VERSION "HNNBNNNYNNNNNNNNNNNNNNNNNNNNNNNNNNNNNNNNNN/4/%%%/4/'%**4NNN///"

NS_ :

BS_:

BU_: BAP_Tester BMS_NV_12V Gateway_Max Klima

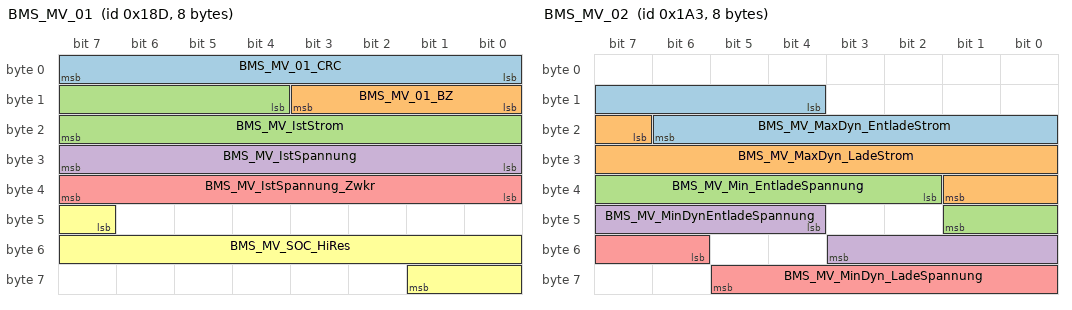
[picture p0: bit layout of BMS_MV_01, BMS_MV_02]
BO_ 397 BMS_MV_01: 8 Vector__XXX
 SG_ BMS_MV_01_CRC : 0|8@1+ (1,0) [0|255] ""  Gateway_Max
 SG_ BMS_MV_01_BZ : 8|4@1+ (1,0) [0|15] ""  Gateway_Max
 SG_ BMS_MV_IstStrom : 12|12@1+ (1,-2047) [-2047|2046] "Unit_Amper"  Gateway_Max
 SG_ BMS_MV_IstSpannung : 24|8@1+ (0.25,0) [0.00|63.25] "Unit_Volt"  Gateway_Max
 SG_ BMS_MV_IstSpannung_Zwkr : 32|8@1+ (0.25,0) [0.00|63.25] "Unit_Volt"  Gateway_Max
 SG_ BMS_MV_SOC_HiRes : 47|11@1+ (0.05,0) [0.00|100.00] "Unit_PerCent"  Gateway_Max

BO_ 419 BMS_MV_02: 8 Vector__XXX
 SG_ BMS_MV_MaxDyn_EntladeStrom : 12|11@1+ (1,0) [0|2045] "Unit_Amper"  Gateway_Max
 SG_ BMS_MV_MaxDyn_LadeStrom : 23|11@1+ (1,0) [0|2045] "Unit_Amper"  Gateway_Max
 SG_ BMS_MV_Min_EntladeSpannung : 34|8@1+ (0.25,0) [0.00|63.25] "Unit_Volt"  Gateway_Max
 SG_ BMS_MV_MinDynEntladeSpannung : 44|8@1+ (0.25,0) [0.00|63.25] "Unit_Volt"  Gateway_Max
 SG_ BMS_MV_MinDyn_LadeSpannung : 54|8@1+ (0.25,0) [0.00|63.25] "Unit_Volt"  Gateway_Max

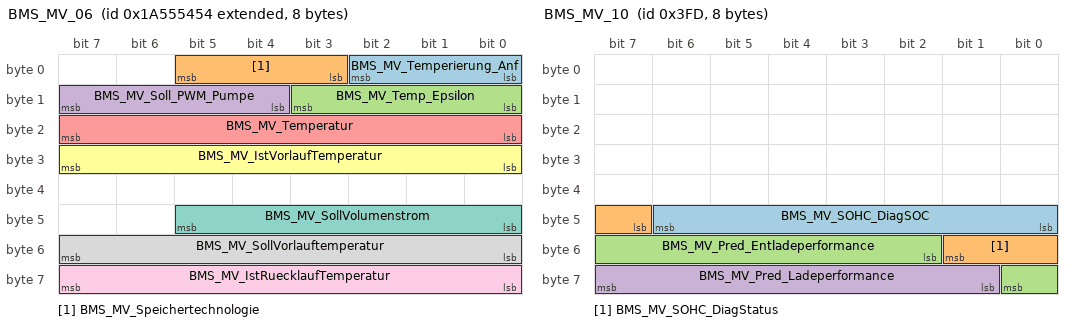
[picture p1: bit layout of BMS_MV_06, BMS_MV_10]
BO_ 2589283412 BMS_MV_06: 8 Vector__XXX
 SG_ BMS_MV_Temperierung_Anf : 0|3@1+ (1.0,0.0) [0.0|7] ""  Gateway_Max
 SG_ BMS_MV_Speichertechnologie : 3|3@1+ (1.0,0.0) [0.0|7] ""  Gateway_Max
 SG_ BMS_MV_Temp_Epsilon : 8|4@1+ (1,-15) [-15|0] "Unit_DegreCelsi"  Gateway_Max
 SG_ BMS_MV_Soll_PWM_Pumpe : 12|4@1+ (10,0) [0|100] "Unit_PerCent"  Gateway_Max
 SG_ BMS_MV_Temperatur : 16|8@1+ (0.5,-40) [-40.0|86.5] "Unit_DegreCelsi"  Gateway_Max
 SG_ BMS_MV_IstVorlaufTemperatur : 24|8@1+ (0.5,-40) [-40.0|86.5] "Unit_DegreCelsi"  Gateway_Max
 SG_ BMS_MV_SollVolumenstrom : 40|6@1+ (1,0) [0|61] ""  Gateway_Max
 SG_ BMS_MV_SollVorlauftemperatur : 48|8@1+ (0.5,-40) [-40.0|86.5] "Unit_DegreCelsi"  Gateway_Max
 SG_ BMS_MV_IstRuecklaufTemperatur : 56|8@1+ (0.5,-40) [-40.0|86.5] "Unit_DegreCelsi"  Gateway_Max

BO_ 2589283608 BMS_MV_07: 8 Vector__XXX
 SG_ BMS_MV_Energieinhalt : 12|11@1+ (1,0) [0|2045] "Unit_WattHour"  Gateway_Max
 SG_ BMS_MV_MaxEnergieinhalt : 32|11@1+ (1,0) [0|2045] "Unit_WattHour"  Gateway_Max

BO_ 2589283606 BMS_MV_09: 8 Vector__XXX
 SG_ BMS_MV_SOC_Kaltstart : 43|11@1+ (0.05,0) [0.00|100.00] "Unit_PerCent"  Gateway_Max
 SG_ BMS_MV_max_Grenz_SOC : 54|5@1+ (1,70) [70|100] "Unit_PerCent"  Gateway_Max

BO_ 1021 BMS_MV_10: 8 Vector__XXX
 SG_ BMS_MV_SOHC_DiagSOC : 40|7@1+ (1,0) [0|100] "Unit_PerCent"  Gateway_Max
 SG_ BMS_MV_SOHC_DiagStatus : 47|3@1+ (1.0,0.0) [0.0|7] ""  Gateway_Max
 SG_ BMS_MV_Pred_Entladeperformance : 50|7@1+ (1,0) [0|100] "Unit_PerCent"  Gateway_Max
 SG_ BMS_MV_Pred_Ladeperformance : 57|7@1+ (1,0) [0|100] "Unit_PerCent"  Gateway_Max

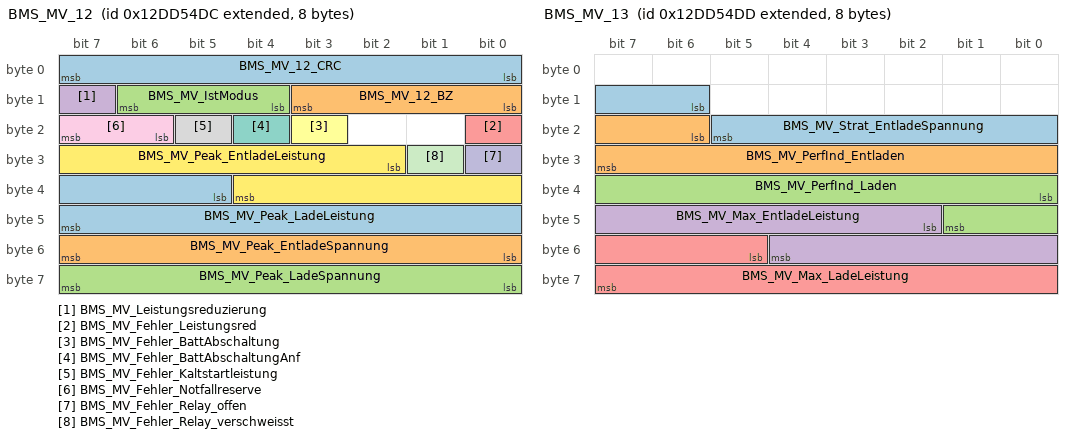
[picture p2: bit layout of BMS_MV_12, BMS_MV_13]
BO_ 2463978716 BMS_MV_12: 8 Vector__XXX
 SG_ BMS_MV_12_CRC : 0|8@1+ (1,0) [0|255] ""  Gateway_Max
 SG_ BMS_MV_12_BZ : 8|4@1+ (1,0) [0|15] ""  Gateway_Max
 SG_ BMS_MV_IstModus : 12|3@1+ (1.0,0.0) [0.0|7] ""  Gateway_Max
 SG_ BMS_MV_Leistungsreduzierung : 15|1@1+ (1.0,0.0) [0.0|1] ""  Gateway_Max
 SG_ BMS_MV_Fehler_Leistungsred : 16|1@1+ (1.0,0.0) [0.0|1] ""  Gateway_Max
 SG_ BMS_MV_Fehler_BattAbschaltung : 19|1@1+ (1.0,0.0) [0.0|1] ""  Gateway_Max
 SG_ BMS_MV_Fehler_BattAbschaltungAnf : 20|1@1+ (1.0,0.0) [0.0|1] ""  Gateway_Max
 SG_ BMS_MV_Fehler_Kaltstartleistung : 21|1@1+ (1.0,0.0) [0.0|1] ""  Gateway_Max
 SG_ BMS_MV_Fehler_Notfallreserve : 22|2@1+ (1.0,0.0) [0.0|3] ""  Gateway_Max
 SG_ BMS_MV_Fehler_Relay_offen : 24|1@1+ (1.0,0.0) [0.0|1] ""  Gateway_Max
 SG_ BMS_MV_Fehler_Relay_verschweisst : 25|1@1+ (1.0,0.0) [0.0|1] ""  Gateway_Max
 SG_ BMS_MV_Peak_EntladeLeistung : 26|11@1+ (50,0) [0|102250] "Unit_Watt"  Gateway_Max
 SG_ BMS_MV_Peak_LadeLeistung : 37|11@1+ (50,0) [0|102250] "Unit_Watt"  Gateway_Max
 SG_ BMS_MV_Peak_EntladeSpannung : 48|8@1+ (0.25,0) [0.00|63.25] "Unit_Volt"  Gateway_Max
 SG_ BMS_MV_Peak_LadeSpannung : 56|8@1+ (0.25,0) [0.00|63.25] "Unit_Volt"  Gateway_Max

BO_ 2463978717 BMS_MV_13: 8 Vector__XXX
 SG_ BMS_MV_Strat_EntladeSpannung : 14|8@1+ (0.25,0) [0.00|63.25] "Unit_Volt"  Gateway_Max
 SG_ BMS_MV_PerfInd_Entladen : 22|10@1+ (0.2,0) [0.0|200.0] "Unit_PerCent"  Gateway_Max
 SG_ BMS_MV_PerfInd_Laden : 32|10@1+ (0.2,0) [0.0|200.0] "Unit_PerCent"  Gateway_Max
 SG_ BMS_MV_Max_EntladeLeistung : 42|11@1+ (50,0) [0|102250] "Unit_Watt"  Gateway_Max
 SG_ BMS_MV_Max_LadeLeistung : 53|11@1+ (50,0) [0|102250] "Unit_Watt"  Gateway_Max

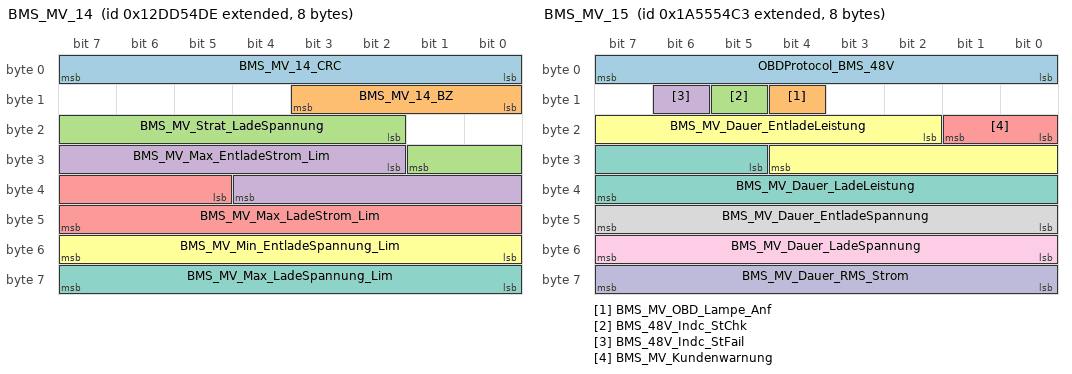
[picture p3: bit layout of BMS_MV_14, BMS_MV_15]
BO_ 2463978718 BMS_MV_14: 8 Vector__XXX
 SG_ BMS_MV_14_CRC : 0|8@1+ (1,0) [0|255] ""  Gateway_Max
 SG_ BMS_MV_14_BZ : 8|4@1+ (1,0) [0|15] ""  Gateway_Max
 SG_ BMS_MV_Strat_LadeSpannung : 18|8@1+ (0.25,0) [0.00|63.25] "Unit_Volt"  Gateway_Max
 SG_ BMS_MV_Max_EntladeStrom_Lim : 26|11@1+ (1,0) [0|2045] "Unit_Amper"  Gateway_Max
 SG_ BMS_MV_Max_LadeStrom_Lim : 37|11@1+ (1,0) [0|2045] "Unit_Amper"  Gateway_Max
 SG_ BMS_MV_Min_EntladeSpannung_Lim : 48|8@1+ (0.25,0) [0.00|63.25] "Unit_Volt"  Gateway_Max
 SG_ BMS_MV_Max_LadeSpannung_Lim : 56|8@1+ (0.25,0) [0.00|63.25] "Unit_Volt"  Gateway_Max

BO_ 2589283523 BMS_MV_15: 8 Vector__XXX
 SG_ OBDProtocol_BMS_48V : 0|8@1+ (1.0,0.0) [0.0|255] ""  Gateway_Max
 SG_ BMS_MV_OBD_Lampe_Anf : 12|1@1+ (1.0,0.0) [0.0|1] ""  Gateway_Max
 SG_ BMS_48V_Indc_StChk : 13|1@1+ (1.0,0.0) [0.0|1] ""  Gateway_Max
 SG_ BMS_48V_Indc_StFail : 14|1@1+ (1.0,0.0) [0.0|1] ""  Gateway_Max
 SG_ BMS_MV_Kundenwarnung : 16|2@1+ (1.0,0.0) [0.0|3] ""  Gateway_Max
 SG_ BMS_MV_Dauer_EntladeLeistung : 18|11@1+ (50,0) [0|102250] "Unit_Watt"  Gateway_Max
 SG_ BMS_MV_Dauer_LadeLeistung : 29|11@1+ (50,0) [0|102250] "Unit_Watt"  Gateway_Max
 SG_ BMS_MV_Dauer_EntladeSpannung : 40|8@1+ (0.25,0) [0.00|63.25] "Unit_Volt"  Gateway_Max
 SG_ BMS_MV_Dauer_LadeSpannung : 48|8@1+ (0.25,0) [0.00|63.25] "Unit_Volt"  Gateway_Max
 SG_ BMS_MV_Dauer_RMS_Strom : 56|8@1+ (1,0) [0|253] "Unit_Amper"  Gateway_Max

BO_ 2589283543 BMS_MV_15_SOK_Signatur: 8 Vector__XXX
 SG_ SOK_BMS_MV_15_Signatur : 0|64@1+ (1,0) [1|18446744073709551615] "Unit_None"  Gateway_Max

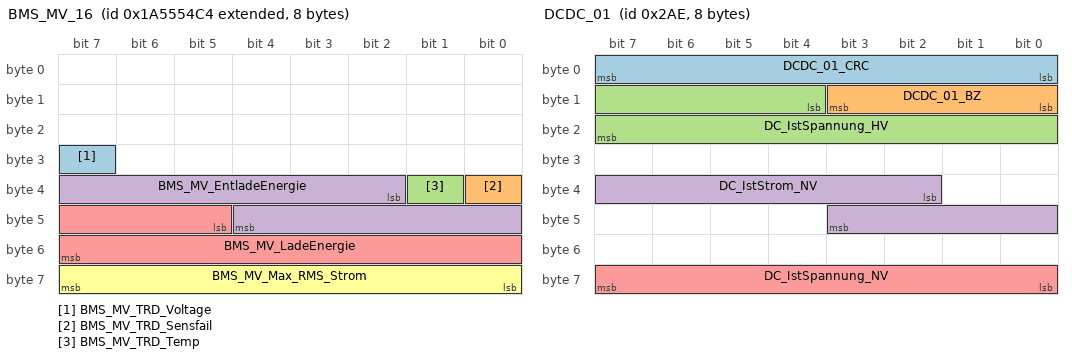
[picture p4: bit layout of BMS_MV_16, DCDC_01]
BO_ 2589283524 BMS_MV_16: 8 Vector__XXX
 SG_ BMS_MV_TRD_Voltage : 31|1@1+ (1.0,0.0) [0.0|1] ""  Gateway_Max
 SG_ BMS_MV_TRD_Sensfail : 32|1@1+ (1.0,0.0) [0.0|1] ""  Gateway_Max
 SG_ BMS_MV_TRD_Temp : 33|1@1+ (1.0,0.0) [0.0|1] ""  Gateway_Max
 SG_ BMS_MV_EntladeEnergie : 34|11@1+ (5,-5110) [-5110|5115] "Unit_WattHour"  Gateway_Max
 SG_ BMS_MV_LadeEnergie : 45|11@1+ (5,-5110) [-5110|5115] "Unit_WattHour"  Gateway_Max
 SG_ BMS_MV_Max_RMS_Strom : 56|8@1+ (1,0) [0|253] "Unit_Amper"  Gateway_Max

BO_ 2527679928 BMS_NV_11: 16 BMS_NV_12V
 SG_ BMS_NV_OBD_Lampe_Anf : 12|1@1+ (1.0,0.0) [0.0|1] ""  Gateway_Max
 SG_ BMS_NV_Indc_StChk : 13|1@1+ (1.0,0.0) [0.0|1] ""  Gateway_Max
 SG_ BMS_NV_Indc_StFail : 14|1@1+ (1.0,0.0) [0.0|1] ""  Gateway_Max
 SG_ OBDProtocol_BMS_NV : 16|8@1+ (1.0,0.0) [0.0|255] ""  Gateway_Max
 SG_ SOK_BMS_NV_11_Signatur : 64|64@1+ (1,0) [1|18446744073709551615] "Unit_None"  Gateway_Max

BO_ 2617128448 CCP_Klima_CRO_01: 8 Vector__XXX
 SG_ CCP_Klima_CRO_01_Data : 0|64@1+ (1,0) [0|1] ""  Klima

BO_ 2617128450 CCP_Klima_CRO_02: 8 Vector__XXX
 SG_ CCP_Klima_CRO_02_Data : 0|64@1+ (1,0) [0|1] ""  Klima

BO_ 2617128449 CCP_Klima_DTO_01: 8 Klima
 SG_ CCP_Klima_DTO_01_Data : 0|64@1+ (1,0) [0|1] ""  Vector__XXX

BO_ 902 Charisma_03: 8 Gateway_Max
 SG_ CHA_Charisma_Taste2_LED : 0|2@1+ (1.0,0.0) [0.0|3] ""  Vector__XXX
 SG_ CHA_ReqPrgDispSetup : 2|4@1+ (1.0,0.0) [0.0|15] ""  Vector__XXX
 SG_ CHA_Current_Mode_FPA : 6|6@1+ (1.0,0.0) [0.0|63] ""  Vector__XXX
 SG_ CHA_Eco_Charisma_LED : 12|2@1+ (1.0,0.0) [0.0|3] ""  Vector__XXX
 SG_ CHA_Fahrer_Umschaltung : 14|1@1+ (1.0,0.0) [0.0|1] ""  Klima
 SG_ CHA_EV_LED : 15|1@1+ (1.0,0.0) [0.0|1] ""  Vector__XXX
 SG_ CHA_Ziel_FahrPr_AMB : 16|4@1+ (1.0,0.0) [0.0|15] ""  Vector__XXX
 SG_ CHA_Ziel_FahrPr_IVB : 20|4@1+ (1.0,0.0) [0.0|15] ""  Vector__XXX
 SG_ CHA_Kombi_Texte : 24|4@1+ (1.0,0.0) [0.0|15] ""  Vector__XXX
 SG_ CHA_Ziel_FahrPr_KL : 28|4@1+ (1.0,0.0) [0.0|15] ""  Klima
 SG_ CHA_Ziel_FahrPr_HSP : 32|4@1+ (1.0,0.0) [0.0|15] ""  Vector__XXX
 SG_ CHA_StCurProfDft : 36|2@1+ (1.0,0.0) [0.0|3] ""  Vector__XXX
 SG_ CHA_Ziel_FahrPr_RWB : 40|4@1+ (1.0,0.0) [0.0|15] ""  Vector__XXX
 SG_ CHA_Ziel_FahrPr_03_01 : 44|4@1+ (1.0,0.0) [0.0|15] ""  Vector__XXX
 SG_ CHA_Ziel_FahrPr_03_02 : 48|4@1+ (1.0,0.0) [0.0|15] ""  Vector__XXX
 SG_ CHA_Current_Mode : 52|4@1+ (1.0,0.0) [0.0|15] ""  Vector__XXX
 SG_ CHA_Charge_LED : 57|1@1+ (1.0,0.0) [0.0|1] ""  Vector__XXX
 SG_ CHA_Offroad_LED : 58|2@1+ (1.0,0.0) [0.0|3] ""  Vector__XXX
 SG_ CHA_Kombi_Texte_02 : 60|4@1+ (1.0,0.0) [0.0|15] ""  Vector__XXX

BO_ 686 DCDC_01: 8 Vector__XXX
 SG_ DCDC_01_CRC : 0|8@1+ (1,0) [0|255] ""  Gateway_Max
 SG_ DCDC_01_BZ : 8|4@1+ (1,0) [0|15] ""  Gateway_Max
 SG_ DC_IstSpannung_HV : 12|12@1+ (0.25,0) [0.00|1023.25] "Unit_Volt"  Gateway_Max
 SG_ DC_IstStrom_NV : 34|10@1+ (1,-511) [-511|510] "Unit_Amper"  Gateway_Max
 SG_ DC_IstSpannung_NV : 56|8@1+ (0.1,0) [0.0|25.3] "Unit_Volt"  Gateway_Max

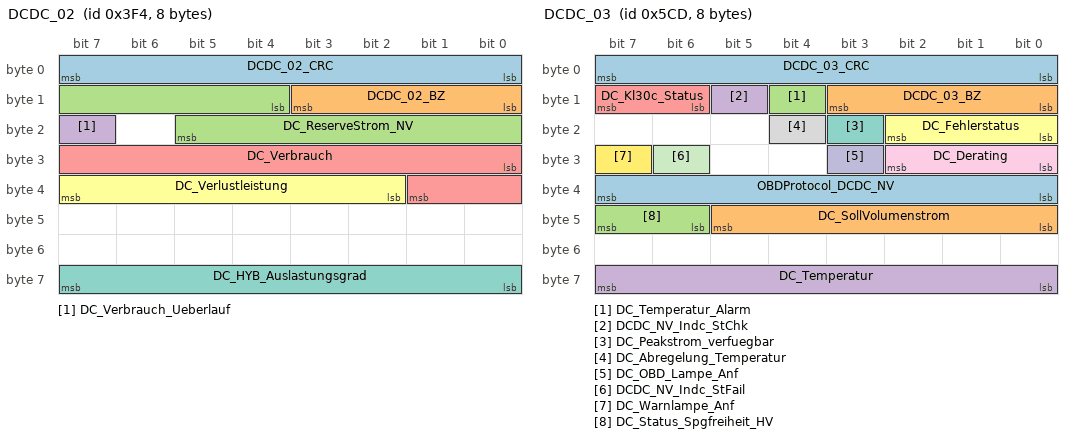
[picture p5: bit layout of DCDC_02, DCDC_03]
BO_ 1012 DCDC_02: 8 Vector__XXX
 SG_ DCDC_02_CRC : 0|8@1+ (1,0) [0|255] ""  Gateway_Max
 SG_ DCDC_02_BZ : 8|4@1+ (1,0) [0|15] ""  Gateway_Max
 SG_ DC_ReserveStrom_NV : 12|10@1+ (1,-511) [-511|510] "Unit_Amper"  Gateway_Max
 SG_ DC_Verbrauch_Ueberlauf : 23|1@1+ (1.0,0.0) [0.0|1] ""  Gateway_Max
 SG_ DC_Verbrauch : 24|10@1+ (1,0) [0|1023] "Unit_WattSecond"  Gateway_Max
 SG_ DC_Verlustleistung : 34|6@1+ (5,0) [0|305] "Unit_Watt"  Gateway_Max
 SG_ DC_HYB_Auslastungsgrad : 56|8@1+ (0.4,0) [0.0|100.0] "Unit_PerCent"  Gateway_Max

BO_ 1485 DCDC_03: 8 Vector__XXX
 SG_ DCDC_03_CRC : 0|8@1+ (1,0) [0|255] ""  Gateway_Max
 SG_ DCDC_03_BZ : 8|4@1+ (1,0) [0|15] ""  Gateway_Max
 SG_ DC_Temperatur_Alarm : 12|1@1+ (1.0,0.0) [0.0|1] ""  Gateway_Max
 SG_ DCDC_NV_Indc_StChk : 13|1@1+ (1.0,0.0) [0.0|1] ""  Gateway_Max
 SG_ DC_Kl30c_Status : 14|2@1+ (1.0,0.0) [0.0|3] ""  Gateway_Max
 SG_ DC_Fehlerstatus : 16|3@1+ (1.0,0.0) [0.0|7] ""  Gateway_Max
 SG_ DC_Peakstrom_verfuegbar : 19|1@1+ (1.0,0.0) [0.0|1] ""  Gateway_Max
 SG_ DC_Abregelung_Temperatur : 20|1@1+ (1.0,0.0) [0.0|1] ""  Gateway_Max
 SG_ DC_Derating : 24|3@1+ (1.0,0.0) [0.0|7] ""  Gateway_Max
 SG_ DC_OBD_Lampe_Anf : 27|1@1+ (1.0,0.0) [0.0|1] ""  Gateway_Max
 SG_ DCDC_NV_Indc_StFail : 30|1@1+ (1.0,0.0) [0.0|1] ""  Gateway_Max
 SG_ DC_Warnlampe_Anf : 31|1@1+ (1.0,0.0) [0.0|1] ""  Gateway_Max
 SG_ OBDProtocol_DCDC_NV : 32|8@1+ (1.0,0.0) [0.0|255] ""  Gateway_Max
 SG_ DC_SollVolumenstrom : 40|6@1+ (0.5,0) [0.0|30.5] "Unit_LiterPerMinut"  Gateway_Max
 SG_ DC_Status_Spgfreiheit_HV : 46|2@1+ (1.0,0.0) [0.0|3] ""  Gateway_Max
 SG_ DC_Temperatur : 56|8@1+ (1,-40) [-40|213] "Unit_DegreCelsi"  Gateway_Max

BO_ 1486 DCDC_03_SOK_Signatur: 8 Vector__XXX
 SG_ SOK_DCDC_03_Signatur : 0|64@1+ (1,0) [1|18446744073709551615] "Unit_None"  Gateway_Max

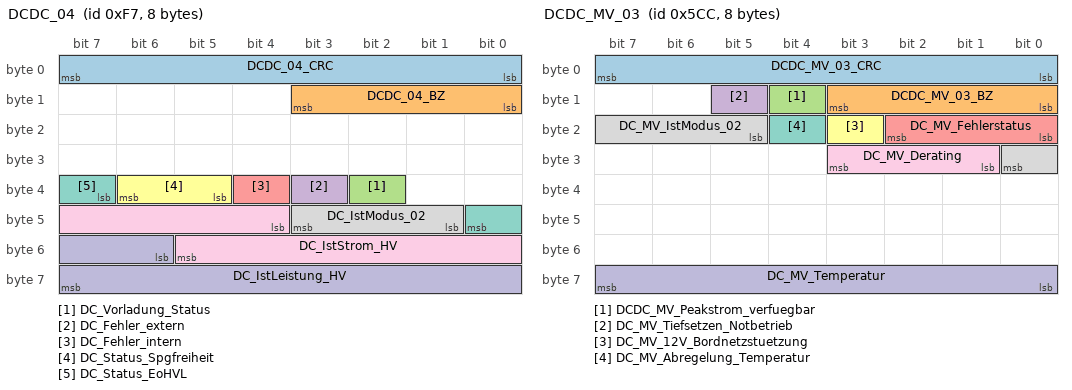
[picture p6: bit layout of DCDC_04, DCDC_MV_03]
BO_ 247 DCDC_04: 8 Vector__XXX
 SG_ DCDC_04_CRC : 0|8@1+ (1,0) [0|255] ""  Gateway_Max
 SG_ DCDC_04_BZ : 8|4@1+ (1,0) [0|15] ""  Gateway_Max
 SG_ DC_Vorladung_Status : 34|1@1+ (1.0,0.0) [0.0|1] ""  Gateway_Max
 SG_ DC_Fehler_extern : 35|1@1+ (1.0,0.0) [0.0|1] ""  Gateway_Max
 SG_ DC_Fehler_intern : 36|1@1+ (1.0,0.0) [0.0|1] ""  Gateway_Max
 SG_ DC_Status_Spgfreiheit : 37|2@1+ (1.0,0.0) [0.0|3] ""  Gateway_Max
 SG_ DC_Status_EoHVL : 39|2@1+ (1.0,0.0) [0.0|3] ""  Gateway_Max
 SG_ DC_IstModus_02 : 41|3@1+ (1.0,0.0) [0.0|7] ""  Gateway_Max
 SG_ DC_IstStrom_HV : 44|10@1+ (0.1,-51.1) [-51.1|51.0] "Unit_Amper"  Gateway_Max
 SG_ DC_IstLeistung_HV : 54|10@1+ (10,-4000) [-4000|6210] "Unit_Watt"  Gateway_Max

BO_ 1484 DCDC_MV_03: 8 Vector__XXX
 SG_ DCDC_MV_03_CRC : 0|8@1+ (1,0) [0|255] ""  Gateway_Max
 SG_ DCDC_MV_03_BZ : 8|4@1+ (1,0) [0|15] ""  Gateway_Max
 SG_ DCDC_MV_Peakstrom_verfuegbar : 12|1@1+ (1.0,0.0) [0.0|1] ""  Gateway_Max
 SG_ DC_MV_Tiefsetzen_Notbetrieb : 13|1@1+ (1.0,0.0) [0.0|1] ""  Gateway_Max
 SG_ DC_MV_Fehlerstatus : 16|3@1+ (1.0,0.0) [0.0|7] ""  Gateway_Max
 SG_ DC_MV_12V_Bordnetzstuetzung : 19|1@1+ (1.0,0.0) [0.0|1] ""  Gateway_Max
 SG_ DC_MV_Abregelung_Temperatur : 20|1@1+ (1.0,0.0) [0.0|1] ""  Gateway_Max
 SG_ DC_MV_IstModus_02 : 21|4@1+ (1.0,0.0) [0.0|15] ""  Gateway_Max
 SG_ DC_MV_Derating : 25|3@1+ (1.0,0.0) [0.0|7] ""  Gateway_Max
 SG_ DC_MV_Temperatur : 56|8@1+ (1,-40) [-40|213] "Unit_DegreCelsi"  Gateway_Max

BO_ 2617127464 DEV_Klima_BET_Req_01: 8 Vector__XXX
 SG_ DEV_Klima_BET_Req_01_Data : 0|64@1+ (1.0,0.0) [0.0|18446744073709551615] ""  Klima

BO_ 2617127465 DEV_Klima_BET_Resp_01: 8 Klima
 SG_ DEV_Klima_BET_Resp_01_Data : 0|64@1+ (1.0,0.0) [0.0|18446744073709551615] ""  Vector__XXX

BO_ 2617127424 DEV_Klima_Tx_00: 8 Klima
 SG_ DEV_Klima_Tx_00_Data : 0|64@1+ (1.0,0.0) [0.0|18446744073709551615] ""  Vector__XXX

BO_ 2617127425 DEV_Klima_Tx_01: 8 Klima
 SG_ DEV_Klima_Tx_01_Data : 0|64@1+ (1.0,0.0) [0.0|18446744073709551615] ""  Vector__XXX

BO_ 2617127426 DEV_Klima_Tx_02: 8 Klima
 SG_ DEV_Klima_Tx_02_Data : 0|64@1+ (1.0,0.0) [0.0|18446744073709551615] ""  Vector__XXX

BO_ 2617127427 DEV_Klima_Tx_03: 8 Klima
 SG_ DEV_Klima_Tx_03_Data : 0|64@1+ (1.0,0.0) [0.0|18446744073709551615] ""  Vector__XXX

BO_ 2617127428 DEV_Klima_Tx_04: 8 Klima
 SG_ DEV_Klima_Tx_04_Data : 0|64@1+ (1.0,0.0) [0.0|18446744073709551615] ""  Vector__XXX

BO_ 2617127429 DEV_Klima_Tx_05: 8 Klima
 SG_ DEV_Klima_Tx_05_Data : 0|64@1+ (1.0,0.0) [0.0|18446744073709551615] ""  Vector__XXX

BO_ 2617127430 DEV_Klima_Tx_06: 8 Klima
 SG_ DEV_Klima_Tx_06_Data : 0|64@1+ (1.0,0.0) [0.0|18446744073709551615] ""  Vector__XXX

BO_ 2617127431 DEV_Klima_Tx_07: 8 Klima
 SG_ DEV_Klima_Tx_07_Data : 0|64@1+ (1.0,0.0) [0.0|18446744073709551615] ""  Vector__XXX

BO_ 2617127432 DEV_Klima_Tx_08: 8 Klima
 SG_ DEV_Klima_Tx_08_Data : 0|64@1+ (1.0,0.0) [0.0|18446744073709551615] ""  Vector__XXX

BO_ 2617127433 DEV_Klima_Tx_09: 8 Klima
 SG_ DEV_Klima_Tx_09_Data : 0|64@1+ (1.0,0.0) [0.0|18446744073709551615] ""  Vector__XXX

BO_ 2617127434 DEV_Klima_Tx_0A: 8 Klima
 SG_ DEV_Klima_Tx_0A_Data : 0|64@1+ (1.0,0.0) [0.0|18446744073709551615] ""  Vector__XXX

BO_ 2617127435 DEV_Klima_Tx_0B: 8 Klima
 SG_ DEV_Klima_Tx_0B_Data : 0|64@1+ (1.0,0.0) [0.0|18446744073709551615] ""  Vector__XXX

BO_ 2617127436 DEV_Klima_Tx_0C: 8 Klima
 SG_ DEV_Klima_Tx_0C_Data : 0|64@1+ (1.0,0.0) [0.0|18446744073709551615] ""  Vector__XXX

BO_ 2617127437 DEV_Klima_Tx_0D: 8 Klima
 SG_ DEV_Klima_Tx_0D_Data : 0|64@1+ (1.0,0.0) [0.0|18446744073709551615] ""  Vector__XXX

BO_ 2617127438 DEV_Klima_Tx_0E: 8 Klima
 SG_ DEV_Klima_Tx_0E_Data : 0|64@1+ (1.0,0.0) [0.0|18446744073709551615] ""  Vector__XXX

BO_ 2617127439 DEV_Klima_Tx_0F: 8 Klima
 SG_ DEV_Klima_Tx_0F_Data : 0|64@1+ (1.0,0.0) [0.0|18446744073709551615] ""  Vector__XXX

BO_ 2617127440 DEV_Klima_Tx_10: 8 Klima
 SG_ DEV_Klima_Tx_10_Data : 0|64@1+ (1.0,0.0) [0.0|18446744073709551615] ""  Vector__XXX

BO_ 2617127441 DEV_Klima_Tx_11: 8 Klima
 SG_ DEV_Klima_Tx_11_Data : 0|64@1+ (1.0,0.0) [0.0|18446744073709551615] ""  Vector__XXX

BO_ 2617127442 DEV_Klima_Tx_12: 8 Klima
 SG_ DEV_Klima_Tx_12_Data : 0|64@1+ (1.0,0.0) [0.0|18446744073709551615] ""  Vector__XXX

BO_ 2617127443 DEV_Klima_Tx_13: 8 Klima
 SG_ DEV_Klima_Tx_13_Data : 0|64@1+ (1.0,0.0) [0.0|18446744073709551615] ""  Vector__XXX

BO_ 2617127444 DEV_Klima_Tx_14: 8 Klima
 SG_ DEV_Klima_Tx_14_Data : 0|64@1+ (1.0,0.0) [0.0|18446744073709551615] ""  Vector__XXX

BO_ 2617127445 DEV_Klima_Tx_15: 8 Klima
 SG_ DEV_Klima_Tx_15_Data : 0|64@1+ (1.0,0.0) [0.0|18446744073709551615] ""  Vector__XXX

BO_ 2617127446 DEV_Klima_Tx_16: 8 Klima
 SG_ DEV_Klima_Tx_16_Data : 0|64@1+ (1.0,0.0) [0.0|18446744073709551615] ""  Vector__XXX

BO_ 2617127447 DEV_Klima_Tx_17: 8 Klima
 SG_ DEV_Klima_Tx_17_Data : 0|64@1+ (1.0,0.0) [0.0|18446744073709551615] ""  Vector__XXX

BO_ 2617127448 DEV_Klima_Tx_18: 8 Klima
 SG_ DEV_Klima_Tx_18_Data : 0|64@1+ (1.0,0.0) [0.0|18446744073709551615] ""  Vector__XXX

BO_ 2617127449 DEV_Klima_Tx_19: 8 Klima
 SG_ DEV_Klima_Tx_19_Data : 0|64@1+ (1.0,0.0) [0.0|18446744073709551615] ""  Vector__XXX

BO_ 2617127450 DEV_Klima_Tx_1A: 8 Klima
 SG_ DEV_Klima_Tx_1A_Data : 0|64@1+ (1.0,0.0) [0.0|18446744073709551615] ""  Vector__XXX

BO_ 2617127451 DEV_Klima_Tx_1B: 8 Klima
 SG_ DEV_Klima_Tx_1B_Data : 0|64@1+ (1.0,0.0) [0.0|18446744073709551615] ""  Vector__XXX

BO_ 2617127452 DEV_Klima_Tx_1C: 8 Klima
 SG_ DEV_Klima_Tx_1C_Data : 0|64@1+ (1.0,0.0) [0.0|18446744073709551615] ""  Vector__XXX

BO_ 2617127453 DEV_Klima_Tx_1D: 8 Klima
 SG_ DEV_Klima_Tx_1D_Data : 0|64@1+ (1.0,0.0) [0.0|18446744073709551615] ""  Vector__XXX

BO_ 2617127454 DEV_Klima_Tx_1E: 8 Klima
 SG_ DEV_Klima_Tx_1E_Data : 0|64@1+ (1.0,0.0) [0.0|18446744073709551615] ""  Vector__XXX

BO_ 2617127455 DEV_Klima_Tx_1F: 8 Klima
 SG_ DEV_Klima_Tx_1F_Data : 0|64@1+ (1.0,0.0) [0.0|18446744073709551615] ""  Vector__XXX

BO_ 2617127456 DEV_Klima_Tx_20: 8 Klima
 SG_ DEV_Klima_Tx_20_Data : 0|64@1+ (1.0,0.0) [0.0|18446744073709551615] ""  Vector__XXX

BO_ 2617127457 DEV_Klima_Tx_21: 8 Klima
 SG_ DEV_Klima_Tx_21_Data : 0|64@1+ (1.0,0.0) [0.0|18446744073709551615] ""  Vector__XXX

BO_ 2617127458 DEV_Klima_Tx_22: 8 Klima
 SG_ DEV_Klima_Tx_22_Data : 0|64@1+ (1.0,0.0) [0.0|18446744073709551615] ""  Vector__XXX

BO_ 2617127459 DEV_Klima_Tx_23: 8 Klima
 SG_ DEV_Klima_Tx_23_Data : 0|64@1+ (1.0,0.0) [0.0|18446744073709551615] ""  Vector__XXX

BO_ 2617127460 DEV_Klima_Tx_24: 8 Klima
 SG_ DEV_Klima_Tx_24_Data : 0|64@1+ (1.0,0.0) [0.0|18446744073709551615] ""  Vector__XXX

BO_ 2617127461 DEV_Klima_Tx_25: 8 Klima
 SG_ DEV_Klima_Tx_25_Data : 0|64@1+ (1.0,0.0) [0.0|18446744073709551615] ""  Vector__XXX

BO_ 2617127462 DEV_Klima_Tx_26: 8 Klima
 SG_ DEV_Klima_Tx_26_Data : 0|64@1+ (1.0,0.0) [0.0|18446744073709551615] ""  Vector__XXX

BO_ 2617127463 DEV_Klima_Tx_27: 8 Klima
 SG_ DEV_Klima_Tx_27_Data : 0|64@1+ (1.0,0.0) [0.0|18446744073709551615] ""  Vector__XXX

BO_ 2617127468 DEV_Klima_Tx_2C: 8 Klima
 SG_ DEV_Klima_Tx_2C_Data : 0|64@1+ (1.0,0.0) [0.0|18446744073709551615] ""  Vector__XXX

BO_ 2617127469 DEV_Klima_Tx_2D: 8 Klima
 SG_ DEV_Klima_Tx_2D_Data : 0|64@1+ (1.0,0.0) [0.0|18446744073709551615] ""  Vector__XXX

BO_ 2617127470 DEV_Klima_Tx_2E: 8 Klima
 SG_ DEV_Klima_Tx_2E_Data : 0|64@1+ (1.0,0.0) [0.0|18446744073709551615] ""  Vector__XXX

BO_ 2617127471 DEV_Klima_Tx_2F: 8 Klima
 SG_ DEV_Klima_Tx_2F_Data : 0|64@1+ (1.0,0.0) [0.0|18446744073709551615] ""  Vector__XXX

BO_ 2617127472 DEV_Klima_Tx_30: 8 Klima
 SG_ DEV_Klima_Tx_30_Data : 0|64@1+ (1.0,0.0) [0.0|18446744073709551615] ""  Vector__XXX

BO_ 2617127473 DEV_Klima_Tx_31: 8 Klima
 SG_ DEV_Klima_Tx_31_Data : 0|64@1+ (1.0,0.0) [0.0|18446744073709551615] ""  Vector__XXX

BO_ 2617127474 DEV_Klima_Tx_32: 8 Klima
 SG_ DEV_Klima_Tx_32_Data : 0|64@1+ (1.0,0.0) [0.0|18446744073709551615] ""  Vector__XXX

BO_ 2617127475 DEV_Klima_Tx_33: 8 Klima
 SG_ DEV_Klima_Tx_33_Data : 0|64@1+ (1.0,0.0) [0.0|18446744073709551615] ""  Vector__XXX

BO_ 2617127476 DEV_Klima_Tx_34: 8 Klima
 SG_ DEV_Klima_Tx_34_Data : 0|64@1+ (1.0,0.0) [0.0|18446744073709551615] ""  Vector__XXX

BO_ 2617127477 DEV_Klima_Tx_35: 8 Klima
 SG_ DEV_Klima_Tx_35_Data : 0|64@1+ (1.0,0.0) [0.0|18446744073709551615] ""  Vector__XXX

BO_ 2617127478 DEV_Klima_Tx_36: 8 Klima
 SG_ DEV_Klima_Tx_36_Data : 0|64@1+ (1.0,0.0) [0.0|18446744073709551615] ""  Vector__XXX

BO_ 2617127479 DEV_Klima_Tx_37: 8 Klima
 SG_ DEV_Klima_Tx_37_Data : 0|64@1+ (1.0,0.0) [0.0|18446744073709551615] ""  Vector__XXX

BO_ 2617127480 DEV_Klima_Tx_38: 8 Klima
 SG_ DEV_Klima_Tx_38_Data : 0|64@1+ (1.0,0.0) [0.0|18446744073709551615] ""  Vector__XXX

BO_ 2617127481 DEV_Klima_Tx_39: 8 Klima
 SG_ DEV_Klima_Tx_39_Data : 0|64@1+ (1.0,0.0) [0.0|18446744073709551615] ""  Vector__XXX

BO_ 2617127482 DEV_Klima_Tx_3A: 8 Klima
 SG_ DEV_Klima_Tx_3A_Data : 0|64@1+ (1.0,0.0) [0.0|18446744073709551615] ""  Vector__XXX

BO_ 2617127483 DEV_Klima_Tx_3B: 8 Klima
 SG_ DEV_Klima_Tx_3B_Data : 0|64@1+ (1.0,0.0) [0.0|18446744073709551615] ""  Vector__XXX

BO_ 2617127484 DEV_Klima_Tx_3C: 8 Klima
 SG_ DEV_Klima_Tx_3C_Data : 0|64@1+ (1.0,0.0) [0.0|18446744073709551615] ""  Vector__XXX

BO_ 2617127485 DEV_Klima_Tx_3D: 8 Klima
 SG_ DEV_Klima_Tx_3D_Data : 0|64@1+ (1.0,0.0) [0.0|18446744073709551615] ""  Vector__XXX

BO_ 2617127486 DEV_Klima_Tx_3E: 8 Klima
 SG_ DEV_Klima_Tx_3E_Data : 0|64@1+ (1.0,0.0) [0.0|18446744073709551615] ""  Vector__XXX

BO_ 2617127487 DEV_Klima_Tx_3F: 8 Klima
 SG_ DEV_Klima_Tx_3F_Data : 0|64@1+ (1.0,0.0) [0.0|18446744073709551615] ""  Vector__XXX

BO_ 2617127488 DEV_Klima_Tx_40: 8 Klima
 SG_ DEV_Klima_Tx_40_Data : 0|64@1+ (1.0,0.0) [0.0|18446744073709551615] ""  Vector__XXX

BO_ 2617127489 DEV_Klima_Tx_41: 8 Klima
 SG_ DEV_Klima_Tx_41_Data : 0|64@1+ (1.0,0.0) [0.0|18446744073709551615] ""  Vector__XXX

BO_ 2617127490 DEV_Klima_Tx_42: 8 Klima
 SG_ DEV_Klima_Tx_42_Data : 0|64@1+ (1.0,0.0) [0.0|18446744073709551615] ""  Vector__XXX

BO_ 2617127491 DEV_Klima_Tx_43: 8 Klima
 SG_ DEV_Klima_Tx_43_Data : 0|64@1+ (1.0,0.0) [0.0|18446744073709551615] ""  Vector__XXX

BO_ 2617127492 DEV_Klima_Tx_44: 8 Klima
 SG_ DEV_Klima_Tx_44_Data : 0|64@1+ (1.0,0.0) [0.0|18446744073709551615] ""  Vector__XXX

BO_ 2617127493 DEV_Klima_Tx_45: 8 Klima
 SG_ DEV_Klima_Tx_45_Data : 0|64@1+ (1.0,0.0) [0.0|18446744073709551615] ""  Vector__XXX

BO_ 2617127494 DEV_Klima_Tx_46: 8 Klima
 SG_ DEV_Klima_Tx_46_Data : 0|64@1+ (1.0,0.0) [0.0|18446744073709551615] ""  Vector__XXX

BO_ 2617127495 DEV_Klima_Tx_47: 8 Klima
 SG_ DEV_Klima_Tx_47_Data : 0|64@1+ (1.0,0.0) [0.0|18446744073709551615] ""  Vector__XXX

BO_ 2617127496 DEV_Klima_Tx_48: 8 Klima
 SG_ DEV_Klima_Tx_48_Data : 0|64@1+ (1.0,0.0) [0.0|18446744073709551615] ""  Vector__XXX

BO_ 2617127497 DEV_Klima_Tx_49: 8 Klima
 SG_ DEV_Klima_Tx_49_Data : 0|64@1+ (1.0,0.0) [0.0|18446744073709551615] ""  Vector__XXX

BO_ 2617127498 DEV_Klima_Tx_4A: 8 Klima
 SG_ DEV_Klima_Tx_4A_Data : 0|64@1+ (1.0,0.0) [0.0|18446744073709551615] ""  Vector__XXX

BO_ 2617127499 DEV_Klima_Tx_4B: 64 Klima
 SG_ DEV_Klima_Tx_4B_Data : 0|512@1+ (1.0,0.0) [0.0|13407807929942597099574024998205846127479365820592393377723561443721764030073546976801874298166903427690031858186486050853753882811946569946433649006084095] ""  Vector__XXX

BO_ 2617127500 DEV_Klima_Tx_4C: 64 Klima
 SG_ DEV_Klima_Tx_4C_Data : 0|512@1+ (1.0,0.0) [0.0|13407807929942597099574024998205846127479365820592393377723561443721764030073546976801874298166903427690031858186486050853753882811946569946433649006084095] ""  Vector__XXX

BO_ 2617127501 DEV_Klima_Tx_4D: 64 Klima
 SG_ DEV_Klima_Tx_4D_Data : 0|512@1+ (1.0,0.0) [0.0|13407807929942597099574024998205846127479365820592393377723561443721764030073546976801874298166903427690031858186486050853753882811946569946433649006084095] ""  Vector__XXX

BO_ 2617127502 DEV_Klima_Tx_4E: 64 Klima
 SG_ DEV_Klima_Tx_4E_Data : 0|512@1+ (1.0,0.0) [0.0|13407807929942597099574024998205846127479365820592393377723561443721764030073546976801874298166903427690031858186486050853753882811946569946433649006084095] ""  Vector__XXX

BO_ 2617127503 DEV_Klima_Tx_4F: 64 Klima
 SG_ DEV_Klima_Tx_4F_Data : 0|512@1+ (1.0,0.0) [0.0|13407807929942597099574024998205846127479365820592393377723561443721764030073546976801874298166903427690031858186486050853753882811946569946433649006084095] ""  Vector__XXX

BO_ 2617127466 DEV_Klima_Val_Req_02: 8 Vector__XXX
 SG_ DEV_Klima_VAL_Req_02_Data : 0|64@1+ (1.0,0.0) [0.0|18446744073709551615] ""  Klima

BO_ 2617127467 DEV_Klima_Val_Resp_02: 8 Klima
 SG_ DEV_Klima_VAL_Resp_02_Data : 0|64@1+ (1.0,0.0) [0.0|18446744073709551615] ""  Vector__XXX

BO_ 2549880529 DIA_CMC_01_Req: 8 Gateway_Max
 SG_ DIA_CMC_01_Req_Data : 0|64@1+ (1.0,0.0) [0.0|18446744073709551615] ""  Vector__XXX

BO_ 2550011601 DIA_CMC_01_Resp: 8 Vector__XXX
 SG_ DIA_CMC_01_Resp_Data : 0|64@1+ (1.0,0.0) [0.0|18446744073709551615] ""  Gateway_Max

BO_ 2549880533 DIA_CMC_05_Req: 8 Gateway_Max
 SG_ DIA_CMC_05_Req_Data : 0|64@1+ (1.0,0.0) [0.0|18446744073709551615] ""  Vector__XXX

BO_ 2550011605 DIA_CMC_05_Resp: 8 Vector__XXX
 SG_ DIA_CMC_05_Resp_Data : 0|64@1+ (1.0,0.0) [0.0|18446744073709551615] ""  Gateway_Max

BO_ 2549880537 DIA_CMC_09_Req: 8 Gateway_Max
 SG_ DIA_CMC_09_Req_Data : 0|64@1+ (1.0,0.0) [0.0|18446744073709551615] ""  Vector__XXX

BO_ 2550011609 DIA_CMC_09_Resp: 8 Vector__XXX
 SG_ DIA_CMC_09_Resp_Data : 0|64@1+ (1.0,0.0) [0.0|18446744073709551615] ""  Gateway_Max

BO_ 2549880561 DIA_CMC_13_Req: 8 Gateway_Max
 SG_ DIA_CMC_13_Req_Data : 0|64@1+ (1.0,0.0) [0.0|18446744073709551615] ""  Vector__XXX

BO_ 2550011633 DIA_CMC_13_Resp: 8 Vector__XXX
 SG_ DIA_CMC_13_Resp_Data : 0|64@1+ (1.0,0.0) [0.0|18446744073709551615] ""  Gateway_Max

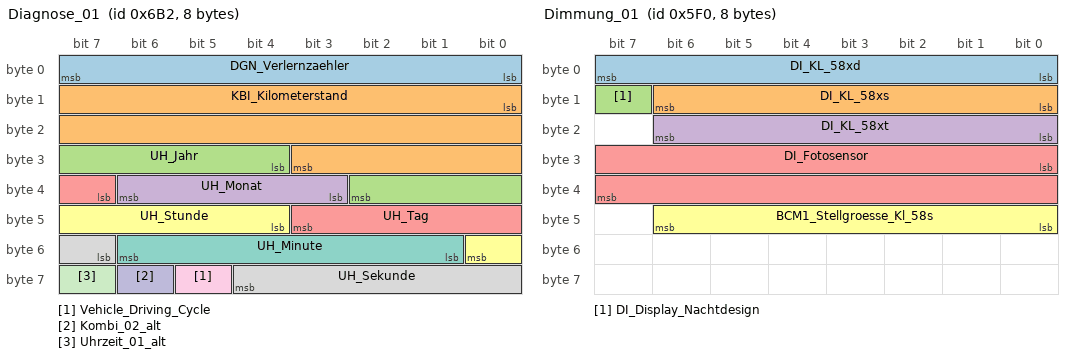
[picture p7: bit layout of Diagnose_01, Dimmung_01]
BO_ 1714 Diagnose_01: 8 Gateway_Max
 SG_ DGN_Verlernzaehler : 0|8@1+ (1,0) [0|254] ""  Klima
 SG_ KBI_Kilometerstand : 8|20@1+ (1,0) [0|1048573] "Unit_KiloMeter"  BMS_NV_12V,Klima
 SG_ UH_Jahr : 28|7@1+ (1,2000) [2000|2127] "Unit_Year"  BMS_NV_12V,Klima
 SG_ UH_Monat : 35|4@1+ (1,0) [1|12] "Unit_Month"  BMS_NV_12V,Klima
 SG_ UH_Tag : 39|5@1+ (1,0) [1|31] "Unit_Day"  BMS_NV_12V,Klima
 SG_ UH_Stunde : 44|5@1+ (1,0) [0|23] "Unit_Hours"  BMS_NV_12V,Klima
 SG_ UH_Minute : 49|6@1+ (1,0) [0|59] "Unit_Minut"  BMS_NV_12V,Klima
 SG_ UH_Sekunde : 55|6@1+ (1,0) [0|59] "Unit_Secon"  BMS_NV_12V,Klima
 SG_ Vehicle_Driving_Cycle : 61|1@1+ (1.0,0.0) [0.0|1] ""  Klima
 SG_ Kombi_02_alt : 62|1@1+ (1.0,0.0) [0.0|1] ""  Klima
 SG_ Uhrzeit_01_alt : 63|1@1+ (1.0,0.0) [0.0|1] ""  Klima

BO_ 851 DiETa_01: 8 Gateway_Max
 SG_ DiETas_01_CRC : 0|8@1+ (1,0) [0|255] ""  Vector__XXX
 SG_ DiETas_01_BZ : 8|4@1+ (1,0) [0|15] ""  Vector__XXX
 SG_ DiETa_Reserve_Byte2_4 : 12|1@1+ (1.0,0.0) [0.0|1] ""  Vector__XXX
 SG_ DiETa_Status : 13|2@1+ (1.0,0.0) [0.0|3] ""  Vector__XXX
 SG_ DiETa_ResponseError : 15|1@1+ (1.0,0.0) [0.0|1] ""  Vector__XXX
 SG_ DiETa_Car : 16|2@1+ (1.0,0.0) [0.0|3] ""  Vector__XXX
 SG_ DiETa_Klima : 18|2@1+ (1.0,0.0) [0.0|3] ""  Klima
 SG_ DiETa_Mode : 20|2@1+ (1.0,0.0) [0.0|3] ""  Vector__XXX
 SG_ DiETa_Parken : 22|2@1+ (1.0,0.0) [0.0|3] ""  Vector__XXX
 SG_ DiETa_FSH_Taste : 24|2@1+ (1.0,0.0) [0.0|3] ""  Klima
 SG_ DiETa_HSH_Taste : 26|2@1+ (1.0,0.0) [0.0|3] ""  Klima
 SG_ DiETa_Warnblink_Taste : 28|2@1+ (1.0,0.0) [0.0|3] ""  Vector__XXX
 SG_ DiETa_FAS_Stufe : 30|2@1+ (1.0,0.0) [0.0|3] ""  Vector__XXX
 SG_ DiETa_PAO_ON_Status : 32|2@1+ (1.0,0.0) [0.0|3] ""  Vector__XXX
 SG_ DiETa_PAO_OFF_Status : 34|2@1+ (1.0,0.0) [0.0|3] ""  Vector__XXX
 SG_ DiETa_Defrost_Taste : 36|2@1+ (1.0,0.0) [0.0|3] ""  Klima
 SG_ DiETa_Mode2 : 38|2@1+ (1.0,0.0) [0.0|3] ""  Vector__XXX
 SG_ DiETa_Lock_Unlock_Taste : 40|3@1+ (1.0,0.0) [0.0|7] ""  Vector__XXX
 SG_ DiETa_Mode_roh : 43|1@1+ (1.0,0.0) [0.0|1] ""  Vector__XXX
 SG_ ESP_Off_Taster : 44|2@1+ (1.0,0.0) [0.0|3] ""  Vector__XXX
 SG_ DiETa_Reserve_Byte6_6 : 46|2@1+ (1.0,0.0) [0.0|3] ""  Vector__XXX
 SG_ DiETa_Touch_Event : 48|4@1+ (1.0,0.0) [0.0|15] ""  Vector__XXX
 SG_ DiETa_Reserve_Byte7_4 : 52|4@1+ (1.0,0.0) [0.0|15] ""  Vector__XXX
 SG_ DiETa_Reserve_Byte8 : 56|8@1+ (1.0,0.0) [0.0|255] ""  Vector__XXX

BO_ 1520 Dimmung_01: 8 Gateway_Max
 SG_ DI_KL_58xd : 0|8@1+ (1,0) [0|253] ""  Klima
 SG_ DI_KL_58xs : 8|7@1+ (1,0) [0|100] "Unit_PerCent"  Klima
 SG_ DI_Display_Nachtdesign : 15|1@1+ (1.0,0.0) [0.0|1] ""  Vector__XXX
 SG_ DI_KL_58xt : 16|7@1+ (1,0) [0|100] "Unit_PerCent"  Klima
 SG_ DI_Fotosensor : 24|16@1+ (1,0) [0|65535] ""  Vector__XXX
 SG_ BCM1_Stellgroesse_Kl_58s : 40|7@1+ (1,0) [0|100] ""  Vector__XXX

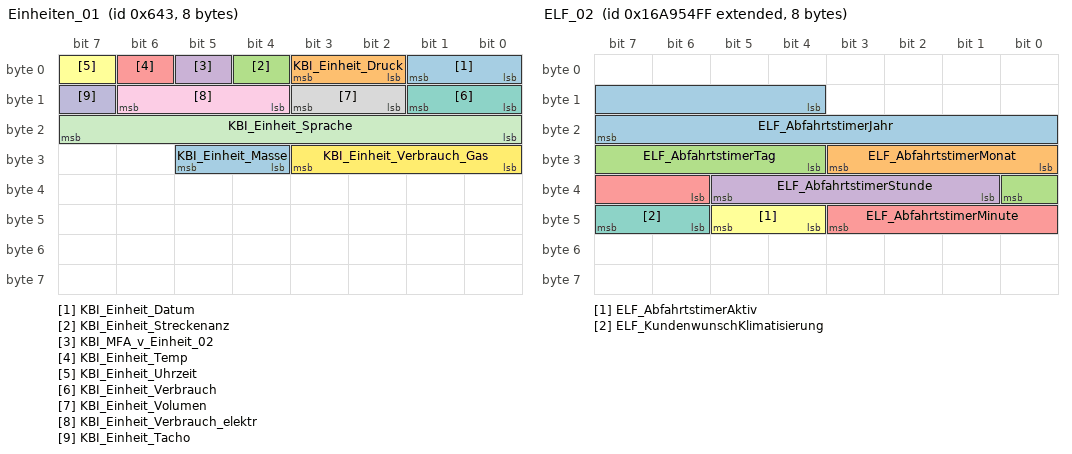
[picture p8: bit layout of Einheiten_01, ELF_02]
BO_ 1603 Einheiten_01: 8 Gateway_Max
 SG_ KBI_Einheit_Datum : 0|2@1+ (1.0,0.0) [0.0|3] ""  Vector__XXX
 SG_ KBI_Einheit_Druck : 2|2@1+ (1.0,0.0) [0.0|3] ""  Vector__XXX
 SG_ KBI_Einheit_Streckenanz : 4|1@1+ (1.0,0.0) [0.0|1] ""  Vector__XXX
 SG_ KBI_MFA_v_Einheit_02 : 5|1@1+ (1.0,0.0) [0.0|1] ""  Vector__XXX
 SG_ KBI_Einheit_Temp : 6|1@1+ (1.0,0.0) [0.0|1] ""  Klima
 SG_ KBI_Einheit_Uhrzeit : 7|1@1+ (1.0,0.0) [0.0|1] ""  Klima
 SG_ KBI_Einheit_Verbrauch : 8|2@1+ (1.0,0.0) [0.0|3] ""  Vector__XXX
 SG_ KBI_Einheit_Volumen : 10|2@1+ (1.0,0.0) [0.0|3] ""  Vector__XXX
 SG_ KBI_Einheit_Verbrauch_elektr : 12|3@1+ (1.0,0.0) [0.0|7] ""  Vector__XXX
 SG_ KBI_Einheit_Tacho : 15|1@1+ (1.0,0.0) [0.0|1] ""  Vector__XXX
 SG_ KBI_Einheit_Sprache : 16|8@1+ (1,0) [0|255] ""  Vector__XXX
 SG_ KBI_Einheit_Verbrauch_Gas : 24|4@1+ (1.0,0.0) [0.0|15] ""  Vector__XXX
 SG_ KBI_Einheit_Masse : 28|2@1+ (1.0,0.0) [0.0|3] ""  Vector__XXX

BO_ 2527679743 ELF_02: 8 Gateway_Max
 SG_ ELF_AbfahrtstimerJahr : 12|12@1+ (1,0) [0|4094] "Unit_Year"  Vector__XXX
 SG_ ELF_AbfahrtstimerMonat : 24|4@1+ (1,0) [1|12] "Unit_Month"  Vector__XXX
 SG_ ELF_AbfahrtstimerTag : 28|5@1+ (1,0) [1|31] "Unit_Day"  Vector__XXX
 SG_ ELF_AbfahrtstimerStunde : 33|5@1+ (1,0) [0|23] "Unit_Hours"  Vector__XXX
 SG_ ELF_AbfahrtstimerMinute : 38|6@1+ (1,0) [0|59] "Unit_Minut"  Vector__XXX
 SG_ ELF_AbfahrtstimerAktiv : 44|2@1+ (1.0,0.0) [0.0|3] ""  Vector__XXX
 SG_ ELF_KundenwunschKlimatisierung : 46|2@1+ (1.0,0.0) [0.0|3] ""  Vector__XXX

BO_ 782 ELF_04: 32 Gateway_Max
 SG_ ELF_Ladestrategie : 12|4@1+ (1.0,0.0) [0.0|15] ""  Vector__XXX
 SG_ ELF_StatusLadestrategie : 16|4@1+ (1.0,0.0) [0.0|15] ""  Vector__XXX
 SG_ ELF_PLTabDatenquelle : 20|3@1+ (1.0,0.0) [0.0|7] ""  Vector__XXX
 SG_ ELF_StatusAbfragePLTab : 23|3@1+ (1.0,0.0) [0.0|7] ""  Vector__XXX
 SG_ ELF_StatusLadeplanerstellung : 26|4@1+ (1.0,0.0) [0.0|15] ""  Vector__XXX
 SG_ ELF_Ladeplandauer : 32|16@1+ (1,0) [0|50000] "Unit_Minut"  Vector__XXX
 SG_ ELF_EnergiebedarfZielSoc : 48|12@1+ (0.1,0) [0.0|400.0] "Unit_KiloWattHour"  Vector__XXX
 SG_ ELF_EnergiebedarfMaxSoc : 60|12@1+ (0.1,0) [0.0|400.0] "Unit_KiloWattHour"  Vector__XXX
 SG_ ELF_EnergiebedarfMinSoc : 72|12@1+ (0.1,0) [0.0|400.0] "Unit_KiloWattHour"  Vector__XXX
 SG_ ELF_PLTabellenGefordert : 84|1@1+ (1.0,0.0) [0.0|1] ""  Vector__XXX
 SG_ ELF_EvNeuverhandlung : 85|1@1+ (1.0,0.0) [0.0|1] ""  Vector__XXX
 SG_ ELF_EigenstromGefordert : 86|1@1+ (1.0,0.0) [0.0|1] ""  Vector__XXX
 SG_ ELF_ErwLadenAnforderung : 87|1@1+ (1.0,0.0) [0.0|1] ""  Vector__XXX
 SG_ ELF_LadeleistungMaxKons : 88|13@1+ (100,-50000) [-50000|400000] "Unit_Watt"  Vector__XXX
 SG_ ELF_AnforderungWlanVerbindung : 101|7@1+ (1.0,0.0) [0.0|127] ""  Vector__XXX

BO_ 192 EM1_01: 32 Gateway_Max
 SG_ EM1_01_CRC : 0|8@1+ (1,0) [0|255] ""  Vector__XXX
 SG_ EM1_01_BZ : 8|4@1+ (1,0) [0|15] ""  Vector__XXX
 SG_ EM1_Istmodus : 12|4@1+ (1.0,0.0) [0.0|15] ""  Vector__XXX
 SG_ EM1_IstMoment : 16|12@1+ (0.5,-1023) [-1023.0|1023.5] "Unit_NewtoMeter"  Vector__XXX
 SG_ EM1_Moment_AR_Eingriff : 28|12@1+ (0.5,-1023) [-1023.0|1023.5] "Unit_NewtoMeter"  Vector__XXX
 SG_ EM1_IstDrehzahl : 40|15@1+ (1,-10000) [-10000|22765] "Unit_MinutInver"  Vector__XXX
 SG_ EM1_AR_aktiv : 55|1@1+ (1.0,0.0) [0.0|1] ""  Vector__XXX
 SG_ EM1_IstSpannung : 56|12@1+ (0.25,0) [0.00|1023.25] "Unit_Volt"  Vector__XXX
 SG_ EM1_Strom_HV : 68|12@1+ (0.5,-1023) [-1023.0|1023.5] "Unit_Amper"  Vector__XXX
 SG_ EM1_Max_Moment : 80|11@1+ (1,-1023) [-1023|1022] "Unit_NewtoMeter"  Vector__XXX
 SG_ EM1_ErwGrenzen_aktiv : 91|1@1+ (1.0,0.0) [0.0|1] ""  Vector__XXX
 SG_ EM1_Min_Moment : 92|11@1+ (1,-1023) [-1023|1022] "Unit_NewtoMeter"  Vector__XXX
 SG_ EM1_Fehler_ElAntriebAbschaltung : 103|1@1+ (1.0,0.0) [0.0|1] ""  Vector__XXX
 SG_ EM1_Max_Moment_Lim : 104|11@1+ (1,-1023) [-1023|1022] "Unit_NewtoMeter"  Vector__XXX
 SG_ EM1_Fehler_Notabschaltung : 115|1@1+ (1.0,0.0) [0.0|1] ""  Vector__XXX
 SG_ EM1_Min_Moment_Lim : 116|11@1+ (1,-1023) [-1023|1022] "Unit_NewtoMeter"  Vector__XXX
 SG_ EM1_Status_DrzEingriff : 127|2@1+ (1.0,0.0) [0.0|3] ""  Vector__XXX
 SG_ EM1_Mom_DrzEingriff : 129|11@1+ (1,-1023) [-1023|1022] "Unit_NewtoMeter"  Vector__XXX
 SG_ EM1_Raddrehzahl_links : 140|13@1+ (0.3,0) [0.0|2456.1] "Unit_MinutInver"  Vector__XXX
 SG_ EM1_Raddrehzahl_rechts : 153|13@1+ (0.3,0) [0.0|2456.1] "Unit_MinutInver"  Vector__XXX
 SG_ EM1_Max_Moment_Gesamt : 166|11@1+ (1,-1023) [-1023|1022] "Unit_NewtoMeter"  Vector__XXX
 SG_ EM1_Min_Moment_Gesamt : 177|11@1+ (1,-1023) [-1023|1022] "Unit_NewtoMeter"  Vector__XXX

CM_ BO_ 902 "ab MQB 7.2.1";
CM_ BO_ 1520 "ab MQB nach abgestimmten FLH Dimmung";
CM_ BO_ 1603 "ab MQB mit 8 Byte";

CM_ SG_ 397 BMS_MV_01_BZ "4bit Botschaftszähler, wird mit jeder Sendebotschaft inkrementiert";
CM_ SG_ 397 BMS_MV_01_CRC "Für MLB:
Berechnung siehe Lastenheft 'Kommunikationsabsicherung für FlexRay und CAN'
Ab MQB und MLBevo:
Berechnung siehe Lastenheft 'End-to-End Kommunikationsabsicherung'

Endwerte siehe Begleitdokument 'S-PDU Kennungsfolgen'";
CM_ SG_ 397 BMS_MV_IstSpannung "actual voltage of the battery / Momentanwert: Batteriespannung";
CM_ SG_ 397 BMS_MV_IstSpannung_Zwkr "Die aktuelle Zwischenkreisspannung gemessen von der MV-Batterie";
CM_ SG_ 397 BMS_MV_IstStrom "Momentanwert: Batteriestrom
Stromrichtung: ein Ladestrom wird mit positiven, ein Entladestrom mit negativen Werten angegeben";
CM_ SG_ 397 BMS_MV_SOC_HiRes "State of Charge / aktueller Ladezustand der Batterie (höhere Auflösung)";

CM_ SG_ 419 BMS_MV_MaxDyn_EntladeStrom "max current (discharge)
maximal zulässiger Entladestrom (zwingend einzuhaltender Grenzwert); Wert ist für eine Dauer von z.B. 1s garantiert";
CM_ SG_ 419 BMS_MV_MaxDyn_LadeStrom "max current (charge)
maximal zulässiger Ladestrom (zwingend einzuhaltender Grenzwert); Wert ist für eine Dauer von z.B.  1s garantiert";
CM_ SG_ 419 BMS_MV_Min_EntladeSpannung "min. voltage / minimal erlaubte Batteriespannung (zwingend einzuhaltender Grenzwert)";
CM_ SG_ 419 BMS_MV_MinDyn_LadeSpannung "min. voltage during charge with current MaxDyn_LadeStrom resp. iChMax / rechnerischer Wert: minimales, für eine Dauer von z.B. 1s garantiertes Spannungsniveau, das unter Belastung mit MaxDyn_LadeStrom bzw. iChMax nicht unterschritten werden würde";
CM_ SG_ 419 BMS_MV_MinDynEntladeSpannung "min. voltage during discharge with current MaxDyn_EntladeStrom resp. iDisChMax / rechnerischer Wert: minimales, für eine Dauer von ~1s garantiertes Spannungsniveau, das unter Belastung mit MaxDyn_EntladeStrom bzw. iDisChMax nicht unterschritten werden wür";

CM_ SG_ 2589283412 BMS_MV_IstRuecklaufTemperatur "Aktuelle Ruecklauftemperatur der Batterie

Abweichender individueller Init-Wert = 254 (Standardkodierung = 254)";
CM_ SG_ 2589283412 BMS_MV_IstVorlaufTemperatur "Aktuelle Vorlauftemperatur der Batterie

Abweichender individueller Init-Wert = 254 (Standardkodierung = 254)";
CM_ SG_ 2589283412 BMS_MV_Soll_PWM_Pumpe "Fehlende Beschreibung (Import)";
CM_ SG_ 2589283412 BMS_MV_SollVolumenstrom "Mindestanforderung des Soll Volumenstrom für Kühlkreislauf Batterie";
CM_ SG_ 2589283412 BMS_MV_SollVorlauftemperatur "Soll_Vorlauftemperatur_Kühlmedium in °C

Abweichender individueller Init-Wert = 254 (Standardkodierung = 254)";
CM_ SG_ 2589283412 BMS_MV_Speichertechnologie "Speichertechnologie des MV-Speichers. Zuordnung zur Technologie in MV FLAH.";
CM_ SG_ 2589283412 BMS_MV_Temp_Epsilon "Das Signal beschreibt die Differenz zwischen Batterie Soll-Temperatur und Batterie Ist-Temperatur.";
CM_ SG_ 2589283412 BMS_MV_Temperatur "battery temperature / Momentanwert: Temperatur der Traktionsbatterie

Abweichender individueller Init-Wert = 254 (Standardkodierung = 254)";
CM_ SG_ 2589283412 BMS_MV_Temperierung_Anf "Temperierungsbedarf der HV-Batterie";

CM_ SG_ 2589283608 BMS_MV_Energieinhalt "aktuell nutzbarer Energieinhalt der MV-Batterie
(bezogen auf ein definiertes mittleres Belastungsprofil)";
CM_ SG_ 2589283608 BMS_MV_MaxEnergieinhalt "maximaler nutzbarer Energieinhalt der MV-Batterie (bezogen auf Last KBI_RWDS_Lastprofil bei SOC=100%)
Abhängig von KBI_RWDS_Lastprofil";

CM_ SG_ 2589283606 BMS_MV_max_Grenz_SOC "oberer Grenz SOC - Betriebsstrategie";
CM_ SG_ 2589283606 BMS_MV_SOC_Kaltstart "Abhängig von der notwendigen Kaltstartleistung berechneter SOC Wert.";

CM_ SG_ 1021 BMS_MV_Pred_Entladeperformance "Indikator Stromintegral in Entladerichtung. 
0%     = Start abrampen Peak-Entladestromgrenze auf Dauer-Entladestromgrenze.
100% = Voller Peak-Entladestrom verfügbar";
CM_ SG_ 1021 BMS_MV_Pred_Ladeperformance "Indikator Stromintegral in Laderichtung. 
0%     = Start abrampen Peak-Ladestromgrenze auf Dauer-Ladestromgrenze.
100% = Voller Peak-Ladestrom verfügbar";
CM_ SG_ 1021 BMS_MV_SOHC_DiagSOC "Zielwert zum Start und Durchführung der SOHC-Diagnose (0%-100%)";
CM_ SG_ 1021 BMS_MV_SOHC_DiagStatus "Aktueller Diagnose Status der SOHC-Diagnose:

[0] kein Diagnosebedarf
[1] Diagnosebedarf niedrig
[2] Diagnosebedarf mittel
[3] Diagnosebedarf Zwang
[4] Diagnosebedarf Werkstatt
[5] Diagnose läuft
[6] Diagnoseabbruch
[7] Diagnosefehler";

CM_ SG_ 2463978716 BMS_MV_12_BZ "4bit Botschaftszähler, wird mit jeder Sendebotschaft inkrementiert";
CM_ SG_ 2463978716 BMS_MV_12_CRC "Für MLB:
Berechnung siehe Lastenheft 'Kommunikationsabsicherung für FlexRay und CAN'
Ab MQB und MLBevo:
Berechnung siehe Lastenheft 'End-to-End Kommunikationsabsicherung'

Endwerte siehe Begleitdokument 'S-PDU Kennungsfolgen'";
CM_ SG_ 2463978716 BMS_MV_Fehler_BattAbschaltung "Fehler: Fehlerzustand, erfordert das Öffnen der Batterieschütze
interner Batteriefehler, Batterieschütze ohne Vorankündigung durch das BMS geöffnet";
CM_ SG_ 2463978716 BMS_MV_Fehler_BattAbschaltungAnf "Fehler: Fehlerzustand, erfordert das Öffnen der Batterieschütze
interner Batteriefehler; Vorankündigung eines bevorstehenden Öffnens der Batterieschütze durch das BMS";
CM_ SG_ 2463978716 BMS_MV_Fehler_Kaltstartleistung "Signalisiert, dass die Leistungsreserve der MV-Batterie für die erwartete Kaltstartleistung nicht ausreichend ist.";
CM_ SG_ 2463978716 BMS_MV_Fehler_Leistungsred "Fehler: Leistungsfähigkeit der Batterie ist eingeschränkt (z.B. aufgrund des Ausfalls von Sensoren oder des Lüfters)";
CM_ SG_ 2463978716 BMS_MV_Fehler_Notfallreserve "signalisiert, dass die geforderte Energiereserve nach ASIL zur Versorgung der NV-Verbraucher nicht voll verfügbar ist";
CM_ SG_ 2463978716 BMS_MV_Fehler_Relay_offen "Fehler: Relais schließt nicht / MV-Batterie nicht verfügbar
kann MV-Netz nicht aktivieren (z.B. defektes Relais, Sicherung, Vorlade-Fehler)";
CM_ SG_ 2463978716 BMS_MV_Fehler_Relay_verschweisst "Fehler: Relais verschweißt";
CM_ SG_ 2463978716 BMS_MV_IstModus "actual state of the battery / momentaner Status der Batterie
0: Standby; Kommunikation aktiv
1: Hauptschütze geschlossen / MV-Netz aktiviert / normaler Fahrbetrieb
5: interner Batteriefehler / angeforderter Modus kann nicht eingestellt werden
7: Initi";
CM_ SG_ 2463978716 BMS_MV_Leistungsreduzierung "Signalisierung der Performanceeinschränkung der 48V Batterie aufgrund hoher Temperatur";
CM_ SG_ 2463978716 BMS_MV_Peak_EntladeLeistung "aktuell zulässige PeakEntladeleistung (Wert ist für eine kurze Dauer); auf die Grenze wird ein Derating angewendet";
CM_ SG_ 2463978716 BMS_MV_Peak_EntladeSpannung "Erwartete Spannung, die sich bei Belastung der MV Batterie mit der Peak-Entladeleistung einstellt.";
CM_ SG_ 2463978716 BMS_MV_Peak_LadeLeistung "aktuell zulässige PeakLadeleistung (Wert ist für eine kurze Dauer); auf die Grenze wird ein Derating angewendet.";
CM_ SG_ 2463978716 BMS_MV_Peak_LadeSpannung "Erwartete Spannung, die sich bei Belastung der MV Batterie mit der Peak-Ladeleistung einstellt.";

CM_ SG_ 2463978717 BMS_MV_Max_EntladeLeistung "aktuell zulässige strategische Entladeleistung (Wert ist für eine mittlere Dauer); auf die Grenze wird ein Derating angewendet";
CM_ SG_ 2463978717 BMS_MV_Max_LadeLeistung "aktuell zulässige strategische Ladeleistung (Wert ist für eine mittlere Dauer); auf die Grenze wird ein Derating angewendet.";
CM_ SG_ 2463978717 BMS_MV_PerfInd_Entladen "Leistungsindikation in Entladerichtung.
Der Bereich 100...200% beschreibt die verbleibende Reserve, bis ein Derating der maximalen Entladeleistungsgrenze eintritt.
Werte von 0 bis 100% beschreiben, auf welchen Teil der potentiell möglichen maximalen Ent";
CM_ SG_ 2463978717 BMS_MV_PerfInd_Laden "Leistungsindikation in Laderichtung.
Der Bereich 100...200% beschreibt die verbleibende Reserve, bis ein Derating der maximalen Ladeleistungsgrenze eintritt.
Werte von 0 bis 100% beschreiben, auf welchen Teil der potentiell möglichen maximalen Ladeleist";
CM_ SG_ 2463978717 BMS_MV_Strat_EntladeSpannung "Erwartete Spannung, die sich bei Belastung der MV Batterie mit der Max-Entladeleistung einstellt.";

CM_ SG_ 2463978718 BMS_MV_14_BZ "4bit Botschaftszähler, wird mit jeder Sendebotschaft inkrementiert";
CM_ SG_ 2463978718 BMS_MV_14_CRC "Für MLB:
Berechnung siehe Lastenheft 'Kommunikationsabsicherung für FlexRay und CAN'
Ab MQB und MLBevo:
Berechnung siehe Lastenheft 'End-to-End Kommunikationsabsicherung'

Endwerte siehe Begleitdokument 'S-PDU Kennungsfolgen'";
CM_ SG_ 2463978718 BMS_MV_Max_EntladeStrom_Lim "Maximal erlaubter Entladestrom (zwingend einzuhaltender Grenzwert) für transiente Vorgänge (Subsekundenbereich). Es erfolgt kein Derating";
CM_ SG_ 2463978718 BMS_MV_Max_LadeSpannung_Lim "maximal erlaubte Betriebsspannung (Abregelgrenze). Zwingend einzuhaltender Grenzwert.";
CM_ SG_ 2463978718 BMS_MV_Max_LadeStrom_Lim "Maximal erlaubter Ladestrom (zwingend einzuhaltender Grenzwert) für transiente Vorgänge (Subsekundenbereich). Es erfolgt kein Derating.";
CM_ SG_ 2463978718 BMS_MV_Min_EntladeSpannung_Lim "Minimal erlaubte Batteriespannung (Abregelgrenze): Zwingend einzuhaltender Grenzwert.";
CM_ SG_ 2463978718 BMS_MV_Strat_LadeSpannung "Erwartete Spannung, die sich bei Belastung der MV Batterie mit der Max-Ladeleistung einstellt.";

CM_ SG_ 2589283523 BMS_48V_Indc_StChk "Übermittlung vom Diagnoseergebnis für das Inducement";
CM_ SG_ 2589283523 BMS_48V_Indc_StFail "Inducement Anforderung";
CM_ SG_ 2589283523 BMS_MV_Dauer_EntladeLeistung "ist die aktuelle Dauer-Leistungsfähigkeit der Batterie. 
Wenn dieser Wert überschritten wird, kann ein zeitliches Derating der maximalen Leistungsgrenzen stattfindet. Die Dauerleistung ändert sich mit Batterietemperatur und Ladezustand.";
CM_ SG_ 2589283523 BMS_MV_Dauer_EntladeSpannung "Erwartete Spannung, die sich bei Belastung der MV Batterie mit der Dauer-Entladeleistung einstellt.";
CM_ SG_ 2589283523 BMS_MV_Dauer_LadeLeistung "ist die aktuelle Dauer-Leistungsfähigkeit der Batterie. 
Wenn dieser Wert überschritten wird, kann ein zeitliches Derating der maximalen Leistungsgrenzen stattfindet. Die Dauerleistung ändert sich mit Batterietemperatur und Ladezustand.";
CM_ SG_ 2589283523 BMS_MV_Dauer_LadeSpannung "Erwartete Spannung, die sich bei Belastung der MV Batterie mit der Dauer-Ladeleistung einstellt.";
CM_ SG_ 2589283523 BMS_MV_Dauer_RMS_Strom "Dauerhaft maximal verfügbarer RMS-Strom ohne thermisches Derating.";
CM_ SG_ 2589283523 BMS_MV_Kundenwarnung "Kundenwarnung aufgrund eines Batteriefehlers.";
CM_ SG_ 2589283523 BMS_MV_OBD_Lampe_Anf "Anforderung MIL (MalfunctionIndicationLamp) von BMS (Motorsteuergerät reicht diese Info an Kombi weiter).";
CM_ SG_ 2589283523 OBDProtocol_BMS_48V "Bestätigung des aktuell umgesetzten Scan Tool Protokolls";

CM_ SG_ 2589283543 SOK_BMS_MV_15_Signatur "Signatur im Rahmen der durch SOK geschützen Broadcast-Kommunikation

Geschützte Funktion: OBD-Malfunction Indicator Light (MIL)
Geschützte PDU: BMS_MV_15";

CM_ SG_ 2589283524 BMS_MV_EntladeEnergie "Maximal verfügbare Energie in Entladerichtung basierend auf dem gemittelten Entladestrom";
CM_ SG_ 2589283524 BMS_MV_LadeEnergie "Maximal verfügbare Energie in Laderichtung basierend auf dem gemittelten Ladestrom";
CM_ SG_ 2589283524 BMS_MV_Max_RMS_Strom "Maximal verfügbarer RMS-Strom ohne thermisches Derating innerhalb eines definierten Zeitraums (z.B. 10min).";
CM_ SG_ 2589283524 BMS_MV_TRD_Sensfail "Batteriesensordiagnose zur Prüfung ob der Kommunikationsausfall der Batterie durch 'thermal runaway' ausgelöst wurde";
CM_ SG_ 2589283524 BMS_MV_TRD_Temp "Temperaturdiagnose zur Prüfung, ob der Kommunikationsausfall der Batterie durch 'thermal runaway' ausgelöst wurde";
CM_ SG_ 2589283524 BMS_MV_TRD_Voltage "Spannungsdiagnose zur Prüfung ob der Kommunikationsausfall der Batterie durch 'thermal runaway' ausgelöst wurde";

CM_ SG_ 2527679928 BMS_NV_Indc_StChk "Inducement";
CM_ SG_ 2527679928 BMS_NV_Indc_StFail "0: passiv/Init
1: aktiv";
CM_ SG_ 2527679928 BMS_NV_OBD_Lampe_Anf "MIL Lampe Anforderung wegen OBD relevanter Fehler im 12V NV Speicher";
CM_ SG_ 2527679928 OBDProtocol_BMS_NV "Bestätigung des aktuell umgesetzten Scan Tool Protokolls";
CM_ SG_ 2527679928 SOK_BMS_NV_11_Signatur "Signatur im Rahmen der durch SOK geschützen Broadcast-Kommunikation

Geschützte Funktion: OBD-Malfunction Indicator Light (MIL)
Geschützte PDU: BMS_NV_11";

CM_ SG_ 902 CHA_Charge_LED "Ansteuerung der LED am Charge-Taster durch Charisma im PHEV";
CM_ SG_ 902 CHA_Charisma_Taste2_LED "Ansteuerung der 2. Charisma-Taste-LED";
CM_ SG_ 902 CHA_Current_Mode "Aktuell eingestelltes Charisma Fahrprogramm";
CM_ SG_ 902 CHA_Current_Mode_FPA "Aktuell eingestelltes Charisma Fahrprogramm";
CM_ SG_ 902 CHA_Eco_Charisma_LED "Ansteuerung der Funktions-LED der ECO alias Bluekey Taste bzw. Charisma-Taste.
Der Master der Fahrmodus-Funktion soll die Funktionsleuchte ansteuern, in der MQB Architektur ist der Master im Gateway untergebracht.";
CM_ SG_ 902 CHA_EV_LED "Ansteuerung der LED am EV-Taster durch Charisma im PHEV";
CM_ SG_ 902 CHA_Fahrer_Umschaltung "Die manuelle Umschaltung durch den Fahrer soll signalisiert werden, um zu automatischen Umschaltungen (z.B. Retries) differenzieren zu können.";
CM_ SG_ 902 CHA_Kombi_Texte "Anzeige des aktuellen Charisma-Fahrprofiles im Kombi.
Die Texte werden HUT-Spezifisch in einem Schnittstellen-LAH definiert.";
CM_ SG_ 902 CHA_Kombi_Texte_02 "Anzeige von Hinweistexten bzgl. Charismaumschaltungen im Kombi.
Die Texte werden HUT-Spezifisch in einem Schnittstellen-LAH definiert.";
CM_ SG_ 902 CHA_Offroad_LED "Ansteuerung der Offroad-LED";
CM_ SG_ 902 CHA_ReqPrgDispSetup "Requested Charisma-programm to Kombi to change display setup.";
CM_ SG_ 902 CHA_StCurProfDft "Signal indicates if the current Charisma-profile";
CM_ SG_ 902 CHA_Ziel_FahrPr_03_01 "reserviert für Anforderung Ziel-Fahrprogramm";
CM_ SG_ 902 CHA_Ziel_FahrPr_03_02 "reserviert für Anforderung Ziel-Fahrprogramm";
CM_ SG_ 902 CHA_Ziel_FahrPr_AMB "Anforderung Ziel-Fahrprogramm Ambientelichtmodul";
CM_ SG_ 902 CHA_Ziel_FahrPr_HSP "Anforderung Ziel-Fahrprogramm Heckspoiler";
CM_ SG_ 902 CHA_Ziel_FahrPr_IVB "Anforderung Ziel-Fahrprogramm IVB";
CM_ SG_ 902 CHA_Ziel_FahrPr_KL "Anforderung Ziel-Fahrprogramm Klima";
CM_ SG_ 902 CHA_Ziel_FahrPr_RWB "Anforderung Zielfahrprogramm Reichweitenberechnung (RWB)";

CM_ SG_ 686 DC_IstSpannung_HV "Momentanwert:  Hochspannung am DC/DC Wandler";
CM_ SG_ 686 DC_IstSpannung_NV "Momentanwert: Bordnetzspannung am DC/DC Wandler";
CM_ SG_ 686 DC_IstStrom_NV "Momentanwert: Strom vom DC/DC in das Bordnetz
Tiefsetzen - positiv
Hochsetzen - negativ";
CM_ SG_ 686 DCDC_01_CRC "Für MLB:
'Berechnung siehe Lastenheft 'Kommunikationsabsicherung für FlexRay und CAN''

Ab MQB und MLBevo:
'Berechnung siehe Lastenheft 'End-to-End Kommunikationsabsicherung''

Endwerte siehe Begleitdokument 'S-PDU Kennungsfolgen'";

CM_ SG_ 1012 DC_HYB_Auslastungsgrad "Momentanwert: Auslastung DC/DC (DFM Signal), entspricht I_akt / I_max
(Vorhalt für MQB)";
CM_ SG_ 1012 DC_ReserveStrom_NV "Momentanwert: Stromreserve vom DC/DC-Wandler in Richtung 12V-Bordnetz

Tiefsetzen - positiv
Hochsetzen - negativ";
CM_ SG_ 1012 DC_Verbrauch "Energieverbrauch vom DCDC für Versorgung 12V-Bordnetz inkl. seines eigenen Wirkungsgrads (bspw.: HV_Strom*HV_Spannung*t)";
CM_ SG_ 1012 DC_Verbrauch_Ueberlauf "Überlauf-Bit für das Signal DC_Verbrauch";
CM_ SG_ 1012 DC_Verlustleistung "Aktuelle Verlustleistung des DC/DC-Wandlers.";
CM_ SG_ 1012 DCDC_02_CRC "Für MLB:
'Berechnung siehe Lastenheft 'Kommunikationsabsicherung für FlexRay und CAN''

Ab MQB und MLBevo:
'Berechnung siehe Lastenheft 'End-to-End Kommunikationsabsicherung''

Endwerte siehe Begleitdokument 'S-PDU Kennungsfolgen'";

CM_ SG_ 1485 DC_Abregelung_Temperatur "Abregelung aufgrund Übertemperatur im Leistungsteil (Hochtemperatur-Abregelung)";
CM_ SG_ 1485 DC_Derating "Signalisierung, ob der DC/DC-Wandler sich in der Abregelung befindet:
0=keine_Abregelung
1= Abregelung_Ursache_NV
2= Abregelung_Ursache_HV
3= Abregelung_Ursache_Temp
4= Abregelung_Ursache_Intern";
CM_ SG_ 1485 DC_Fehlerstatus "aktueller Fehlerstatus des DCDC-Wandler:";
CM_ SG_ 1485 DC_Kl30c_Status "Signalisierung des
Stecker-Zustandes der Klemme 30c (Service-Disconnect)

0=Init
1=geschlossen
2=offen
3=Fehler";
CM_ SG_ 1485 DC_OBD_Lampe_Anf "Anforderung MIL (MalfunctionIndicationLamp) vom DCDC-Wandler (Motorsteuergerät reicht diese Info an Kombi weiter).";
CM_ SG_ 1485 DC_Peakstrom_verfuegbar "Peakstrom verfügbar/nicht verfügbar";
CM_ SG_ 1485 DC_SollVolumenstrom "Für die Kühlung des DC/DC Wandler aktuell mindestens benötigter Kühlwasservolumenstrom";
CM_ SG_ 1485 DC_Status_Spgfreiheit_HV "HV DC/DC-Wandler Status HV-Spannungsfreiheit";
CM_ SG_ 1485 DC_Temperatur "Momentanwert: Temperatur des DC/DC Wandlers";
CM_ SG_ 1485 DC_Temperatur_Alarm "Temperatur-Alarm DCDC-Wandler RTM";
CM_ SG_ 1485 DC_Warnlampe_Anf "Anforderung der HV-Warnlampe im Kombiinstrument.";
CM_ SG_ 1485 DCDC_03_CRC "Für MLB:
'Berechnung siehe Lastenheft 'Kommunikationsabsicherung für FlexRay und CAN''

Ab MQB und MLBevo:
'Berechnung siehe Lastenheft 'End-to-End Kommunikationsabsicherung''

Endwerte siehe Begleitdokument 'S-PDU Kennungsfolgen'";
CM_ SG_ 1485 DCDC_NV_Indc_StChk "OBM Inducement Request TestNotCompletedThisOperationCycle";
CM_ SG_ 1485 DCDC_NV_Indc_StFail "OBM-Inducement Request TestFailed";
CM_ SG_ 1485 OBDProtocol_DCDC_NV "Bestätigung des aktuell umgesetzten Scan Tool Protokolls";

CM_ SG_ 1486 SOK_DCDC_03_Signatur "Signatur im Rahmen der durch SOK geschützen Broadcast-Kommunikation

Geschützte Funktion: OBD-Malfunction Indicator Light (MIL)
Geschützte PDU: DCDC_03";

CM_ SG_ 247 DC_Fehler_extern "Fehler/Abschaltung: DC/DC-Wandler ist aufgrund einer Umgebungsbedingung (z.B. HV-Spannung, NV-Spannung Kühlmitteltemperatur oder Systemfehler (ZK-Vorladung) ) nicht in der Lage geforderten Regelbetrieb einzuhalten.";
CM_ SG_ 247 DC_Fehler_intern "Fehler: DC/DC-Wandler ist aufgrund eines internen Hardware-Fehlers abgeschaltet";
CM_ SG_ 247 DC_IstLeistung_HV "Aktuelle Ist-Leistung des Bordnetzwandlers auf der HV-Seite. 

Tiefsetzen - positiv
Hochsetzen- negativ";
CM_ SG_ 247 DC_IstModus_02 "aktuelle Betriebsart des DC/DC Wandlers;
0: Standby; Kommunikation aktiv
1: HV_On_Vorladen
2: Tiefsetzen
3: Hochsetzen
4: Pruefimpuls_12V
5: interner Fehler DC/DC-Wandler / angeforderter Sollmodus kann nicht eingestellt werden
6: reserve
7: Initia";
CM_ SG_ 247 DC_IstStrom_HV "Momentanwert:  Strom aus dem Traktionsnetz in den DC/DC Wandler";
CM_ SG_ 247 DC_Status_EoHVL "Status der EoHVL am DCDC :
0=Init
1=Keine offene HV-Leitung erkannt
2=offene HV-Leitung erkannt
3=Fehler";
CM_ SG_ 247 DC_Status_Spgfreiheit "Status der Spannungsfreiheit für den Standalone DCDC-Wandler (HV-NV)
0=Init (ohne Funktion)
1=BMS Zwischenkreis spannungsfrei (U_Zwkr < 20V)
2=BMS Zwischenkreis nicht spannungsfrei (U_Zwkr >/= 25V, Hysterese)
3=Fehler (z.B. Fehler in der Sensorik)";
CM_ SG_ 247 DC_Vorladung_Status "Status der ZK-Vorladung:

=0, nicht_abgeschlossen
=1, abgeschlossen

DCDC-Wandler gibt Empfehlung für schließen der Schützen. 
HVK/BMS prüft die ZK-Spannung und entscheidet ob die Schütze geschlossen werden können.";
CM_ SG_ 247 DCDC_04_BZ "4bit Botschaftszähler, wird mit jeder Sendebotschaft inkrementiert";
CM_ SG_ 247 DCDC_04_CRC "Für MLB:
Berechnung siehe Lastenheft 'Kommunikationsabsicherung für FlexRay und CAN'
Ab MQB und MLBevo:
Berechnung siehe Lastenheft 'End-to-End Kommunikationsabsicherung'

Endwerte siehe Begleitdokument 'S-PDU Kennungsfolgen'";

CM_ SG_ 1484 DC_MV_12V_Bordnetzstuetzung "DC/DC-Wandler befindet sich im Betriebsmodus Bordnetzstützung";
CM_ SG_ 1484 DC_MV_Abregelung_Temperatur "Abregelung aufgrund Übertemperatur im Leistungsteil (Hochtemperatur-Abregelung)";
CM_ SG_ 1484 DC_MV_Derating "Signalisierung, ob der DC/DC-Wandler sich in der Abregelung befindet:
0=keine_Abregelung
1= Abregelung_Ursache_NV
2= Abregelung_Ursache_MV
3= Abregelung_Ursache_Temp
4= Abregelung_Ursache_Intern";
CM_ SG_ 1484 DC_MV_Fehlerstatus "aktueller Fehlerstatus des DCDC-Wandler:";
CM_ SG_ 1484 DC_MV_IstModus_02 "aktuelle Betriebsart des DC/DC Wandlers";
CM_ SG_ 1484 DC_MV_Temperatur "Momentanwert: Temperatur des DC/DC Wandlers";
CM_ SG_ 1484 DC_MV_Tiefsetzen_Notbetrieb "DCDC-Wandler arbeitet im Notbetrieb; ungeregelter Betrieb mit festem Tastverhältnis";
CM_ SG_ 1484 DCDC_MV_03_BZ "4bit Botschaftszähler, wird mit jeder Sendebotschaft inkrementiert";
CM_ SG_ 1484 DCDC_MV_03_CRC "Für MLB:
Berechnung siehe Lastenheft 'Kommunikationsabsicherung für FlexRay und CAN'
Ab MQB und MLBevo:
Berechnung siehe Lastenheft 'End-to-End Kommunikationsabsicherung'

Endwerte siehe Begleitdokument 'S-PDU Kennungsfolgen'";
CM_ SG_ 1484 DCDC_MV_Peakstrom_verfuegbar "Peakstrom verfügbar/nicht verfügbar";

CM_ SG_ 2549880529 DIA_CMC_01_Req_Data "Diagnosezugriff & Flashen Cell Module Controller";

CM_ SG_ 2550011601 DIA_CMC_01_Resp_Data "Diagnosezugriff & Flashen Cell Module Controller";

CM_ SG_ 2549880533 DIA_CMC_05_Req_Data "Diagnosezugriff & Flashen Cell Module Controller";

CM_ SG_ 2550011605 DIA_CMC_05_Resp_Data "Diagnosezugriff & Flashen Cell Module Controller";

CM_ SG_ 2549880537 DIA_CMC_09_Req_Data "Diagnosezugriff & Flashen Cell Module Controller";

CM_ SG_ 2550011609 DIA_CMC_09_Resp_Data "Diagnosezugriff & Flashen Cell Module Controller";

CM_ SG_ 2549880561 DIA_CMC_13_Req_Data "Diagnosezugriff & Flashen Cell Module Controller";

CM_ SG_ 2550011633 DIA_CMC_13_Resp_Data "Diagnosezugriff & Flashen Cell Module Controller";

CM_ SG_ 1714 DGN_Verlernzaehler "wrap around 254 --> 0";
CM_ SG_ 1714 KBI_Kilometerstand "Fehler wird ausgegeben, falls Kilometerstand nicht restaurierbar
";
CM_ SG_ 1714 UH_Minute "0x3C- 0x3f = Werte ungültig";
CM_ SG_ 1714 UH_Monat "0x0D, 0xF =  Werte ungültig
0x0E = Relatives Datum (nur VW)";
CM_ SG_ 1714 UH_Sekunde "0x3C- 0x3f = Werte ungültig";
CM_ SG_ 1714 UH_Stunde "0x18 - 0x1F = Werte ungültig";
CM_ SG_ 1714 UH_Tag "0x0: reserviert bei VW";
CM_ SG_ 1714 Uhrzeit_01_alt "
";
CM_ SG_ 1714 Vehicle_Driving_Cycle "Optimierung der Inbetriebnahme von Steuergeräten in einem Teilverbau in der Produktion.
Siehe VW80114. Signal bildet (durch eine Gateway-Funktion) den Inhalt des Signals OBD_Driving_Cycle ab.";

CM_ SG_ 851 DiETa_Car "Status Car-Taste";
CM_ SG_ 851 DiETa_Defrost_Taste "Max. Defrost AN/AUS";
CM_ SG_ 851 DiETa_FAS_Stufe "Status FAS-Taste";
CM_ SG_ 851 DiETa_FSH_Taste "Frontscheibenheizung AN/AUS";
CM_ SG_ 851 DiETa_HSH_Taste "Heckscheibenheizung AN/AUS";
CM_ SG_ 851 DiETa_Klima "Status Klimataste";
CM_ SG_ 851 DiETa_Lock_Unlock_Taste "Lock-/Unlock-Taste";
CM_ SG_ 851 DiETa_Mode "Status Modetaste";
CM_ SG_ 851 DiETa_Mode2 "Status Mode2taste (GTE-Taster im VW380 PHEV)";
CM_ SG_ 851 DiETa_Mode_roh "Erweitertes SIgnal zur Erfüllung der OBD-Relevanz für die Funktion Mode auf der DiETa";
CM_ SG_ 851 DiETa_PAO_OFF_Status "Istwert für LED 'OFF' in Anzeige Passenger Airbag On/Off";
CM_ SG_ 851 DiETa_PAO_ON_Status "Istwert für LED 'ON' in Anzeige Passenger Airbag On/Off";
CM_ SG_ 851 DiETa_Parken "Status Parkentaste";
CM_ SG_ 851 DiETa_Reserve_Byte2_4 "Vorhalt, Initialisierung mit '0'";
CM_ SG_ 851 DiETa_Reserve_Byte6_6 "Vorhalt, Initialisierung mit '0'";
CM_ SG_ 851 DiETa_Reserve_Byte7_4 "Vorhalt, Initialisierung mit '0'";
CM_ SG_ 851 DiETa_Reserve_Byte8 "Vorhalt, Initialisierung mit '0'";
CM_ SG_ 851 DiETa_ResponseError "siehe LIN2.0-Specification
(Darf nicht über ein Fehlergueltigkeitsbit abgesichtert werden!)";
CM_ SG_ 851 DiETa_Status "Betriebszustand Direkteinstiegstasten";
CM_ SG_ 851 DiETa_Touch_Event "Touch_Events für Informationen einer Funktionsauslösung auf DiETa, welches dann für bspw. ein akustisches Signal zentral umgesetzt werden können.";
CM_ SG_ 851 DiETa_Warnblink_Taste "Status Warnblinktaster";
CM_ SG_ 851 DiETas_01_BZ "4bit Botschaftszähler, wird mit jeder Sendebotschaft inkrementiert";
CM_ SG_ 851 DiETas_01_CRC "Für MLB:
Berechnung siehe Lastenheft 'Kommunikationsabsicherung für FlexRay und CAN'
Ab MQB und MLBevo:
Berechnung siehe Lastenheft 'End-to-End Kommunikationsabsicherung'

Endwerte siehe Begleitdokument 'S-PDU Kennungsfolgen'";
CM_ SG_ 851 ESP_Off_Taster "Das Signal beschreibt den Zustand der ESP Taste, die im MLBevo vom BCM1 eingelesen wird.
";

CM_ SG_ 1520 BCM1_Stellgroesse_Kl_58s "Rohwert Dimmpoti";
CM_ SG_ 1520 DI_Display_Nachtdesign "Für Displays sind oft  automatische Umschaltungen von Tag-/Nachtdesign vorgesehen.
Es gibt jedoch Zustände, an denen auch tagsüber das Abblendlicht eingeschaltet ist.
z.B. Dauerfahrlicht, Geschwindigkeitsabhängiges 'Licht-An-Bei-Autobahn', 'Regenlicht',";
CM_ SG_ 1520 DI_Fotosensor "Helligkeitswert Fotosensor
Für die Dimmung relevanter Wert zur Sensierung der Umgebungshelligkeit
Im Detail beschrieben im 'Funktionslastenheft Dimmung MQB'.";
CM_ SG_ 1520 DI_KL_58xd "Klemme 58xd Display- und Funktionsbeleuchtung
Mit der Klemme 58xd wird die Helligkeit der Display- und der Funktionsbeleuchtungen der Schalter gesteuert.
Im Detail beschrieben im 'Funktionslastenheft Dimmung MQB'.";
CM_ SG_ 1520 DI_KL_58xs "Suchbeleuchtung Schalter
EIN-AUS-Schaltalgorithmus der allgemeinen Schaltersuchbeleuchtung. 
Im Detail beschrieben im 'Funktionslastenheft Dimmung MQB'.
";
CM_ SG_ 1520 DI_KL_58xt "Timergesteuerte Suchbeleuchtung
Der EIN-AUS-Schaltalgorithmus für die vor- und nachlaufende Schaltersuchbeleuchtungen beim Ein- & Aussteigen; z.B.: Start/Stop-Taster.
Im Detail beschrieben im 'Funktionslastenheft Dimmung MQB'.";

CM_ SG_ 1603 KBI_Einheit_Datum "Anzeigevariante des Datums";
CM_ SG_ 1603 KBI_Einheit_Druck "Einheit des Druckes";
CM_ SG_ 1603 KBI_Einheit_Masse "Einheit der Masse (Verwendung z.B. ASTA)";
CM_ SG_ 1603 KBI_Einheit_Sprache "Siehe BAP-Datenfestlegung UnitMaster";
CM_ SG_ 1603 KBI_Einheit_Streckenanz "Einheit der Streckenanzeige";
CM_ SG_ 1603 KBI_Einheit_Tacho "Information, ob es sich um Meilen- oder Kmh-Kombi handelt, Einheit des Tachos entspricht dem Zifferblatt, Grösse ist nicht veränderlich";
CM_ SG_ 1603 KBI_Einheit_Temp "Einheit der Temperatur";
CM_ SG_ 1603 KBI_Einheit_Uhrzeit "Anzeigevariante der Uhrzeit";
CM_ SG_ 1603 KBI_Einheit_Verbrauch "Einheit der Verbrauchs";
CM_ SG_ 1603 KBI_Einheit_Verbrauch_elektr "Einheit elektrischer Verbrauch";
CM_ SG_ 1603 KBI_Einheit_Verbrauch_Gas "Unterscheidung zwischen M3/h und kg/h für Komfortverbrauchsberechnung.";
CM_ SG_ 1603 KBI_Einheit_Volumen "Einheit des Volumens";
CM_ SG_ 1603 KBI_MFA_v_Einheit_02 "Einheit der Geschwindigkeit, die vom Fahrer im Car-Menü gewählt wurde. Veränderliche Grösse, im Gegensatz zur Einheit des Tachokranzes.

Redundant in der Einheiten_01 Botschaft definiert, um Konsistenz zur BAP-Festlegung zu haben.";

CM_ SG_ 2527679743 ELF_AbfahrtstimerAktiv "Flag zur Kennzeichnung, dass der vom Kunden eingestellte Timer auch aktiviert wurde und Berücksichtigung finden muss";
CM_ SG_ 2527679743 ELF_AbfahrtstimerJahr "Vom Kunden (Profil) eingestellter Abfahrtstimer (Jahr).";
CM_ SG_ 2527679743 ELF_AbfahrtstimerMinute "Vom Kunden eingestellter Abfahrtstimer (Minute).";
CM_ SG_ 2527679743 ELF_AbfahrtstimerMonat "Vom Kunden (Profil) eingestellter Abfahrtstimer (Monat).";
CM_ SG_ 2527679743 ELF_AbfahrtstimerStunde "Vom Kunden (Profil) eingestellter Abfahrtstimer (Stunde).";
CM_ SG_ 2527679743 ELF_AbfahrtstimerTag "Vom Kunden (Profil) eingestellter Abfahrtstimer (Tag).";
CM_ SG_ 2527679743 ELF_KundenwunschKlimatisierung "Vom Kunden (Profil) gewünscht Vorkonditionierung zum eingestellten Abfahrtstimer.";

CM_ SG_ 782 ELF_AnforderungWlanVerbindung "Erweiterte Ladefunktion fordert eine WLAN-Verbindung zum Heimnetzwerk an, um mit dem HEMS Ladedaten austauschen zu können.";
CM_ SG_ 782 ELF_EigenstromGefordert "Kundenwunsch - Nutzung Eigenstrom";
CM_ SG_ 782 ELF_EnergiebedarfMaxSoc "Notwendige Energiemenge, um die HV-Batterie bis Max-SOC zu laden.";
CM_ SG_ 782 ELF_EnergiebedarfMinSoc "Notwendige Energiemenge, um die Batterie des Fahrzeugs auf Min-SOC zu laden";
CM_ SG_ 782 ELF_EnergiebedarfZielSoc "Notwendige Energiemenge, um die Batterie des Fahrzeugs auf den Ziel-SOC zu laden.";
CM_ SG_ 782 ELF_ErwLadenAnforderung "Anforderung zur Uebernahme der Ladesteuerung durch ELF";
CM_ SG_ 782 ELF_EvNeuverhandlung "Fahrzeug fordert eine Ladeplan-Neuverhandlung beim EMS an";
CM_ SG_ 782 ELF_LadeleistungMaxKons "Die aus Grundladen übermittelte max. Ladeleistung des Fahrzeugs mit Leistungsreduktions-Vorgabe konsolidierte maximale Ladeleistung";
CM_ SG_ 782 ELF_Ladeplandauer "Ladedauer (Beginn des Ladevorgangs bis geplantes Ende laut Ladeplan)";
CM_ SG_ 782 ELF_Ladestrategie "Ermittelte Ladestrategie der Erweiterten Ladefunktionen";
CM_ SG_ 782 ELF_PLTabDatenquelle "ELF fordern die Übertragung von Preis-Leistungstabellen an";
CM_ SG_ 782 ELF_PLTabellenGefordert "Signalisiert, ob die Erweiterten Ladefunktionen Preis-Leistungstabellen nutzen können/dürfen oder nicht";
CM_ SG_ 782 ELF_StatusAbfragePLTab "Verarbeitungsstatus der PLTabellen aus den unterschiedlichen Quellen";
CM_ SG_ 782 ELF_StatusLadeplanerstellung "Gibt den internen Status der Basisfunktion LPE wieder";
CM_ SG_ 782 ELF_StatusLadestrategie "Status Erweiterte Ladeunfktionen";

CM_ SG_ 192 EM1_01_BZ "4bit Botschaftszähler, wird mit jeder Sendebotschaft inkrementiert";
CM_ SG_ 192 EM1_01_CRC "Für MLB:
Berechnung siehe Lastenheft 'Kommunikationsabsicherung für FlexRay und CAN'
Ab MQB und MLBevo:
Berechnung siehe Lastenheft 'End-to-End Kommunikationsabsicherung'

Endwerte siehe Begleitdokument 'S-PDU Kennungsfolgen'";
CM_ SG_ 192 EM1_AR_aktiv "Ruckeldämpfer aktiv";
CM_ SG_ 192 EM1_ErwGrenzen_aktiv "Die absoluten Momentengrenzen sind für die Durchführung eines VKM-Starts ggf. aufgeweitet";
CM_ SG_ 192 EM1_Fehler_ElAntriebAbschaltung "Fehler: PWR befindet sich im aktiven Kurzschluss
alle vom EMS gesendeten Max- und Min-Momente und das aktuelle EM-Moment nehmen in diesem Zustand den Wert des für die aktuelle Drehzahl entsprechenden Schleppmoments der E-Maschine an";
CM_ SG_ 192 EM1_Fehler_Notabschaltung "Fehler: Leistungselektronik fordert Abschaltung des HV-Netzes wegen eines schweren Fehlers an";
CM_ SG_ 192 EM1_IstDrehzahl "Momentanwert: E-Maschinen Drehzahl";
CM_ SG_ 192 EM1_Istmodus "aktuelle Betriebsart der E-Maschine...
0: Standby; Kommunikation aktiv; PSM: Aktiver Kurzschluss eingenommen
1: Momentenreglung
2: Drehzahlregeung (interner Regelkreis)
3: Spannungsregelung
4: Drehzahlregelung (externer Regelkreis)
5: interner Inver";
CM_ SG_ 192 EM1_IstMoment "Momentanwert: E-Maschinen Moment";
CM_ SG_ 192 EM1_IstSpannung "Momentanwert: HV-Spannung am PWR";
CM_ SG_ 192 EM1_Max_Moment "maximal darstellbares Moment für eine im Funktionslastenheft definierte Dauer

Die Berechnung der Momentengrenzen wird projektspezifisch festgelegt";
CM_ SG_ 192 EM1_Max_Moment_Gesamt "Maximal mögliches Moment bei der momentanen Maschinendrehzahl bezogen auf die im System verfügbare elektrische Gesamtleistung MO_EM1_Max_Leistung_Gesamt, motorischer Betrieb";
CM_ SG_ 192 EM1_Max_Moment_Lim "Maximales Moment bei der momentanen Maschinendrehzahl, motorischer Betrieb, berechnet aus Abregelstrom MO_EMx_Max_Strom_Lim und aktueller Spannung";
CM_ SG_ 192 EM1_Min_Moment "minimal darstellbares Moment für eine im Funktionslastenheft definierte Dauer

Die Berechnung der Momentengrenzen wird projektspezifisch festgelegt
";
CM_ SG_ 192 EM1_Min_Moment_Gesamt "Minimal mögliches Moment bei der momentanen Maschinendrehzahl bezogen auf die vom System aufnehmbare elektrische Gesamtleistung MO_EM1_Min_Leistung_Gesamt, generatorischer Betrieb";
CM_ SG_ 192 EM1_Min_Moment_Lim "Minimales Moment bei der momentanen Maschinendrehzahl, generatorischer Betrieb, berechnet aus Abregelstrom MO_EMx_Min_Strom_Lim und aktueller Spannung";
CM_ SG_ 192 EM1_Mom_DrzEingriff "Wirksames Moment der EM zum Begrenzen der Drehzahl auf Drehzahlbegrenzung";
CM_ SG_ 192 EM1_Moment_AR_Eingriff "Momentanwert: Eingriffsmoment der Anti-Ruckel-Funktion im PWR";
CM_ SG_ 192 EM1_Raddrehzahl_links "Momentanwert: Raddrehzahl links (Betrag)

Wird im PWR unter Nutzung der ESC-HW-Schnittstelle (Drehzahlfühler-Ausgänge im ESC) berechnet

Einschränkungen:
1. QM-Signal, kein ASIL möglich
2. Nur Betragswert möglich
3. Nach Stillstand oder Drehrichtun";
CM_ SG_ 192 EM1_Raddrehzahl_rechts "Momentanwert: Raddrehzahl rechts (Betrag)

Wird im PWR unter Nutzung der ESC-HW-Schnittstelle (Drehzahlfühler-Ausgänge im ESC) berechnet

Einschränkungen:
1. QM-Signal, kein ASIL möglich
2. Nur Betragswert möglich
3. Nach Stillstand oder Drehrichtu";
CM_ SG_ 192 EM1_Status_DrzEingriff "Status ASR-Eingriff über EM-Regelung";
CM_ SG_ 192 EM1_Strom_HV "Momentanwert: HV DC-Strom des PWR";
BA_DEF_REL_ BU_SG_REL_  "GenSigTimeoutTime" INT 0 65535;
BA_DEF_ BO_  "DiagRequest" ENUM "No", "Yes";
BA_DEF_ BO_  "DiagResponse" ENUM "No", "Yes";
BA_DEF_ BO_  "DiagState" ENUM "No", "Yes";
BA_DEF_ BO_  "GenMsgChkConstant" HEX 0 4095;
BA_DEF_ BO_  "GenMsgCycleTime" INT 0 65535;
BA_DEF_ BO_  "GenMsgCycleTimeFast" INT 0 65535;
BA_DEF_ BO_  "GenMsgDelayTime" INT 0 100000;
BA_DEF_ BO_  "GenMsgILSupport" ENUM "No", "Yes";
BA_DEF_ BO_  "GenMsgNrOfRepetition" INT 0 100;
BA_DEF_ BO_  "GenMsgPDUConstants" STRING;
BA_DEF_ BO_  "GenMsgSendType" ENUM "Cyclic", "not_used", "not_used", "not_used", "not_used", "not_used", "not_used", "IfActive", "NoMsgSendType";
BA_DEF_ BO_  "GenMsgStartDelayTime" INT 0 100000;
BA_DEF_ BO_  "NmMessage" ENUM "No", "Yes";
BA_DEF_ BO_  "NmhMessage" ENUM "No", "Yes";
BA_DEF_ BO_  "MsgType" ENUM "Application", "NM ", "NMH", "TP2.0", "ISO-TP ", "BAP", "EID", "KS", "XCP_PRE_CONFIGURED", "XCP_RUNTIME_CONFIGURED";
BA_DEF_ BO_  "VAGTP20_API" HEX 0 255;
BA_DEF_ BO_  "VAGTP20_DynConnection" ENUM "No", "Yes";
BA_DEF_ BO_  "VAGTP20_DynSetup" ENUM "No", "Yes";
BA_DEF_ BO_  "VAGTP20_StatConnection" ENUM "No", "Yes";
BA_DEF_ BO_  "CANFD_BRS" ENUM "0", "1";
BA_DEF_ BO_  "VFrameFormat" ENUM "StandardCAN", "ExtendedCAN", "reserved", "reserved", "reserved", "reserved", "reserved", "reserved", "reserved", "reserved", "reserved", "reserved", "reserved", "reserved", "StandardCAN_FD", "ExtendedCAN_FD";
BA_DEF_ SG_  "GenSigActiveRepetitions" INT -2147483648 2147483647;
BA_DEF_ SG_  "GenSigInactiveValue" INT -2147483648 2147483647;
BA_DEF_ SG_  "GenSigSendType" ENUM "Cyclic", "OnWrite", "OnWriteWithRepetition", "OnChange", "OnChangeWithRepetition", "IfActive", "IfActiveWithRepetition", "NoSigSendType", "OnChangeAndIfActive", "OnChangeAndIfActiveWithRepetition";
BA_DEF_ SG_  "GenSigStartValue" INT -2147483648 2147483647;
BA_DEF_ SG_  "NWM-WakeupAllowed" ENUM "No", "Yes";
BA_DEF_ SG_  "GenSigFuncType" ENUM "NoFunction", "MsgCounter", "CRC-8", "XOR", "XOR-2", "DatedBit", "SW-Kl15", "CHK", "Constant", "Protocol", "CRC-8-SAE_J1850", "CRC-32", "DataLength", "DataID", "MsgCounter16", "SOK-Signatur", "Cluster";
BA_DEF_ SG_  "GenSigSwitchedByIgnition" ENUM "No", "Yes";
BA_DEF_ SG_  "Fehlerwert" HEX 0 2147483647;
BA_DEF_ SG_  "GenSigMissingSourceValue" HEX 0 2147483647;
BA_DEF_DEF_REL_  "GenSigTimeoutTime" 0;
BA_DEF_DEF_  "DiagRequest" "No";
BA_DEF_DEF_  "DiagResponse" "No";
BA_DEF_DEF_  "DiagState" "No";
BA_DEF_DEF_  "GenMsgChkConstant" 0;
BA_DEF_DEF_  "GenMsgCycleTime" 0;
BA_DEF_DEF_  "GenMsgCycleTimeFast" 0;
BA_DEF_DEF_  "GenMsgDelayTime" 0;
BA_DEF_DEF_  "GenMsgILSupport" "No";
BA_DEF_DEF_  "GenMsgNrOfRepetition" 0;
BA_DEF_DEF_  "GenMsgPDUConstants" "";
BA_DEF_DEF_  "GenMsgSendType" "NoMsgSendType";
BA_DEF_DEF_  "GenMsgStartDelayTime" 0;
BA_DEF_DEF_  "NmMessage" "No";
BA_DEF_DEF_  "NmhMessage" "No";
BA_DEF_DEF_  "MsgType" "Application";
BA_DEF_DEF_  "VAGTP20_API" 0;
BA_DEF_DEF_  "VAGTP20_DynConnection" "No";
BA_DEF_DEF_  "VAGTP20_DynSetup" "No";
BA_DEF_DEF_  "VAGTP20_StatConnection" "No";
BA_DEF_DEF_  "CANFD_BRS" "1";
BA_DEF_DEF_  "VFrameFormat" "StandardCAN";
BA_DEF_DEF_  "GenSigActiveRepetitions" 0;
BA_DEF_DEF_  "GenSigInactiveValue" 0;
BA_DEF_DEF_  "GenSigSendType" "NoSigSendType";
BA_DEF_DEF_  "GenSigStartValue" 0;
BA_DEF_DEF_  "NWM-WakeupAllowed" "No";
BA_DEF_DEF_  "GenSigFuncType" "NoFunction";
BA_DEF_DEF_  "GenSigSwitchedByIgnition" "Yes";
BA_DEF_DEF_  "Fehlerwert" 0;
BA_DEF_DEF_  "GenSigMissingSourceValue" 0;
BA_ "GenMsgCycleTime" BO_ 397 10;
BA_ "GenMsgILSupport" BO_ 397 1;
BA_ "GenMsgPDUConstants" BO_ 397 "0x9c,0xcc,0xe1,0x4c,0xc9,0x39,0xe3,0x53,0x78,0x33,0x15,0x49,0x55,0x0a,0x62,0x83";
BA_ "GenMsgSendType" BO_ 397 0;
BA_ "VFrameFormat" BO_ 397 14;
BA_ "GenMsgCycleTime" BO_ 419 20;
BA_ "GenMsgILSupport" BO_ 419 1;
BA_ "GenMsgSendType" BO_ 419 0;
BA_ "VFrameFormat" BO_ 419 14;
BA_ "GenMsgCycleTime" BO_ 2589283412 500;
BA_ "GenMsgILSupport" BO_ 2589283412 1;
BA_ "GenMsgSendType" BO_ 2589283412 0;
BA_ "VFrameFormat" BO_ 2589283412 15;
BA_ "GenMsgCycleTime" BO_ 2589283608 500;
BA_ "GenMsgILSupport" BO_ 2589283608 1;
BA_ "GenMsgSendType" BO_ 2589283608 0;
BA_ "VFrameFormat" BO_ 2589283608 15;
BA_ "GenMsgCycleTime" BO_ 2589283606 1000;
BA_ "GenMsgILSupport" BO_ 2589283606 1;
BA_ "GenMsgSendType" BO_ 2589283606 0;
BA_ "VFrameFormat" BO_ 2589283606 15;
BA_ "GenMsgCycleTime" BO_ 1021 100;
BA_ "GenMsgILSupport" BO_ 1021 1;
BA_ "GenMsgSendType" BO_ 1021 0;
BA_ "VFrameFormat" BO_ 1021 14;
BA_ "GenMsgCycleTime" BO_ 2463978716 100;
BA_ "GenMsgDelayTime" BO_ 2463978716 10;
BA_ "GenMsgILSupport" BO_ 2463978716 1;
BA_ "GenMsgPDUConstants" BO_ 2463978716 "0x4e,0x5e,0x5a,0xed,0x29,0x2e,0x91,0x2d,0xc6,0xde,0x1b,0x98,0x92,0x8b,0x52,0x8a";
BA_ "GenMsgSendType" BO_ 2463978716 0;
BA_ "VFrameFormat" BO_ 2463978716 15;
BA_ "GenMsgCycleTime" BO_ 2463978717 100;
BA_ "GenMsgILSupport" BO_ 2463978717 1;
BA_ "GenMsgSendType" BO_ 2463978717 0;
BA_ "VFrameFormat" BO_ 2463978717 15;
BA_ "GenMsgCycleTime" BO_ 2463978718 100;
BA_ "GenMsgILSupport" BO_ 2463978718 1;
BA_ "GenMsgPDUConstants" BO_ 2463978718 "0x28,0x30,0x1f,0x9e,0x51,0xab,0x2f,0xd3,0x39,0x6f,0x37,0xfa,0x59,0xa4,0x70,0xce";
BA_ "GenMsgSendType" BO_ 2463978718 0;
BA_ "VFrameFormat" BO_ 2463978718 15;
BA_ "GenMsgCycleTime" BO_ 2589283523 500;
BA_ "GenMsgDelayTime" BO_ 2589283523 50;
BA_ "GenMsgILSupport" BO_ 2589283523 1;
BA_ "GenMsgSendType" BO_ 2589283523 0;
BA_ "VFrameFormat" BO_ 2589283523 15;
BA_ "GenMsgCycleTime" BO_ 2589283543 500;
BA_ "GenMsgDelayTime" BO_ 2589283543 50;
BA_ "GenMsgSendType" BO_ 2589283543 0;
BA_ "VFrameFormat" BO_ 2589283543 15;
BA_ "GenMsgCycleTime" BO_ 2589283524 500;
BA_ "GenMsgDelayTime" BO_ 2589283524 50;
BA_ "GenMsgILSupport" BO_ 2589283524 1;
BA_ "GenMsgSendType" BO_ 2589283524 0;
BA_ "VFrameFormat" BO_ 2589283524 15;
BA_ "GenMsgCycleTime" BO_ 2527679928 500;
BA_ "GenMsgILSupport" BO_ 2527679928 1;
BA_ "GenMsgSendType" BO_ 2527679928 0;
BA_ "VFrameFormat" BO_ 2527679928 15;
BA_ "MsgType" BO_ 2617128448 6;
BA_ "VFrameFormat" BO_ 2617128448 15;
BA_ "MsgType" BO_ 2617128450 6;
BA_ "VFrameFormat" BO_ 2617128450 15;
BA_ "MsgType" BO_ 2617128449 6;
BA_ "VFrameFormat" BO_ 2617128449 15;
BA_ "GenMsgCycleTime" BO_ 902 1000;
BA_ "GenMsgDelayTime" BO_ 902 50;
BA_ "GenMsgILSupport" BO_ 902 1;
BA_ "GenMsgSendType" BO_ 902 0;
BA_ "VFrameFormat" BO_ 902 14;
BA_ "GenMsgCycleTime" BO_ 686 50;
BA_ "GenMsgILSupport" BO_ 686 1;
BA_ "GenMsgPDUConstants" BO_ 686 "0x83,0x50,0xbf,0x5d,0x67,0x68,0x2f,0x4b,0x32,0x4e,0x1a,0xba,0xc4,0x39,0xf5,0xdb";
BA_ "GenMsgSendType" BO_ 686 0;
BA_ "VFrameFormat" BO_ 686 14;
BA_ "GenMsgCycleTime" BO_ 1012 50;
BA_ "GenMsgILSupport" BO_ 1012 1;
BA_ "GenMsgPDUConstants" BO_ 1012 "0x26,0xe4,0xc5,0x16,0xcf,0x20,0x65,0xad,0xed,0x6a,0xa3,0x49,0x02,0x6b,0xb2,0xbd";
BA_ "GenMsgSendType" BO_ 1012 0;
BA_ "VFrameFormat" BO_ 1012 14;
BA_ "GenMsgCycleTime" BO_ 1485 500;
BA_ "GenMsgCycleTimeFast" BO_ 1485 100;
BA_ "GenMsgDelayTime" BO_ 1485 50;
BA_ "GenMsgILSupport" BO_ 1485 1;
BA_ "GenMsgNrOfRepetition" BO_ 1485 5;
BA_ "GenMsgPDUConstants" BO_ 1485 "0x93,0x04,0x18,0x69,0xce,0x8f,0xb1,0x53,0x40,0x2d,0xe4,0xca,0x90,0x25,0x79,0x8c";
BA_ "GenMsgSendType" BO_ 1485 0;
BA_ "VFrameFormat" BO_ 1485 14;
BA_ "GenMsgCycleTime" BO_ 1486 500;
BA_ "GenMsgCycleTimeFast" BO_ 1486 100;
BA_ "GenMsgDelayTime" BO_ 1486 50;
BA_ "GenMsgNrOfRepetition" BO_ 1486 5;
BA_ "GenMsgSendType" BO_ 1486 0;
BA_ "VFrameFormat" BO_ 1486 14;
BA_ "GenMsgCycleTime" BO_ 247 10;
BA_ "GenMsgILSupport" BO_ 247 1;
BA_ "GenMsgPDUConstants" BO_ 247 "0x5f,0xa0,0x44,0xd0,0x63,0x59,0x5b,0xa2,0x68,0x04,0x90,0x87,0x52,0x12,0xb4,0x9e";
BA_ "GenMsgSendType" BO_ 247 0;
BA_ "VFrameFormat" BO_ 247 14;
BA_ "GenMsgCycleTime" BO_ 1484 500;
BA_ "GenMsgDelayTime" BO_ 1484 50;
BA_ "GenMsgILSupport" BO_ 1484 1;
BA_ "GenMsgPDUConstants" BO_ 1484 "0x60,0x76,0x27,0x02,0x3a,0xa8,0x32,0x51,0x8b,0x23,0x1c,0xf4,0xf0,0x97,0x5b,0x07";
BA_ "GenMsgSendType" BO_ 1484 0;
BA_ "VFrameFormat" BO_ 1484 14;
BA_ "MsgType" BO_ 2617127464 6;
BA_ "VFrameFormat" BO_ 2617127464 15;
BA_ "MsgType" BO_ 2617127465 6;
BA_ "VFrameFormat" BO_ 2617127465 15;
BA_ "MsgType" BO_ 2617127424 6;
BA_ "VFrameFormat" BO_ 2617127424 15;
BA_ "MsgType" BO_ 2617127425 6;
BA_ "VFrameFormat" BO_ 2617127425 15;
BA_ "MsgType" BO_ 2617127426 6;
BA_ "VFrameFormat" BO_ 2617127426 15;
BA_ "MsgType" BO_ 2617127427 6;
BA_ "VFrameFormat" BO_ 2617127427 15;
BA_ "MsgType" BO_ 2617127428 6;
BA_ "VFrameFormat" BO_ 2617127428 15;
BA_ "MsgType" BO_ 2617127429 6;
BA_ "VFrameFormat" BO_ 2617127429 15;
BA_ "MsgType" BO_ 2617127430 6;
BA_ "VFrameFormat" BO_ 2617127430 15;
BA_ "MsgType" BO_ 2617127431 6;
BA_ "VFrameFormat" BO_ 2617127431 15;
BA_ "MsgType" BO_ 2617127432 6;
BA_ "VFrameFormat" BO_ 2617127432 15;
BA_ "MsgType" BO_ 2617127433 6;
BA_ "VFrameFormat" BO_ 2617127433 15;
BA_ "MsgType" BO_ 2617127434 6;
BA_ "VFrameFormat" BO_ 2617127434 15;
BA_ "MsgType" BO_ 2617127435 6;
BA_ "VFrameFormat" BO_ 2617127435 15;
BA_ "MsgType" BO_ 2617127436 6;
BA_ "VFrameFormat" BO_ 2617127436 15;
BA_ "MsgType" BO_ 2617127437 6;
BA_ "VFrameFormat" BO_ 2617127437 15;
BA_ "MsgType" BO_ 2617127438 6;
BA_ "VFrameFormat" BO_ 2617127438 15;
BA_ "MsgType" BO_ 2617127439 6;
BA_ "VFrameFormat" BO_ 2617127439 15;
BA_ "MsgType" BO_ 2617127440 6;
BA_ "VFrameFormat" BO_ 2617127440 15;
BA_ "MsgType" BO_ 2617127441 6;
BA_ "VFrameFormat" BO_ 2617127441 15;
BA_ "MsgType" BO_ 2617127442 6;
BA_ "VFrameFormat" BO_ 2617127442 15;
BA_ "MsgType" BO_ 2617127443 6;
BA_ "VFrameFormat" BO_ 2617127443 15;
BA_ "MsgType" BO_ 2617127444 6;
BA_ "VFrameFormat" BO_ 2617127444 15;
BA_ "MsgType" BO_ 2617127445 6;
BA_ "VFrameFormat" BO_ 2617127445 15;
BA_ "MsgType" BO_ 2617127446 6;
BA_ "VFrameFormat" BO_ 2617127446 15;
BA_ "MsgType" BO_ 2617127447 6;
BA_ "VFrameFormat" BO_ 2617127447 15;
BA_ "MsgType" BO_ 2617127448 6;
BA_ "VFrameFormat" BO_ 2617127448 15;
BA_ "MsgType" BO_ 2617127449 6;
BA_ "VFrameFormat" BO_ 2617127449 15;
BA_ "MsgType" BO_ 2617127450 6;
BA_ "VFrameFormat" BO_ 2617127450 15;
BA_ "MsgType" BO_ 2617127451 6;
BA_ "VFrameFormat" BO_ 2617127451 15;
BA_ "MsgType" BO_ 2617127452 6;
BA_ "VFrameFormat" BO_ 2617127452 15;
BA_ "MsgType" BO_ 2617127453 6;
BA_ "VFrameFormat" BO_ 2617127453 15;
BA_ "MsgType" BO_ 2617127454 6;
BA_ "VFrameFormat" BO_ 2617127454 15;
BA_ "MsgType" BO_ 2617127455 6;
BA_ "VFrameFormat" BO_ 2617127455 15;
BA_ "MsgType" BO_ 2617127456 6;
BA_ "VFrameFormat" BO_ 2617127456 15;
BA_ "MsgType" BO_ 2617127457 6;
BA_ "VFrameFormat" BO_ 2617127457 15;
BA_ "MsgType" BO_ 2617127458 6;
BA_ "VFrameFormat" BO_ 2617127458 15;
BA_ "MsgType" BO_ 2617127459 6;
BA_ "VFrameFormat" BO_ 2617127459 15;
BA_ "MsgType" BO_ 2617127460 6;
BA_ "VFrameFormat" BO_ 2617127460 15;
BA_ "MsgType" BO_ 2617127461 6;
BA_ "VFrameFormat" BO_ 2617127461 15;
BA_ "MsgType" BO_ 2617127462 6;
BA_ "VFrameFormat" BO_ 2617127462 15;
BA_ "MsgType" BO_ 2617127463 6;
BA_ "VFrameFormat" BO_ 2617127463 15;
BA_ "MsgType" BO_ 2617127468 6;
BA_ "VFrameFormat" BO_ 2617127468 15;
BA_ "MsgType" BO_ 2617127469 6;
BA_ "VFrameFormat" BO_ 2617127469 15;
BA_ "MsgType" BO_ 2617127470 6;
BA_ "VFrameFormat" BO_ 2617127470 15;
BA_ "MsgType" BO_ 2617127471 6;
BA_ "VFrameFormat" BO_ 2617127471 15;
BA_ "MsgType" BO_ 2617127472 6;
BA_ "VFrameFormat" BO_ 2617127472 15;
BA_ "MsgType" BO_ 2617127473 6;
BA_ "VFrameFormat" BO_ 2617127473 15;
BA_ "MsgType" BO_ 2617127474 6;
BA_ "VFrameFormat" BO_ 2617127474 15;
BA_ "MsgType" BO_ 2617127475 6;
BA_ "VFrameFormat" BO_ 2617127475 15;
BA_ "MsgType" BO_ 2617127476 6;
BA_ "VFrameFormat" BO_ 2617127476 15;
BA_ "MsgType" BO_ 2617127477 6;
BA_ "VFrameFormat" BO_ 2617127477 15;
BA_ "MsgType" BO_ 2617127478 6;
BA_ "VFrameFormat" BO_ 2617127478 15;
BA_ "MsgType" BO_ 2617127479 6;
BA_ "VFrameFormat" BO_ 2617127479 15;
BA_ "MsgType" BO_ 2617127480 6;
BA_ "VFrameFormat" BO_ 2617127480 15;
BA_ "MsgType" BO_ 2617127481 6;
BA_ "VFrameFormat" BO_ 2617127481 15;
BA_ "MsgType" BO_ 2617127482 6;
BA_ "VFrameFormat" BO_ 2617127482 15;
BA_ "MsgType" BO_ 2617127483 6;
BA_ "VFrameFormat" BO_ 2617127483 15;
BA_ "MsgType" BO_ 2617127484 6;
BA_ "VFrameFormat" BO_ 2617127484 15;
BA_ "MsgType" BO_ 2617127485 6;
BA_ "VFrameFormat" BO_ 2617127485 15;
BA_ "MsgType" BO_ 2617127486 6;
BA_ "VFrameFormat" BO_ 2617127486 15;
BA_ "MsgType" BO_ 2617127487 6;
BA_ "VFrameFormat" BO_ 2617127487 15;
BA_ "MsgType" BO_ 2617127488 6;
BA_ "VFrameFormat" BO_ 2617127488 15;
BA_ "MsgType" BO_ 2617127489 6;
BA_ "VFrameFormat" BO_ 2617127489 15;
BA_ "MsgType" BO_ 2617127490 6;
BA_ "VFrameFormat" BO_ 2617127490 15;
BA_ "MsgType" BO_ 2617127491 6;
BA_ "VFrameFormat" BO_ 2617127491 15;
BA_ "MsgType" BO_ 2617127492 6;
BA_ "VFrameFormat" BO_ 2617127492 15;
BA_ "MsgType" BO_ 2617127493 6;
BA_ "VFrameFormat" BO_ 2617127493 15;
BA_ "MsgType" BO_ 2617127494 6;
BA_ "VFrameFormat" BO_ 2617127494 15;
BA_ "MsgType" BO_ 2617127495 6;
BA_ "VFrameFormat" BO_ 2617127495 15;
BA_ "MsgType" BO_ 2617127496 6;
BA_ "VFrameFormat" BO_ 2617127496 15;
BA_ "MsgType" BO_ 2617127497 6;
BA_ "VFrameFormat" BO_ 2617127497 15;
BA_ "MsgType" BO_ 2617127498 6;
BA_ "VFrameFormat" BO_ 2617127498 15;
BA_ "MsgType" BO_ 2617127499 6;
BA_ "VFrameFormat" BO_ 2617127499 15;
BA_ "MsgType" BO_ 2617127500 6;
BA_ "VFrameFormat" BO_ 2617127500 15;
BA_ "MsgType" BO_ 2617127501 6;
BA_ "VFrameFormat" BO_ 2617127501 15;
BA_ "MsgType" BO_ 2617127502 6;
BA_ "VFrameFormat" BO_ 2617127502 15;
BA_ "MsgType" BO_ 2617127503 6;
BA_ "VFrameFormat" BO_ 2617127503 15;
BA_ "MsgType" BO_ 2617127466 6;
BA_ "VFrameFormat" BO_ 2617127466 15;
BA_ "MsgType" BO_ 2617127467 6;
BA_ "VFrameFormat" BO_ 2617127467 15;
BA_ "DiagRequest" BO_ 2549880529 1;
BA_ "MsgType" BO_ 2549880529 4;
BA_ "VFrameFormat" BO_ 2549880529 15;
BA_ "DiagResponse" BO_ 2550011601 1;
BA_ "MsgType" BO_ 2550011601 4;
BA_ "VFrameFormat" BO_ 2550011601 15;
BA_ "DiagRequest" BO_ 2549880533 1;
BA_ "MsgType" BO_ 2549880533 4;
BA_ "VFrameFormat" BO_ 2549880533 15;
BA_ "DiagResponse" BO_ 2550011605 1;
BA_ "MsgType" BO_ 2550011605 4;
BA_ "VFrameFormat" BO_ 2550011605 15;
BA_ "DiagRequest" BO_ 2549880537 1;
BA_ "MsgType" BO_ 2549880537 4;
BA_ "VFrameFormat" BO_ 2549880537 15;
BA_ "DiagResponse" BO_ 2550011609 1;
BA_ "MsgType" BO_ 2550011609 4;
BA_ "VFrameFormat" BO_ 2550011609 15;
BA_ "DiagRequest" BO_ 2549880561 1;
BA_ "MsgType" BO_ 2549880561 4;
BA_ "VFrameFormat" BO_ 2549880561 15;
BA_ "DiagResponse" BO_ 2550011633 1;
BA_ "MsgType" BO_ 2550011633 4;
BA_ "VFrameFormat" BO_ 2550011633 15;
BA_ "GenMsgCycleTime" BO_ 1714 1000;
BA_ "GenMsgILSupport" BO_ 1714 1;
BA_ "GenMsgSendType" BO_ 1714 0;
BA_ "VFrameFormat" BO_ 1714 14;
BA_ "GenMsgCycleTime" BO_ 851 80;
BA_ "GenMsgILSupport" BO_ 851 1;
BA_ "GenMsgPDUConstants" BO_ 851 "0x3a,0x97,0x6b,0x70,0x1e,0x84,0xe1,0xb4,0xde,0xb8,0x03,0xe7,0x33,0x20,0x3f,0x7c";
BA_ "GenMsgSendType" BO_ 851 0;
BA_ "VFrameFormat" BO_ 851 14;
BA_ "GenMsgCycleTime" BO_ 1520 200;
BA_ "GenMsgDelayTime" BO_ 1520 50;
BA_ "GenMsgILSupport" BO_ 1520 1;
BA_ "GenMsgSendType" BO_ 1520 0;
BA_ "VFrameFormat" BO_ 1520 14;
BA_ "GenMsgCycleTime" BO_ 1603 1000;
BA_ "GenMsgDelayTime" BO_ 1603 100;
BA_ "GenMsgILSupport" BO_ 1603 1;
BA_ "GenMsgSendType" BO_ 1603 0;
BA_ "VFrameFormat" BO_ 1603 14;
BA_ "GenMsgCycleTime" BO_ 2527679743 2000;
BA_ "GenMsgDelayTime" BO_ 2527679743 50;
BA_ "GenMsgILSupport" BO_ 2527679743 1;
BA_ "GenMsgSendType" BO_ 2527679743 0;
BA_ "VFrameFormat" BO_ 2527679743 15;
BA_ "GenMsgCycleTime" BO_ 782 30;
BA_ "GenMsgILSupport" BO_ 782 1;
BA_ "GenMsgSendType" BO_ 782 0;
BA_ "VFrameFormat" BO_ 782 14;
BA_ "GenMsgCycleTime" BO_ 192 10;
BA_ "GenMsgILSupport" BO_ 192 1;
BA_ "GenMsgPDUConstants" BO_ 192 "0x2f,0x44,0x72,0xd3,0x07,0xf2,0x39,0x09,0x8d,0x6f,0x57,0x20,0x37,0xf9,0x9b,0xfa";
BA_ "GenMsgSendType" BO_ 192 0;
BA_ "VFrameFormat" BO_ 192 14;
BA_ "GenSigSendType" SG_ 397 BMS_MV_01_BZ 0;
BA_ "GenSigFuncType" SG_ 397 BMS_MV_01_BZ 1;
BA_ "GenSigSwitchedByIgnition" SG_ 397 BMS_MV_01_BZ 0;
BA_ "GenSigSendType" SG_ 397 BMS_MV_01_CRC 0;
BA_ "GenSigFuncType" SG_ 397 BMS_MV_01_CRC 2;
BA_ "GenSigSwitchedByIgnition" SG_ 397 BMS_MV_01_CRC 0;
BA_ "GenSigSendType" SG_ 397 BMS_MV_IstSpannung 0;
BA_ "GenSigStartValue" SG_ 397 BMS_MV_IstSpannung 254;
BA_ "GenSigSwitchedByIgnition" SG_ 397 BMS_MV_IstSpannung 0;
BA_ "Fehlerwert" SG_ 397 BMS_MV_IstSpannung 255;
BA_ "GenSigSendType" SG_ 397 BMS_MV_IstSpannung_Zwkr 0;
BA_ "GenSigStartValue" SG_ 397 BMS_MV_IstSpannung_Zwkr 254;
BA_ "GenSigSwitchedByIgnition" SG_ 397 BMS_MV_IstSpannung_Zwkr 0;
BA_ "Fehlerwert" SG_ 397 BMS_MV_IstSpannung_Zwkr 255;
BA_ "GenSigSendType" SG_ 397 BMS_MV_IstStrom 0;
BA_ "GenSigStartValue" SG_ 397 BMS_MV_IstStrom 4094;
BA_ "GenSigSwitchedByIgnition" SG_ 397 BMS_MV_IstStrom 0;
BA_ "Fehlerwert" SG_ 397 BMS_MV_IstStrom 4095;
BA_ "GenSigSendType" SG_ 397 BMS_MV_SOC_HiRes 0;
BA_ "GenSigStartValue" SG_ 397 BMS_MV_SOC_HiRes 2046;
BA_ "GenSigSwitchedByIgnition" SG_ 397 BMS_MV_SOC_HiRes 0;
BA_ "Fehlerwert" SG_ 397 BMS_MV_SOC_HiRes 2047;
BA_ "GenSigSendType" SG_ 419 BMS_MV_MaxDyn_EntladeStrom 0;
BA_ "GenSigStartValue" SG_ 419 BMS_MV_MaxDyn_EntladeStrom 2046;
BA_ "GenSigSwitchedByIgnition" SG_ 419 BMS_MV_MaxDyn_EntladeStrom 0;
BA_ "Fehlerwert" SG_ 419 BMS_MV_MaxDyn_EntladeStrom 2047;
BA_ "GenSigSendType" SG_ 419 BMS_MV_MaxDyn_LadeStrom 0;
BA_ "GenSigStartValue" SG_ 419 BMS_MV_MaxDyn_LadeStrom 2046;
BA_ "GenSigSwitchedByIgnition" SG_ 419 BMS_MV_MaxDyn_LadeStrom 0;
BA_ "Fehlerwert" SG_ 419 BMS_MV_MaxDyn_LadeStrom 2047;
BA_ "GenSigSendType" SG_ 419 BMS_MV_Min_EntladeSpannung 0;
BA_ "GenSigStartValue" SG_ 419 BMS_MV_Min_EntladeSpannung 254;
BA_ "GenSigSwitchedByIgnition" SG_ 419 BMS_MV_Min_EntladeSpannung 0;
BA_ "Fehlerwert" SG_ 419 BMS_MV_Min_EntladeSpannung 255;
BA_ "GenSigSendType" SG_ 419 BMS_MV_MinDyn_LadeSpannung 0;
BA_ "GenSigStartValue" SG_ 419 BMS_MV_MinDyn_LadeSpannung 254;
BA_ "GenSigSwitchedByIgnition" SG_ 419 BMS_MV_MinDyn_LadeSpannung 0;
BA_ "GenSigSendType" SG_ 419 BMS_MV_MinDynEntladeSpannung 0;
BA_ "GenSigStartValue" SG_ 419 BMS_MV_MinDynEntladeSpannung 254;
BA_ "GenSigSwitchedByIgnition" SG_ 419 BMS_MV_MinDynEntladeSpannung 0;
BA_ "GenSigSendType" SG_ 2589283412 BMS_MV_IstRuecklaufTemperatur 0;
BA_ "GenSigStartValue" SG_ 2589283412 BMS_MV_IstRuecklaufTemperatur 254;
BA_ "GenSigSwitchedByIgnition" SG_ 2589283412 BMS_MV_IstRuecklaufTemperatur 0;
BA_ "Fehlerwert" SG_ 2589283412 BMS_MV_IstRuecklaufTemperatur 255;
BA_ "GenSigSendType" SG_ 2589283412 BMS_MV_IstVorlaufTemperatur 0;
BA_ "GenSigStartValue" SG_ 2589283412 BMS_MV_IstVorlaufTemperatur 254;
BA_ "GenSigSwitchedByIgnition" SG_ 2589283412 BMS_MV_IstVorlaufTemperatur 0;
BA_ "Fehlerwert" SG_ 2589283412 BMS_MV_IstVorlaufTemperatur 255;
BA_ "GenSigSendType" SG_ 2589283412 BMS_MV_Soll_PWM_Pumpe 0;
BA_ "GenSigStartValue" SG_ 2589283412 BMS_MV_Soll_PWM_Pumpe 15;
BA_ "GenSigSwitchedByIgnition" SG_ 2589283412 BMS_MV_Soll_PWM_Pumpe 0;
BA_ "GenSigSendType" SG_ 2589283412 BMS_MV_SollVolumenstrom 0;
BA_ "GenSigStartValue" SG_ 2589283412 BMS_MV_SollVolumenstrom 62;
BA_ "GenSigSwitchedByIgnition" SG_ 2589283412 BMS_MV_SollVolumenstrom 0;
BA_ "Fehlerwert" SG_ 2589283412 BMS_MV_SollVolumenstrom 63;
BA_ "GenSigSendType" SG_ 2589283412 BMS_MV_SollVorlauftemperatur 0;
BA_ "GenSigStartValue" SG_ 2589283412 BMS_MV_SollVorlauftemperatur 254;
BA_ "GenSigSwitchedByIgnition" SG_ 2589283412 BMS_MV_SollVorlauftemperatur 0;
BA_ "Fehlerwert" SG_ 2589283412 BMS_MV_SollVorlauftemperatur 255;
BA_ "GenSigSendType" SG_ 2589283412 BMS_MV_Speichertechnologie 0;
BA_ "GenSigSwitchedByIgnition" SG_ 2589283412 BMS_MV_Speichertechnologie 0;
BA_ "GenSigSendType" SG_ 2589283412 BMS_MV_Temp_Epsilon 0;
BA_ "GenSigSwitchedByIgnition" SG_ 2589283412 BMS_MV_Temp_Epsilon 0;
BA_ "GenSigSendType" SG_ 2589283412 BMS_MV_Temperatur 0;
BA_ "GenSigStartValue" SG_ 2589283412 BMS_MV_Temperatur 254;
BA_ "GenSigSwitchedByIgnition" SG_ 2589283412 BMS_MV_Temperatur 0;
BA_ "Fehlerwert" SG_ 2589283412 BMS_MV_Temperatur 255;
BA_ "GenSigSendType" SG_ 2589283412 BMS_MV_Temperierung_Anf 0;
BA_ "GenSigStartValue" SG_ 2589283412 BMS_MV_Temperierung_Anf 3;
BA_ "GenSigSwitchedByIgnition" SG_ 2589283412 BMS_MV_Temperierung_Anf 0;
BA_ "GenSigSendType" SG_ 2589283608 BMS_MV_Energieinhalt 0;
BA_ "GenSigStartValue" SG_ 2589283608 BMS_MV_Energieinhalt 2046;
BA_ "GenSigSwitchedByIgnition" SG_ 2589283608 BMS_MV_Energieinhalt 0;
BA_ "Fehlerwert" SG_ 2589283608 BMS_MV_Energieinhalt 2047;
BA_ "GenSigSendType" SG_ 2589283608 BMS_MV_MaxEnergieinhalt 0;
BA_ "GenSigStartValue" SG_ 2589283608 BMS_MV_MaxEnergieinhalt 2046;
BA_ "GenSigSwitchedByIgnition" SG_ 2589283608 BMS_MV_MaxEnergieinhalt 0;
BA_ "Fehlerwert" SG_ 2589283608 BMS_MV_MaxEnergieinhalt 2047;
BA_ "GenSigSendType" SG_ 2589283606 BMS_MV_max_Grenz_SOC 0;
BA_ "GenSigStartValue" SG_ 2589283606 BMS_MV_max_Grenz_SOC 31;
BA_ "GenSigSwitchedByIgnition" SG_ 2589283606 BMS_MV_max_Grenz_SOC 0;
BA_ "GenSigSendType" SG_ 2589283606 BMS_MV_SOC_Kaltstart 0;
BA_ "GenSigStartValue" SG_ 2589283606 BMS_MV_SOC_Kaltstart 2046;
BA_ "GenSigSwitchedByIgnition" SG_ 2589283606 BMS_MV_SOC_Kaltstart 0;
BA_ "Fehlerwert" SG_ 2589283606 BMS_MV_SOC_Kaltstart 2047;
BA_ "GenSigSendType" SG_ 1021 BMS_MV_Pred_Entladeperformance 0;
BA_ "GenSigStartValue" SG_ 1021 BMS_MV_Pred_Entladeperformance 126;
BA_ "GenSigSwitchedByIgnition" SG_ 1021 BMS_MV_Pred_Entladeperformance 0;
BA_ "Fehlerwert" SG_ 1021 BMS_MV_Pred_Entladeperformance 127;
BA_ "GenSigSendType" SG_ 1021 BMS_MV_Pred_Ladeperformance 0;
BA_ "GenSigStartValue" SG_ 1021 BMS_MV_Pred_Ladeperformance 126;
BA_ "GenSigSwitchedByIgnition" SG_ 1021 BMS_MV_Pred_Ladeperformance 0;
BA_ "Fehlerwert" SG_ 1021 BMS_MV_Pred_Ladeperformance 127;
BA_ "GenSigSendType" SG_ 1021 BMS_MV_SOHC_DiagSOC 0;
BA_ "GenSigSwitchedByIgnition" SG_ 1021 BMS_MV_SOHC_DiagSOC 0;
BA_ "GenSigSendType" SG_ 1021 BMS_MV_SOHC_DiagStatus 0;
BA_ "GenSigSwitchedByIgnition" SG_ 1021 BMS_MV_SOHC_DiagStatus 0;
BA_ "GenSigSendType" SG_ 2463978716 BMS_MV_12_BZ 0;
BA_ "GenSigFuncType" SG_ 2463978716 BMS_MV_12_BZ 1;
BA_ "GenSigSwitchedByIgnition" SG_ 2463978716 BMS_MV_12_BZ 0;
BA_ "GenSigSendType" SG_ 2463978716 BMS_MV_12_CRC 0;
BA_ "GenSigFuncType" SG_ 2463978716 BMS_MV_12_CRC 2;
BA_ "GenSigSendType" SG_ 2463978716 BMS_MV_Fehler_BattAbschaltung 3;
BA_ "GenSigSwitchedByIgnition" SG_ 2463978716 BMS_MV_Fehler_BattAbschaltung 0;
BA_ "GenSigSendType" SG_ 2463978716 BMS_MV_Fehler_BattAbschaltungAnf 3;
BA_ "GenSigSwitchedByIgnition" SG_ 2463978716 BMS_MV_Fehler_BattAbschaltungAnf 0;
BA_ "GenSigSendType" SG_ 2463978716 BMS_MV_Fehler_Kaltstartleistung 3;
BA_ "GenSigSwitchedByIgnition" SG_ 2463978716 BMS_MV_Fehler_Kaltstartleistung 0;
BA_ "GenSigSendType" SG_ 2463978716 BMS_MV_Fehler_Leistungsred 3;
BA_ "GenSigSwitchedByIgnition" SG_ 2463978716 BMS_MV_Fehler_Leistungsred 0;
BA_ "GenSigSendType" SG_ 2463978716 BMS_MV_Fehler_Notfallreserve 3;
BA_ "GenSigStartValue" SG_ 2463978716 BMS_MV_Fehler_Notfallreserve 3;
BA_ "GenSigSwitchedByIgnition" SG_ 2463978716 BMS_MV_Fehler_Notfallreserve 0;
BA_ "GenSigSendType" SG_ 2463978716 BMS_MV_Fehler_Relay_offen 3;
BA_ "GenSigSwitchedByIgnition" SG_ 2463978716 BMS_MV_Fehler_Relay_offen 0;
BA_ "GenSigSendType" SG_ 2463978716 BMS_MV_Fehler_Relay_verschweisst 3;
BA_ "GenSigSwitchedByIgnition" SG_ 2463978716 BMS_MV_Fehler_Relay_verschweisst 0;
BA_ "GenSigSendType" SG_ 2463978716 BMS_MV_IstModus 3;
BA_ "GenSigStartValue" SG_ 2463978716 BMS_MV_IstModus 7;
BA_ "GenSigSwitchedByIgnition" SG_ 2463978716 BMS_MV_IstModus 0;
BA_ "GenSigSendType" SG_ 2463978716 BMS_MV_Leistungsreduzierung 3;
BA_ "GenSigSwitchedByIgnition" SG_ 2463978716 BMS_MV_Leistungsreduzierung 0;
BA_ "GenSigSendType" SG_ 2463978716 BMS_MV_Peak_EntladeLeistung 0;
BA_ "GenSigStartValue" SG_ 2463978716 BMS_MV_Peak_EntladeLeistung 2046;
BA_ "GenSigSwitchedByIgnition" SG_ 2463978716 BMS_MV_Peak_EntladeLeistung 0;
BA_ "Fehlerwert" SG_ 2463978716 BMS_MV_Peak_EntladeLeistung 2047;
BA_ "GenSigSendType" SG_ 2463978716 BMS_MV_Peak_EntladeSpannung 0;
BA_ "GenSigStartValue" SG_ 2463978716 BMS_MV_Peak_EntladeSpannung 254;
BA_ "GenSigSwitchedByIgnition" SG_ 2463978716 BMS_MV_Peak_EntladeSpannung 0;
BA_ "Fehlerwert" SG_ 2463978716 BMS_MV_Peak_EntladeSpannung 255;
BA_ "GenSigSendType" SG_ 2463978716 BMS_MV_Peak_LadeLeistung 0;
BA_ "GenSigStartValue" SG_ 2463978716 BMS_MV_Peak_LadeLeistung 2046;
BA_ "GenSigSwitchedByIgnition" SG_ 2463978716 BMS_MV_Peak_LadeLeistung 0;
BA_ "Fehlerwert" SG_ 2463978716 BMS_MV_Peak_LadeLeistung 2047;
BA_ "GenSigSendType" SG_ 2463978716 BMS_MV_Peak_LadeSpannung 0;
BA_ "GenSigStartValue" SG_ 2463978716 BMS_MV_Peak_LadeSpannung 254;
BA_ "GenSigSwitchedByIgnition" SG_ 2463978716 BMS_MV_Peak_LadeSpannung 0;
BA_ "Fehlerwert" SG_ 2463978716 BMS_MV_Peak_LadeSpannung 255;
BA_ "GenSigSendType" SG_ 2463978717 BMS_MV_Max_EntladeLeistung 0;
BA_ "GenSigStartValue" SG_ 2463978717 BMS_MV_Max_EntladeLeistung 2046;
BA_ "GenSigSwitchedByIgnition" SG_ 2463978717 BMS_MV_Max_EntladeLeistung 0;
BA_ "Fehlerwert" SG_ 2463978717 BMS_MV_Max_EntladeLeistung 2047;
BA_ "GenSigSendType" SG_ 2463978717 BMS_MV_Max_LadeLeistung 0;
BA_ "GenSigStartValue" SG_ 2463978717 BMS_MV_Max_LadeLeistung 2046;
BA_ "GenSigSwitchedByIgnition" SG_ 2463978717 BMS_MV_Max_LadeLeistung 0;
BA_ "Fehlerwert" SG_ 2463978717 BMS_MV_Max_LadeLeistung 2047;
BA_ "GenSigSendType" SG_ 2463978717 BMS_MV_PerfInd_Entladen 0;
BA_ "GenSigStartValue" SG_ 2463978717 BMS_MV_PerfInd_Entladen 1022;
BA_ "GenSigSwitchedByIgnition" SG_ 2463978717 BMS_MV_PerfInd_Entladen 0;
BA_ "Fehlerwert" SG_ 2463978717 BMS_MV_PerfInd_Entladen 1023;
BA_ "GenSigSendType" SG_ 2463978717 BMS_MV_PerfInd_Laden 0;
BA_ "GenSigStartValue" SG_ 2463978717 BMS_MV_PerfInd_Laden 1022;
BA_ "GenSigSwitchedByIgnition" SG_ 2463978717 BMS_MV_PerfInd_Laden 0;
BA_ "Fehlerwert" SG_ 2463978717 BMS_MV_PerfInd_Laden 1023;
BA_ "GenSigSendType" SG_ 2463978717 BMS_MV_Strat_EntladeSpannung 0;
BA_ "GenSigStartValue" SG_ 2463978717 BMS_MV_Strat_EntladeSpannung 254;
BA_ "GenSigSwitchedByIgnition" SG_ 2463978717 BMS_MV_Strat_EntladeSpannung 0;
BA_ "Fehlerwert" SG_ 2463978717 BMS_MV_Strat_EntladeSpannung 255;
BA_ "GenSigSendType" SG_ 2463978718 BMS_MV_14_BZ 0;
BA_ "GenSigFuncType" SG_ 2463978718 BMS_MV_14_BZ 1;
BA_ "GenSigSwitchedByIgnition" SG_ 2463978718 BMS_MV_14_BZ 0;
BA_ "GenSigSendType" SG_ 2463978718 BMS_MV_14_CRC 0;
BA_ "GenSigFuncType" SG_ 2463978718 BMS_MV_14_CRC 2;
BA_ "GenSigSwitchedByIgnition" SG_ 2463978718 BMS_MV_14_CRC 0;
BA_ "GenSigSendType" SG_ 2463978718 BMS_MV_Max_EntladeStrom_Lim 0;
BA_ "GenSigStartValue" SG_ 2463978718 BMS_MV_Max_EntladeStrom_Lim 2046;
BA_ "GenSigSwitchedByIgnition" SG_ 2463978718 BMS_MV_Max_EntladeStrom_Lim 0;
BA_ "Fehlerwert" SG_ 2463978718 BMS_MV_Max_EntladeStrom_Lim 2047;
BA_ "GenSigSendType" SG_ 2463978718 BMS_MV_Max_LadeSpannung_Lim 0;
BA_ "GenSigStartValue" SG_ 2463978718 BMS_MV_Max_LadeSpannung_Lim 254;
BA_ "GenSigSwitchedByIgnition" SG_ 2463978718 BMS_MV_Max_LadeSpannung_Lim 0;
BA_ "Fehlerwert" SG_ 2463978718 BMS_MV_Max_LadeSpannung_Lim 255;
BA_ "GenSigSendType" SG_ 2463978718 BMS_MV_Max_LadeStrom_Lim 0;
BA_ "GenSigStartValue" SG_ 2463978718 BMS_MV_Max_LadeStrom_Lim 2046;
BA_ "GenSigSwitchedByIgnition" SG_ 2463978718 BMS_MV_Max_LadeStrom_Lim 0;
BA_ "Fehlerwert" SG_ 2463978718 BMS_MV_Max_LadeStrom_Lim 2047;
BA_ "GenSigSendType" SG_ 2463978718 BMS_MV_Min_EntladeSpannung_Lim 0;
BA_ "GenSigStartValue" SG_ 2463978718 BMS_MV_Min_EntladeSpannung_Lim 254;
BA_ "GenSigSwitchedByIgnition" SG_ 2463978718 BMS_MV_Min_EntladeSpannung_Lim 0;
BA_ "Fehlerwert" SG_ 2463978718 BMS_MV_Min_EntladeSpannung_Lim 255;
BA_ "GenSigSendType" SG_ 2463978718 BMS_MV_Strat_LadeSpannung 0;
BA_ "GenSigStartValue" SG_ 2463978718 BMS_MV_Strat_LadeSpannung 254;
BA_ "GenSigSwitchedByIgnition" SG_ 2463978718 BMS_MV_Strat_LadeSpannung 0;
BA_ "Fehlerwert" SG_ 2463978718 BMS_MV_Strat_LadeSpannung 255;
BA_ "GenSigSendType" SG_ 2589283523 BMS_48V_Indc_StChk 0;
BA_ "GenSigStartValue" SG_ 2589283523 BMS_48V_Indc_StChk 1;
BA_ "GenSigSwitchedByIgnition" SG_ 2589283523 BMS_48V_Indc_StChk 0;
BA_ "GenSigSendType" SG_ 2589283523 BMS_48V_Indc_StFail 0;
BA_ "GenSigSwitchedByIgnition" SG_ 2589283523 BMS_48V_Indc_StFail 0;
BA_ "GenSigSendType" SG_ 2589283523 BMS_MV_Dauer_EntladeLeistung 0;
BA_ "GenSigStartValue" SG_ 2589283523 BMS_MV_Dauer_EntladeLeistung 2046;
BA_ "GenSigSwitchedByIgnition" SG_ 2589283523 BMS_MV_Dauer_EntladeLeistung 0;
BA_ "Fehlerwert" SG_ 2589283523 BMS_MV_Dauer_EntladeLeistung 2047;
BA_ "GenSigSendType" SG_ 2589283523 BMS_MV_Dauer_EntladeSpannung 0;
BA_ "GenSigStartValue" SG_ 2589283523 BMS_MV_Dauer_EntladeSpannung 254;
BA_ "GenSigSwitchedByIgnition" SG_ 2589283523 BMS_MV_Dauer_EntladeSpannung 0;
BA_ "Fehlerwert" SG_ 2589283523 BMS_MV_Dauer_EntladeSpannung 255;
BA_ "GenSigSendType" SG_ 2589283523 BMS_MV_Dauer_LadeLeistung 0;
BA_ "GenSigStartValue" SG_ 2589283523 BMS_MV_Dauer_LadeLeistung 2046;
BA_ "GenSigSwitchedByIgnition" SG_ 2589283523 BMS_MV_Dauer_LadeLeistung 0;
BA_ "Fehlerwert" SG_ 2589283523 BMS_MV_Dauer_LadeLeistung 2047;
BA_ "GenSigSendType" SG_ 2589283523 BMS_MV_Dauer_LadeSpannung 0;
BA_ "GenSigStartValue" SG_ 2589283523 BMS_MV_Dauer_LadeSpannung 254;
BA_ "GenSigSwitchedByIgnition" SG_ 2589283523 BMS_MV_Dauer_LadeSpannung 0;
BA_ "Fehlerwert" SG_ 2589283523 BMS_MV_Dauer_LadeSpannung 255;
BA_ "GenSigSendType" SG_ 2589283523 BMS_MV_Dauer_RMS_Strom 0;
BA_ "GenSigStartValue" SG_ 2589283523 BMS_MV_Dauer_RMS_Strom 254;
BA_ "GenSigSwitchedByIgnition" SG_ 2589283523 BMS_MV_Dauer_RMS_Strom 0;
BA_ "Fehlerwert" SG_ 2589283523 BMS_MV_Dauer_RMS_Strom 255;
BA_ "GenSigSendType" SG_ 2589283523 BMS_MV_Kundenwarnung 3;
BA_ "GenSigSwitchedByIgnition" SG_ 2589283523 BMS_MV_Kundenwarnung 0;
BA_ "GenSigSendType" SG_ 2589283523 BMS_MV_OBD_Lampe_Anf 0;
BA_ "GenSigSwitchedByIgnition" SG_ 2589283523 BMS_MV_OBD_Lampe_Anf 0;
BA_ "GenSigSendType" SG_ 2589283523 OBDProtocol_BMS_48V 0;
BA_ "GenSigStartValue" SG_ 2589283523 OBDProtocol_BMS_48V 254;
BA_ "GenSigSwitchedByIgnition" SG_ 2589283523 OBDProtocol_BMS_48V 0;
BA_ "Fehlerwert" SG_ 2589283523 OBDProtocol_BMS_48V 255;
BA_ "GenSigSendType" SG_ 2589283543 SOK_BMS_MV_15_Signatur 0;
BA_ "GenSigFuncType" SG_ 2589283543 SOK_BMS_MV_15_Signatur 15;
BA_ "GenSigSwitchedByIgnition" SG_ 2589283543 SOK_BMS_MV_15_Signatur 0;
BA_ "GenSigSendType" SG_ 2589283524 BMS_MV_EntladeEnergie 0;
BA_ "GenSigStartValue" SG_ 2589283524 BMS_MV_EntladeEnergie 2046;
BA_ "GenSigSwitchedByIgnition" SG_ 2589283524 BMS_MV_EntladeEnergie 0;
BA_ "Fehlerwert" SG_ 2589283524 BMS_MV_EntladeEnergie 2047;
BA_ "GenSigSendType" SG_ 2589283524 BMS_MV_LadeEnergie 0;
BA_ "GenSigStartValue" SG_ 2589283524 BMS_MV_LadeEnergie 2046;
BA_ "GenSigSwitchedByIgnition" SG_ 2589283524 BMS_MV_LadeEnergie 0;
BA_ "Fehlerwert" SG_ 2589283524 BMS_MV_LadeEnergie 2047;
BA_ "GenSigSendType" SG_ 2589283524 BMS_MV_Max_RMS_Strom 0;
BA_ "GenSigStartValue" SG_ 2589283524 BMS_MV_Max_RMS_Strom 254;
BA_ "GenSigSwitchedByIgnition" SG_ 2589283524 BMS_MV_Max_RMS_Strom 0;
BA_ "Fehlerwert" SG_ 2589283524 BMS_MV_Max_RMS_Strom 255;
BA_ "GenSigSendType" SG_ 2589283524 BMS_MV_TRD_Sensfail 3;
BA_ "GenSigSwitchedByIgnition" SG_ 2589283524 BMS_MV_TRD_Sensfail 0;
BA_ "GenSigSendType" SG_ 2589283524 BMS_MV_TRD_Temp 3;
BA_ "GenSigSwitchedByIgnition" SG_ 2589283524 BMS_MV_TRD_Temp 0;
BA_ "GenSigSendType" SG_ 2589283524 BMS_MV_TRD_Voltage 3;
BA_ "GenSigSwitchedByIgnition" SG_ 2589283524 BMS_MV_TRD_Voltage 0;
BA_ "GenSigSendType" SG_ 2527679928 BMS_NV_Indc_StChk 0;
BA_ "GenSigStartValue" SG_ 2527679928 BMS_NV_Indc_StChk 1;
BA_ "GenSigSwitchedByIgnition" SG_ 2527679928 BMS_NV_Indc_StChk 0;
BA_ "GenSigSendType" SG_ 2527679928 BMS_NV_Indc_StFail 0;
BA_ "GenSigSwitchedByIgnition" SG_ 2527679928 BMS_NV_Indc_StFail 0;
BA_ "GenSigSendType" SG_ 2527679928 BMS_NV_OBD_Lampe_Anf 0;
BA_ "GenSigSwitchedByIgnition" SG_ 2527679928 BMS_NV_OBD_Lampe_Anf 0;
BA_ "GenSigSendType" SG_ 2527679928 OBDProtocol_BMS_NV 0;
BA_ "GenSigStartValue" SG_ 2527679928 OBDProtocol_BMS_NV 254;
BA_ "GenSigSwitchedByIgnition" SG_ 2527679928 OBDProtocol_BMS_NV 0;
BA_ "Fehlerwert" SG_ 2527679928 OBDProtocol_BMS_NV 255;
BA_ "GenSigSendType" SG_ 2527679928 SOK_BMS_NV_11_Signatur 0;
BA_ "GenSigFuncType" SG_ 2527679928 SOK_BMS_NV_11_Signatur 15;
BA_ "GenSigSwitchedByIgnition" SG_ 2527679928 SOK_BMS_NV_11_Signatur 0;
BA_ "GenSigFuncType" SG_ 2617128448 CCP_Klima_CRO_01_Data 9;
BA_ "GenSigSwitchedByIgnition" SG_ 2617128448 CCP_Klima_CRO_01_Data 0;
BA_ "GenSigFuncType" SG_ 2617128450 CCP_Klima_CRO_02_Data 9;
BA_ "GenSigSwitchedByIgnition" SG_ 2617128450 CCP_Klima_CRO_02_Data 0;
BA_ "GenSigFuncType" SG_ 2617128449 CCP_Klima_DTO_01_Data 9;
BA_ "GenSigSwitchedByIgnition" SG_ 2617128449 CCP_Klima_DTO_01_Data 0;
BA_ "GenSigSendType" SG_ 902 CHA_Charge_LED 3;
BA_ "GenSigSwitchedByIgnition" SG_ 902 CHA_Charge_LED 0;
BA_ "GenSigSendType" SG_ 902 CHA_Charisma_Taste2_LED 3;
BA_ "GenSigSwitchedByIgnition" SG_ 902 CHA_Charisma_Taste2_LED 0;
BA_ "Fehlerwert" SG_ 902 CHA_Charisma_Taste2_LED 3;
BA_ "GenSigSendType" SG_ 902 CHA_Current_Mode 3;
BA_ "GenSigSwitchedByIgnition" SG_ 902 CHA_Current_Mode 0;
BA_ "GenSigSendType" SG_ 902 CHA_Current_Mode_FPA 3;
BA_ "GenSigSwitchedByIgnition" SG_ 902 CHA_Current_Mode_FPA 0;
BA_ "GenSigSendType" SG_ 902 CHA_Eco_Charisma_LED 3;
BA_ "GenSigSwitchedByIgnition" SG_ 902 CHA_Eco_Charisma_LED 0;
BA_ "GenSigSendType" SG_ 902 CHA_EV_LED 3;
BA_ "GenSigSwitchedByIgnition" SG_ 902 CHA_EV_LED 0;
BA_ "GenSigSendType" SG_ 902 CHA_Fahrer_Umschaltung 3;
BA_ "GenSigSwitchedByIgnition" SG_ 902 CHA_Fahrer_Umschaltung 0;
BA_ "GenSigSendType" SG_ 902 CHA_Kombi_Texte 3;
BA_ "GenSigSwitchedByIgnition" SG_ 902 CHA_Kombi_Texte 0;
BA_ "GenSigSendType" SG_ 902 CHA_Kombi_Texte_02 3;
BA_ "GenSigSwitchedByIgnition" SG_ 902 CHA_Kombi_Texte_02 0;
BA_ "GenSigSendType" SG_ 902 CHA_Offroad_LED 3;
BA_ "GenSigSwitchedByIgnition" SG_ 902 CHA_Offroad_LED 0;
BA_ "Fehlerwert" SG_ 902 CHA_Offroad_LED 3;
BA_ "GenSigSendType" SG_ 902 CHA_ReqPrgDispSetup 3;
BA_ "GenSigSwitchedByIgnition" SG_ 902 CHA_ReqPrgDispSetup 0;
BA_ "GenSigSendType" SG_ 902 CHA_StCurProfDft 3;
BA_ "GenSigSwitchedByIgnition" SG_ 902 CHA_StCurProfDft 0;
BA_ "GenSigSendType" SG_ 902 CHA_Ziel_FahrPr_03_01 3;
BA_ "GenSigSwitchedByIgnition" SG_ 902 CHA_Ziel_FahrPr_03_01 0;
BA_ "GenSigSendType" SG_ 902 CHA_Ziel_FahrPr_03_02 3;
BA_ "GenSigSwitchedByIgnition" SG_ 902 CHA_Ziel_FahrPr_03_02 0;
BA_ "GenSigSendType" SG_ 902 CHA_Ziel_FahrPr_AMB 3;
BA_ "GenSigSwitchedByIgnition" SG_ 902 CHA_Ziel_FahrPr_AMB 0;
BA_ "GenSigSendType" SG_ 902 CHA_Ziel_FahrPr_HSP 3;
BA_ "GenSigSwitchedByIgnition" SG_ 902 CHA_Ziel_FahrPr_HSP 0;
BA_ "GenSigSendType" SG_ 902 CHA_Ziel_FahrPr_IVB 3;
BA_ "GenSigSwitchedByIgnition" SG_ 902 CHA_Ziel_FahrPr_IVB 0;
BA_ "GenSigSendType" SG_ 902 CHA_Ziel_FahrPr_KL 3;
BA_ "GenSigSwitchedByIgnition" SG_ 902 CHA_Ziel_FahrPr_KL 0;
BA_ "GenSigSendType" SG_ 902 CHA_Ziel_FahrPr_RWB 3;
BA_ "GenSigSwitchedByIgnition" SG_ 902 CHA_Ziel_FahrPr_RWB 0;
BA_ "GenSigSendType" SG_ 686 DC_IstSpannung_HV 0;
BA_ "GenSigStartValue" SG_ 686 DC_IstSpannung_HV 4094;
BA_ "GenSigSwitchedByIgnition" SG_ 686 DC_IstSpannung_HV 0;
BA_ "Fehlerwert" SG_ 686 DC_IstSpannung_HV 4095;
BA_ "GenSigSendType" SG_ 686 DC_IstSpannung_NV 0;
BA_ "GenSigStartValue" SG_ 686 DC_IstSpannung_NV 254;
BA_ "GenSigSwitchedByIgnition" SG_ 686 DC_IstSpannung_NV 0;
BA_ "Fehlerwert" SG_ 686 DC_IstSpannung_NV 255;
BA_ "GenSigSendType" SG_ 686 DC_IstStrom_NV 0;
BA_ "GenSigStartValue" SG_ 686 DC_IstStrom_NV 1022;
BA_ "GenSigSwitchedByIgnition" SG_ 686 DC_IstStrom_NV 0;
BA_ "Fehlerwert" SG_ 686 DC_IstStrom_NV 1023;
BA_ "GenSigSendType" SG_ 686 DCDC_01_BZ 0;
BA_ "GenSigFuncType" SG_ 686 DCDC_01_BZ 1;
BA_ "GenSigSwitchedByIgnition" SG_ 686 DCDC_01_BZ 0;
BA_ "GenSigSendType" SG_ 686 DCDC_01_CRC 0;
BA_ "GenSigFuncType" SG_ 686 DCDC_01_CRC 2;
BA_ "GenSigSwitchedByIgnition" SG_ 686 DCDC_01_CRC 0;
BA_ "GenSigSendType" SG_ 1012 DC_HYB_Auslastungsgrad 0;
BA_ "GenSigStartValue" SG_ 1012 DC_HYB_Auslastungsgrad 254;
BA_ "GenSigSwitchedByIgnition" SG_ 1012 DC_HYB_Auslastungsgrad 0;
BA_ "Fehlerwert" SG_ 1012 DC_HYB_Auslastungsgrad 255;
BA_ "GenSigSendType" SG_ 1012 DC_ReserveStrom_NV 0;
BA_ "GenSigStartValue" SG_ 1012 DC_ReserveStrom_NV 1022;
BA_ "GenSigSwitchedByIgnition" SG_ 1012 DC_ReserveStrom_NV 0;
BA_ "Fehlerwert" SG_ 1012 DC_ReserveStrom_NV 1023;
BA_ "GenSigSendType" SG_ 1012 DC_Verbrauch 0;
BA_ "GenSigSwitchedByIgnition" SG_ 1012 DC_Verbrauch 0;
BA_ "GenSigSendType" SG_ 1012 DC_Verbrauch_Ueberlauf 0;
BA_ "GenSigSwitchedByIgnition" SG_ 1012 DC_Verbrauch_Ueberlauf 0;
BA_ "GenSigSendType" SG_ 1012 DC_Verlustleistung 0;
BA_ "GenSigStartValue" SG_ 1012 DC_Verlustleistung 62;
BA_ "GenSigSwitchedByIgnition" SG_ 1012 DC_Verlustleistung 0;
BA_ "Fehlerwert" SG_ 1012 DC_Verlustleistung 63;
BA_ "GenSigSendType" SG_ 1012 DCDC_02_BZ 0;
BA_ "GenSigFuncType" SG_ 1012 DCDC_02_BZ 1;
BA_ "GenSigSwitchedByIgnition" SG_ 1012 DCDC_02_BZ 0;
BA_ "GenSigSendType" SG_ 1012 DCDC_02_CRC 0;
BA_ "GenSigFuncType" SG_ 1012 DCDC_02_CRC 2;
BA_ "GenSigSwitchedByIgnition" SG_ 1012 DCDC_02_CRC 0;
BA_ "GenSigSendType" SG_ 1485 DC_Abregelung_Temperatur 4;
BA_ "GenSigSwitchedByIgnition" SG_ 1485 DC_Abregelung_Temperatur 0;
BA_ "GenSigSendType" SG_ 1485 DC_Derating 4;
BA_ "GenSigSwitchedByIgnition" SG_ 1485 DC_Derating 0;
BA_ "GenSigSendType" SG_ 1485 DC_Fehlerstatus 4;
BA_ "GenSigStartValue" SG_ 1485 DC_Fehlerstatus 7;
BA_ "GenSigSwitchedByIgnition" SG_ 1485 DC_Fehlerstatus 0;
BA_ "GenSigSendType" SG_ 1485 DC_Kl30c_Status 4;
BA_ "GenSigSwitchedByIgnition" SG_ 1485 DC_Kl30c_Status 0;
BA_ "Fehlerwert" SG_ 1485 DC_Kl30c_Status 3;
BA_ "GenSigSendType" SG_ 1485 DC_OBD_Lampe_Anf 0;
BA_ "GenSigSwitchedByIgnition" SG_ 1485 DC_OBD_Lampe_Anf 0;
BA_ "GenSigSendType" SG_ 1485 DC_Peakstrom_verfuegbar 4;
BA_ "GenSigSwitchedByIgnition" SG_ 1485 DC_Peakstrom_verfuegbar 0;
BA_ "GenSigSendType" SG_ 1485 DC_SollVolumenstrom 0;
BA_ "GenSigStartValue" SG_ 1485 DC_SollVolumenstrom 62;
BA_ "GenSigSwitchedByIgnition" SG_ 1485 DC_SollVolumenstrom 0;
BA_ "Fehlerwert" SG_ 1485 DC_SollVolumenstrom 63;
BA_ "GenSigSendType" SG_ 1485 DC_Status_Spgfreiheit_HV 4;
BA_ "GenSigSwitchedByIgnition" SG_ 1485 DC_Status_Spgfreiheit_HV 0;
BA_ "Fehlerwert" SG_ 1485 DC_Status_Spgfreiheit_HV 3;
BA_ "GenSigSendType" SG_ 1485 DC_Temperatur 0;
BA_ "GenSigStartValue" SG_ 1485 DC_Temperatur 254;
BA_ "GenSigSwitchedByIgnition" SG_ 1485 DC_Temperatur 0;
BA_ "Fehlerwert" SG_ 1485 DC_Temperatur 255;
BA_ "GenSigSendType" SG_ 1485 DC_Temperatur_Alarm 0;
BA_ "GenSigSwitchedByIgnition" SG_ 1485 DC_Temperatur_Alarm 0;
BA_ "Fehlerwert" SG_ 1485 DC_Temperatur_Alarm 1;
BA_ "GenSigSendType" SG_ 1485 DC_Warnlampe_Anf 0;
BA_ "GenSigSwitchedByIgnition" SG_ 1485 DC_Warnlampe_Anf 0;
BA_ "GenSigSendType" SG_ 1485 DCDC_03_BZ 0;
BA_ "GenSigFuncType" SG_ 1485 DCDC_03_BZ 1;
BA_ "GenSigSwitchedByIgnition" SG_ 1485 DCDC_03_BZ 0;
BA_ "GenSigSendType" SG_ 1485 DCDC_03_CRC 0;
BA_ "GenSigFuncType" SG_ 1485 DCDC_03_CRC 2;
BA_ "GenSigSwitchedByIgnition" SG_ 1485 DCDC_03_CRC 0;
BA_ "GenSigSendType" SG_ 1485 DCDC_NV_Indc_StChk 0;
BA_ "GenSigStartValue" SG_ 1485 DCDC_NV_Indc_StChk 1;
BA_ "GenSigSwitchedByIgnition" SG_ 1485 DCDC_NV_Indc_StChk 0;
BA_ "GenSigSendType" SG_ 1485 DCDC_NV_Indc_StFail 0;
BA_ "GenSigSwitchedByIgnition" SG_ 1485 DCDC_NV_Indc_StFail 0;
BA_ "GenSigSendType" SG_ 1485 OBDProtocol_DCDC_NV 0;
BA_ "GenSigStartValue" SG_ 1485 OBDProtocol_DCDC_NV 254;
BA_ "GenSigSwitchedByIgnition" SG_ 1485 OBDProtocol_DCDC_NV 0;
BA_ "Fehlerwert" SG_ 1485 OBDProtocol_DCDC_NV 255;
BA_ "GenSigSendType" SG_ 1486 SOK_DCDC_03_Signatur 0;
BA_ "GenSigFuncType" SG_ 1486 SOK_DCDC_03_Signatur 15;
BA_ "GenSigSwitchedByIgnition" SG_ 1486 SOK_DCDC_03_Signatur 0;
BA_ "GenSigSendType" SG_ 247 DC_Fehler_extern 0;
BA_ "GenSigSwitchedByIgnition" SG_ 247 DC_Fehler_extern 0;
BA_ "Fehlerwert" SG_ 247 DC_Fehler_extern 1;
BA_ "GenSigSendType" SG_ 247 DC_Fehler_intern 0;
BA_ "GenSigSwitchedByIgnition" SG_ 247 DC_Fehler_intern 0;
BA_ "GenSigSendType" SG_ 247 DC_IstLeistung_HV 0;
BA_ "GenSigStartValue" SG_ 247 DC_IstLeistung_HV 1022;
BA_ "GenSigSwitchedByIgnition" SG_ 247 DC_IstLeistung_HV 0;
BA_ "Fehlerwert" SG_ 247 DC_IstLeistung_HV 1023;
BA_ "GenSigSendType" SG_ 247 DC_IstModus_02 0;
BA_ "GenSigStartValue" SG_ 247 DC_IstModus_02 7;
BA_ "GenSigSwitchedByIgnition" SG_ 247 DC_IstModus_02 0;
BA_ "Fehlerwert" SG_ 247 DC_IstModus_02 5;
BA_ "GenSigSendType" SG_ 247 DC_IstStrom_HV 0;
BA_ "GenSigStartValue" SG_ 247 DC_IstStrom_HV 1022;
BA_ "GenSigSwitchedByIgnition" SG_ 247 DC_IstStrom_HV 0;
BA_ "Fehlerwert" SG_ 247 DC_IstStrom_HV 1023;
BA_ "GenSigSendType" SG_ 247 DC_Status_EoHVL 0;
BA_ "GenSigSwitchedByIgnition" SG_ 247 DC_Status_EoHVL 0;
BA_ "Fehlerwert" SG_ 247 DC_Status_EoHVL 3;
BA_ "GenSigSendType" SG_ 247 DC_Status_Spgfreiheit 0;
BA_ "GenSigSwitchedByIgnition" SG_ 247 DC_Status_Spgfreiheit 0;
BA_ "GenSigSendType" SG_ 247 DC_Vorladung_Status 0;
BA_ "GenSigSwitchedByIgnition" SG_ 247 DC_Vorladung_Status 0;
BA_ "GenSigSendType" SG_ 247 DCDC_04_BZ 0;
BA_ "GenSigFuncType" SG_ 247 DCDC_04_BZ 1;
BA_ "GenSigSwitchedByIgnition" SG_ 247 DCDC_04_BZ 0;
BA_ "GenSigSendType" SG_ 247 DCDC_04_CRC 0;
BA_ "GenSigFuncType" SG_ 247 DCDC_04_CRC 2;
BA_ "GenSigSwitchedByIgnition" SG_ 247 DCDC_04_CRC 0;
BA_ "GenSigSendType" SG_ 1484 DC_MV_12V_Bordnetzstuetzung 3;
BA_ "GenSigSwitchedByIgnition" SG_ 1484 DC_MV_12V_Bordnetzstuetzung 0;
BA_ "GenSigSendType" SG_ 1484 DC_MV_Abregelung_Temperatur 3;
BA_ "GenSigSwitchedByIgnition" SG_ 1484 DC_MV_Abregelung_Temperatur 0;
BA_ "GenSigSendType" SG_ 1484 DC_MV_Derating 0;
BA_ "GenSigSwitchedByIgnition" SG_ 1484 DC_MV_Derating 0;
BA_ "GenSigSendType" SG_ 1484 DC_MV_Fehlerstatus 3;
BA_ "GenSigStartValue" SG_ 1484 DC_MV_Fehlerstatus 7;
BA_ "GenSigSwitchedByIgnition" SG_ 1484 DC_MV_Fehlerstatus 0;
BA_ "GenSigSendType" SG_ 1484 DC_MV_IstModus_02 3;
BA_ "GenSigStartValue" SG_ 1484 DC_MV_IstModus_02 7;
BA_ "GenSigSwitchedByIgnition" SG_ 1484 DC_MV_IstModus_02 0;
BA_ "Fehlerwert" SG_ 1484 DC_MV_IstModus_02 5;
BA_ "GenSigSendType" SG_ 1484 DC_MV_Temperatur 0;
BA_ "GenSigStartValue" SG_ 1484 DC_MV_Temperatur 254;
BA_ "GenSigSwitchedByIgnition" SG_ 1484 DC_MV_Temperatur 0;
BA_ "Fehlerwert" SG_ 1484 DC_MV_Temperatur 255;
BA_ "GenSigSendType" SG_ 1484 DC_MV_Tiefsetzen_Notbetrieb 3;
BA_ "GenSigSwitchedByIgnition" SG_ 1484 DC_MV_Tiefsetzen_Notbetrieb 0;
BA_ "GenSigSendType" SG_ 1484 DCDC_MV_03_BZ 0;
BA_ "GenSigFuncType" SG_ 1484 DCDC_MV_03_BZ 1;
BA_ "GenSigSwitchedByIgnition" SG_ 1484 DCDC_MV_03_BZ 0;
BA_ "GenSigSendType" SG_ 1484 DCDC_MV_03_CRC 0;
BA_ "GenSigFuncType" SG_ 1484 DCDC_MV_03_CRC 2;
BA_ "GenSigSwitchedByIgnition" SG_ 1484 DCDC_MV_03_CRC 0;
BA_ "GenSigSendType" SG_ 1484 DCDC_MV_Peakstrom_verfuegbar 3;
BA_ "GenSigSwitchedByIgnition" SG_ 1484 DCDC_MV_Peakstrom_verfuegbar 0;
BA_ "GenSigSwitchedByIgnition" SG_ 2617127464 DEV_Klima_BET_Req_01_Data 0;
BA_ "GenSigSwitchedByIgnition" SG_ 2617127465 DEV_Klima_BET_Resp_01_Data 0;
BA_ "GenSigSwitchedByIgnition" SG_ 2617127424 DEV_Klima_Tx_00_Data 0;
BA_ "GenSigSwitchedByIgnition" SG_ 2617127425 DEV_Klima_Tx_01_Data 0;
BA_ "GenSigSwitchedByIgnition" SG_ 2617127426 DEV_Klima_Tx_02_Data 0;
BA_ "GenSigSwitchedByIgnition" SG_ 2617127427 DEV_Klima_Tx_03_Data 0;
BA_ "GenSigSwitchedByIgnition" SG_ 2617127428 DEV_Klima_Tx_04_Data 0;
BA_ "GenSigSwitchedByIgnition" SG_ 2617127429 DEV_Klima_Tx_05_Data 0;
BA_ "GenSigSwitchedByIgnition" SG_ 2617127430 DEV_Klima_Tx_06_Data 0;
BA_ "GenSigSwitchedByIgnition" SG_ 2617127431 DEV_Klima_Tx_07_Data 0;
BA_ "GenSigSwitchedByIgnition" SG_ 2617127432 DEV_Klima_Tx_08_Data 0;
BA_ "GenSigSwitchedByIgnition" SG_ 2617127433 DEV_Klima_Tx_09_Data 0;
BA_ "GenSigSwitchedByIgnition" SG_ 2617127434 DEV_Klima_Tx_0A_Data 0;
BA_ "GenSigSwitchedByIgnition" SG_ 2617127435 DEV_Klima_Tx_0B_Data 0;
BA_ "GenSigSwitchedByIgnition" SG_ 2617127436 DEV_Klima_Tx_0C_Data 0;
BA_ "GenSigSwitchedByIgnition" SG_ 2617127437 DEV_Klima_Tx_0D_Data 0;
BA_ "GenSigSwitchedByIgnition" SG_ 2617127438 DEV_Klima_Tx_0E_Data 0;
BA_ "GenSigSwitchedByIgnition" SG_ 2617127439 DEV_Klima_Tx_0F_Data 0;
BA_ "GenSigSwitchedByIgnition" SG_ 2617127440 DEV_Klima_Tx_10_Data 0;
BA_ "GenSigSwitchedByIgnition" SG_ 2617127441 DEV_Klima_Tx_11_Data 0;
BA_ "GenSigSwitchedByIgnition" SG_ 2617127442 DEV_Klima_Tx_12_Data 0;
BA_ "GenSigSwitchedByIgnition" SG_ 2617127443 DEV_Klima_Tx_13_Data 0;
BA_ "GenSigSwitchedByIgnition" SG_ 2617127444 DEV_Klima_Tx_14_Data 0;
BA_ "GenSigSwitchedByIgnition" SG_ 2617127445 DEV_Klima_Tx_15_Data 0;
BA_ "GenSigSwitchedByIgnition" SG_ 2617127446 DEV_Klima_Tx_16_Data 0;
BA_ "GenSigSwitchedByIgnition" SG_ 2617127447 DEV_Klima_Tx_17_Data 0;
BA_ "GenSigSwitchedByIgnition" SG_ 2617127448 DEV_Klima_Tx_18_Data 0;
BA_ "GenSigSwitchedByIgnition" SG_ 2617127449 DEV_Klima_Tx_19_Data 0;
BA_ "GenSigSwitchedByIgnition" SG_ 2617127450 DEV_Klima_Tx_1A_Data 0;
BA_ "GenSigSwitchedByIgnition" SG_ 2617127451 DEV_Klima_Tx_1B_Data 0;
BA_ "GenSigSwitchedByIgnition" SG_ 2617127452 DEV_Klima_Tx_1C_Data 0;
BA_ "GenSigSwitchedByIgnition" SG_ 2617127453 DEV_Klima_Tx_1D_Data 0;
BA_ "GenSigSwitchedByIgnition" SG_ 2617127454 DEV_Klima_Tx_1E_Data 0;
BA_ "GenSigSwitchedByIgnition" SG_ 2617127455 DEV_Klima_Tx_1F_Data 0;
BA_ "GenSigSwitchedByIgnition" SG_ 2617127456 DEV_Klima_Tx_20_Data 0;
BA_ "GenSigSwitchedByIgnition" SG_ 2617127457 DEV_Klima_Tx_21_Data 0;
BA_ "GenSigSwitchedByIgnition" SG_ 2617127458 DEV_Klima_Tx_22_Data 0;
BA_ "GenSigSwitchedByIgnition" SG_ 2617127459 DEV_Klima_Tx_23_Data 0;
BA_ "GenSigSwitchedByIgnition" SG_ 2617127460 DEV_Klima_Tx_24_Data 0;
BA_ "GenSigSwitchedByIgnition" SG_ 2617127461 DEV_Klima_Tx_25_Data 0;
BA_ "GenSigSwitchedByIgnition" SG_ 2617127462 DEV_Klima_Tx_26_Data 0;
BA_ "GenSigSwitchedByIgnition" SG_ 2617127463 DEV_Klima_Tx_27_Data 0;
BA_ "GenSigSwitchedByIgnition" SG_ 2617127468 DEV_Klima_Tx_2C_Data 0;
BA_ "GenSigSwitchedByIgnition" SG_ 2617127469 DEV_Klima_Tx_2D_Data 0;
BA_ "GenSigSwitchedByIgnition" SG_ 2617127470 DEV_Klima_Tx_2E_Data 0;
BA_ "GenSigSwitchedByIgnition" SG_ 2617127471 DEV_Klima_Tx_2F_Data 0;
BA_ "GenSigSwitchedByIgnition" SG_ 2617127472 DEV_Klima_Tx_30_Data 0;
BA_ "GenSigSwitchedByIgnition" SG_ 2617127473 DEV_Klima_Tx_31_Data 0;
BA_ "GenSigSwitchedByIgnition" SG_ 2617127474 DEV_Klima_Tx_32_Data 0;
BA_ "GenSigSwitchedByIgnition" SG_ 2617127475 DEV_Klima_Tx_33_Data 0;
BA_ "GenSigSwitchedByIgnition" SG_ 2617127476 DEV_Klima_Tx_34_Data 0;
BA_ "GenSigSwitchedByIgnition" SG_ 2617127477 DEV_Klima_Tx_35_Data 0;
BA_ "GenSigSwitchedByIgnition" SG_ 2617127478 DEV_Klima_Tx_36_Data 0;
BA_ "GenSigSwitchedByIgnition" SG_ 2617127479 DEV_Klima_Tx_37_Data 0;
BA_ "GenSigSwitchedByIgnition" SG_ 2617127480 DEV_Klima_Tx_38_Data 0;
BA_ "GenSigSwitchedByIgnition" SG_ 2617127481 DEV_Klima_Tx_39_Data 0;
BA_ "GenSigSwitchedByIgnition" SG_ 2617127482 DEV_Klima_Tx_3A_Data 0;
BA_ "GenSigSwitchedByIgnition" SG_ 2617127483 DEV_Klima_Tx_3B_Data 0;
BA_ "GenSigSwitchedByIgnition" SG_ 2617127484 DEV_Klima_Tx_3C_Data 0;
BA_ "GenSigSwitchedByIgnition" SG_ 2617127485 DEV_Klima_Tx_3D_Data 0;
BA_ "GenSigSwitchedByIgnition" SG_ 2617127486 DEV_Klima_Tx_3E_Data 0;
BA_ "GenSigSwitchedByIgnition" SG_ 2617127487 DEV_Klima_Tx_3F_Data 0;
BA_ "GenSigSwitchedByIgnition" SG_ 2617127488 DEV_Klima_Tx_40_Data 0;
BA_ "GenSigSwitchedByIgnition" SG_ 2617127489 DEV_Klima_Tx_41_Data 0;
BA_ "GenSigSwitchedByIgnition" SG_ 2617127490 DEV_Klima_Tx_42_Data 0;
BA_ "GenSigSwitchedByIgnition" SG_ 2617127491 DEV_Klima_Tx_43_Data 0;
BA_ "GenSigSwitchedByIgnition" SG_ 2617127492 DEV_Klima_Tx_44_Data 0;
BA_ "GenSigSwitchedByIgnition" SG_ 2617127493 DEV_Klima_Tx_45_Data 0;
BA_ "GenSigSwitchedByIgnition" SG_ 2617127494 DEV_Klima_Tx_46_Data 0;
BA_ "GenSigSwitchedByIgnition" SG_ 2617127495 DEV_Klima_Tx_47_Data 0;
BA_ "GenSigSwitchedByIgnition" SG_ 2617127496 DEV_Klima_Tx_48_Data 0;
BA_ "GenSigSwitchedByIgnition" SG_ 2617127497 DEV_Klima_Tx_49_Data 0;
BA_ "GenSigSwitchedByIgnition" SG_ 2617127498 DEV_Klima_Tx_4A_Data 0;
BA_ "GenSigSwitchedByIgnition" SG_ 2617127499 DEV_Klima_Tx_4B_Data 0;
BA_ "GenSigSwitchedByIgnition" SG_ 2617127500 DEV_Klima_Tx_4C_Data 0;
BA_ "GenSigSwitchedByIgnition" SG_ 2617127501 DEV_Klima_Tx_4D_Data 0;
BA_ "GenSigSwitchedByIgnition" SG_ 2617127502 DEV_Klima_Tx_4E_Data 0;
BA_ "GenSigSwitchedByIgnition" SG_ 2617127503 DEV_Klima_Tx_4F_Data 0;
BA_ "GenSigSwitchedByIgnition" SG_ 2617127466 DEV_Klima_VAL_Req_02_Data 0;
BA_ "GenSigSwitchedByIgnition" SG_ 2617127467 DEV_Klima_VAL_Resp_02_Data 0;
BA_ "GenSigSendType" SG_ 2549880529 DIA_CMC_01_Req_Data 3;
BA_ "GenSigFuncType" SG_ 2549880529 DIA_CMC_01_Req_Data 9;
BA_ "GenSigSwitchedByIgnition" SG_ 2549880529 DIA_CMC_01_Req_Data 0;
BA_ "GenSigSendType" SG_ 2550011601 DIA_CMC_01_Resp_Data 3;
BA_ "GenSigFuncType" SG_ 2550011601 DIA_CMC_01_Resp_Data 9;
BA_ "GenSigSwitchedByIgnition" SG_ 2550011601 DIA_CMC_01_Resp_Data 0;
BA_ "GenSigSendType" SG_ 2549880533 DIA_CMC_05_Req_Data 3;
BA_ "GenSigFuncType" SG_ 2549880533 DIA_CMC_05_Req_Data 9;
BA_ "GenSigSwitchedByIgnition" SG_ 2549880533 DIA_CMC_05_Req_Data 0;
BA_ "GenSigSendType" SG_ 2550011605 DIA_CMC_05_Resp_Data 3;
BA_ "GenSigFuncType" SG_ 2550011605 DIA_CMC_05_Resp_Data 9;
BA_ "GenSigSwitchedByIgnition" SG_ 2550011605 DIA_CMC_05_Resp_Data 0;
BA_ "GenSigSendType" SG_ 2549880537 DIA_CMC_09_Req_Data 3;
BA_ "GenSigFuncType" SG_ 2549880537 DIA_CMC_09_Req_Data 9;
BA_ "GenSigSwitchedByIgnition" SG_ 2549880537 DIA_CMC_09_Req_Data 0;
BA_ "GenSigSendType" SG_ 2550011609 DIA_CMC_09_Resp_Data 3;
BA_ "GenSigFuncType" SG_ 2550011609 DIA_CMC_09_Resp_Data 9;
BA_ "GenSigSwitchedByIgnition" SG_ 2550011609 DIA_CMC_09_Resp_Data 0;
BA_ "GenSigSendType" SG_ 2549880561 DIA_CMC_13_Req_Data 3;
BA_ "GenSigFuncType" SG_ 2549880561 DIA_CMC_13_Req_Data 9;
BA_ "GenSigSwitchedByIgnition" SG_ 2549880561 DIA_CMC_13_Req_Data 0;
BA_ "GenSigSendType" SG_ 2550011633 DIA_CMC_13_Resp_Data 3;
BA_ "GenSigFuncType" SG_ 2550011633 DIA_CMC_13_Resp_Data 9;
BA_ "GenSigSwitchedByIgnition" SG_ 2550011633 DIA_CMC_13_Resp_Data 0;
BA_ "GenSigSendType" SG_ 1714 DGN_Verlernzaehler 0;
BA_ "GenSigSwitchedByIgnition" SG_ 1714 DGN_Verlernzaehler 0;
BA_ "GenSigSendType" SG_ 1714 KBI_Kilometerstand 0;
BA_ "GenSigStartValue" SG_ 1714 KBI_Kilometerstand 1048574;
BA_ "GenSigSwitchedByIgnition" SG_ 1714 KBI_Kilometerstand 0;
BA_ "Fehlerwert" SG_ 1714 KBI_Kilometerstand 1048575;
BA_ "GenSigSendType" SG_ 1714 Kombi_02_alt 0;
BA_ "GenSigStartValue" SG_ 1714 Kombi_02_alt 1;
BA_ "GenSigFuncType" SG_ 1714 Kombi_02_alt 5;
BA_ "GenSigSwitchedByIgnition" SG_ 1714 Kombi_02_alt 0;
BA_ "GenSigSendType" SG_ 1714 UH_Jahr 0;
BA_ "GenSigSwitchedByIgnition" SG_ 1714 UH_Jahr 0;
BA_ "GenSigSendType" SG_ 1714 UH_Minute 0;
BA_ "GenSigSwitchedByIgnition" SG_ 1714 UH_Minute 0;
BA_ "GenSigSendType" SG_ 1714 UH_Monat 0;
BA_ "GenSigSwitchedByIgnition" SG_ 1714 UH_Monat 0;
BA_ "Fehlerwert" SG_ 1714 UH_Monat 15;
BA_ "GenSigSendType" SG_ 1714 UH_Sekunde 0;
BA_ "GenSigSwitchedByIgnition" SG_ 1714 UH_Sekunde 0;
BA_ "GenSigSendType" SG_ 1714 UH_Stunde 0;
BA_ "GenSigSwitchedByIgnition" SG_ 1714 UH_Stunde 0;
BA_ "GenSigSendType" SG_ 1714 UH_Tag 0;
BA_ "GenSigSwitchedByIgnition" SG_ 1714 UH_Tag 0;
BA_ "GenSigSendType" SG_ 1714 Uhrzeit_01_alt 0;
BA_ "GenSigStartValue" SG_ 1714 Uhrzeit_01_alt 1;
BA_ "GenSigFuncType" SG_ 1714 Uhrzeit_01_alt 5;
BA_ "GenSigSwitchedByIgnition" SG_ 1714 Uhrzeit_01_alt 0;
BA_ "GenSigSendType" SG_ 1714 Vehicle_Driving_Cycle 0;
BA_ "GenSigSwitchedByIgnition" SG_ 1714 Vehicle_Driving_Cycle 0;
BA_ "GenSigSendType" SG_ 851 DiETa_Car 0;
BA_ "GenSigSwitchedByIgnition" SG_ 851 DiETa_Car 0;
BA_ "Fehlerwert" SG_ 851 DiETa_Car 3;
BA_ "GenSigSendType" SG_ 851 DiETa_Defrost_Taste 0;
BA_ "GenSigSwitchedByIgnition" SG_ 851 DiETa_Defrost_Taste 0;
BA_ "Fehlerwert" SG_ 851 DiETa_Defrost_Taste 3;
BA_ "GenSigSendType" SG_ 851 DiETa_FAS_Stufe 0;
BA_ "GenSigSwitchedByIgnition" SG_ 851 DiETa_FAS_Stufe 0;
BA_ "Fehlerwert" SG_ 851 DiETa_FAS_Stufe 3;
BA_ "GenSigSendType" SG_ 851 DiETa_FSH_Taste 0;
BA_ "GenSigSwitchedByIgnition" SG_ 851 DiETa_FSH_Taste 0;
BA_ "Fehlerwert" SG_ 851 DiETa_FSH_Taste 3;
BA_ "GenSigSendType" SG_ 851 DiETa_HSH_Taste 0;
BA_ "GenSigSwitchedByIgnition" SG_ 851 DiETa_HSH_Taste 0;
BA_ "Fehlerwert" SG_ 851 DiETa_HSH_Taste 3;
BA_ "GenSigSendType" SG_ 851 DiETa_Klima 0;
BA_ "GenSigSwitchedByIgnition" SG_ 851 DiETa_Klima 0;
BA_ "Fehlerwert" SG_ 851 DiETa_Klima 3;
BA_ "GenSigSendType" SG_ 851 DiETa_Lock_Unlock_Taste 0;
BA_ "GenSigSwitchedByIgnition" SG_ 851 DiETa_Lock_Unlock_Taste 0;
BA_ "Fehlerwert" SG_ 851 DiETa_Lock_Unlock_Taste 7;
BA_ "GenSigSendType" SG_ 851 DiETa_Mode 0;
BA_ "GenSigSwitchedByIgnition" SG_ 851 DiETa_Mode 0;
BA_ "Fehlerwert" SG_ 851 DiETa_Mode 3;
BA_ "GenSigSendType" SG_ 851 DiETa_Mode2 0;
BA_ "GenSigSwitchedByIgnition" SG_ 851 DiETa_Mode2 0;
BA_ "Fehlerwert" SG_ 851 DiETa_Mode2 3;
BA_ "GenSigSendType" SG_ 851 DiETa_Mode_roh 0;
BA_ "GenSigSwitchedByIgnition" SG_ 851 DiETa_Mode_roh 0;
BA_ "GenSigSendType" SG_ 851 DiETa_PAO_OFF_Status 0;
BA_ "GenSigSwitchedByIgnition" SG_ 851 DiETa_PAO_OFF_Status 0;
BA_ "GenSigSendType" SG_ 851 DiETa_PAO_ON_Status 0;
BA_ "GenSigSwitchedByIgnition" SG_ 851 DiETa_PAO_ON_Status 0;
BA_ "GenSigSendType" SG_ 851 DiETa_Parken 0;
BA_ "GenSigSwitchedByIgnition" SG_ 851 DiETa_Parken 0;
BA_ "Fehlerwert" SG_ 851 DiETa_Parken 3;
BA_ "GenSigSendType" SG_ 851 DiETa_Reserve_Byte2_4 0;
BA_ "GenSigSwitchedByIgnition" SG_ 851 DiETa_Reserve_Byte2_4 0;
BA_ "GenSigSendType" SG_ 851 DiETa_Reserve_Byte6_6 0;
BA_ "GenSigSwitchedByIgnition" SG_ 851 DiETa_Reserve_Byte6_6 0;
BA_ "GenSigSendType" SG_ 851 DiETa_Reserve_Byte7_4 0;
BA_ "GenSigSwitchedByIgnition" SG_ 851 DiETa_Reserve_Byte7_4 0;
BA_ "GenSigSendType" SG_ 851 DiETa_Reserve_Byte8 0;
BA_ "GenSigSwitchedByIgnition" SG_ 851 DiETa_Reserve_Byte8 0;
BA_ "GenSigSendType" SG_ 851 DiETa_ResponseError 0;
BA_ "GenSigSwitchedByIgnition" SG_ 851 DiETa_ResponseError 0;
BA_ "Fehlerwert" SG_ 851 DiETa_ResponseError 1;
BA_ "GenSigSendType" SG_ 851 DiETa_Status 0;
BA_ "GenSigStartValue" SG_ 851 DiETa_Status 2;
BA_ "GenSigSwitchedByIgnition" SG_ 851 DiETa_Status 0;
BA_ "GenSigSendType" SG_ 851 DiETa_Touch_Event 0;
BA_ "GenSigSwitchedByIgnition" SG_ 851 DiETa_Touch_Event 0;
BA_ "Fehlerwert" SG_ 851 DiETa_Touch_Event 15;
BA_ "GenSigSendType" SG_ 851 DiETa_Warnblink_Taste 0;
BA_ "GenSigSwitchedByIgnition" SG_ 851 DiETa_Warnblink_Taste 0;
BA_ "Fehlerwert" SG_ 851 DiETa_Warnblink_Taste 3;
BA_ "GenSigSendType" SG_ 851 DiETas_01_BZ 0;
BA_ "GenSigFuncType" SG_ 851 DiETas_01_BZ 1;
BA_ "GenSigSwitchedByIgnition" SG_ 851 DiETas_01_BZ 0;
BA_ "GenSigSendType" SG_ 851 DiETas_01_CRC 0;
BA_ "GenSigFuncType" SG_ 851 DiETas_01_CRC 2;
BA_ "GenSigSwitchedByIgnition" SG_ 851 DiETas_01_CRC 0;
BA_ "GenSigSendType" SG_ 851 ESP_Off_Taster 0;
BA_ "GenSigStartValue" SG_ 851 ESP_Off_Taster 2;
BA_ "GenSigSwitchedByIgnition" SG_ 851 ESP_Off_Taster 0;
BA_ "Fehlerwert" SG_ 851 ESP_Off_Taster 3;
BA_ "GenSigSendType" SG_ 1520 BCM1_Stellgroesse_Kl_58s 3;
BA_ "GenSigStartValue" SG_ 1520 BCM1_Stellgroesse_Kl_58s 126;
BA_ "GenSigSwitchedByIgnition" SG_ 1520 BCM1_Stellgroesse_Kl_58s 0;
BA_ "Fehlerwert" SG_ 1520 BCM1_Stellgroesse_Kl_58s 127;
BA_ "GenSigSendType" SG_ 1520 DI_Display_Nachtdesign 3;
BA_ "GenSigSwitchedByIgnition" SG_ 1520 DI_Display_Nachtdesign 0;
BA_ "GenSigSendType" SG_ 1520 DI_Fotosensor 3;
BA_ "GenSigSwitchedByIgnition" SG_ 1520 DI_Fotosensor 0;
BA_ "GenSigSendType" SG_ 1520 DI_KL_58xd 3;
BA_ "GenSigStartValue" SG_ 1520 DI_KL_58xd 254;
BA_ "GenSigSwitchedByIgnition" SG_ 1520 DI_KL_58xd 0;
BA_ "Fehlerwert" SG_ 1520 DI_KL_58xd 255;
BA_ "GenSigSendType" SG_ 1520 DI_KL_58xs 3;
BA_ "GenSigStartValue" SG_ 1520 DI_KL_58xs 126;
BA_ "GenSigSwitchedByIgnition" SG_ 1520 DI_KL_58xs 0;
BA_ "Fehlerwert" SG_ 1520 DI_KL_58xs 127;
BA_ "GenSigSendType" SG_ 1520 DI_KL_58xt 3;
BA_ "GenSigStartValue" SG_ 1520 DI_KL_58xt 126;
BA_ "GenSigSwitchedByIgnition" SG_ 1520 DI_KL_58xt 0;
BA_ "Fehlerwert" SG_ 1520 DI_KL_58xt 127;
BA_ "GenSigSendType" SG_ 1603 KBI_Einheit_Datum 3;
BA_ "GenSigSwitchedByIgnition" SG_ 1603 KBI_Einheit_Datum 0;
BA_ "GenSigSendType" SG_ 1603 KBI_Einheit_Druck 3;
BA_ "GenSigSwitchedByIgnition" SG_ 1603 KBI_Einheit_Druck 0;
BA_ "GenSigSendType" SG_ 1603 KBI_Einheit_Masse 3;
BA_ "GenSigSwitchedByIgnition" SG_ 1603 KBI_Einheit_Masse 0;
BA_ "GenSigSendType" SG_ 1603 KBI_Einheit_Sprache 3;
BA_ "GenSigSwitchedByIgnition" SG_ 1603 KBI_Einheit_Sprache 0;
BA_ "GenSigSendType" SG_ 1603 KBI_Einheit_Streckenanz 3;
BA_ "GenSigSwitchedByIgnition" SG_ 1603 KBI_Einheit_Streckenanz 0;
BA_ "GenSigSendType" SG_ 1603 KBI_Einheit_Tacho 3;
BA_ "GenSigSwitchedByIgnition" SG_ 1603 KBI_Einheit_Tacho 0;
BA_ "GenSigSendType" SG_ 1603 KBI_Einheit_Temp 3;
BA_ "GenSigSwitchedByIgnition" SG_ 1603 KBI_Einheit_Temp 0;
BA_ "GenSigSendType" SG_ 1603 KBI_Einheit_Uhrzeit 3;
BA_ "GenSigSwitchedByIgnition" SG_ 1603 KBI_Einheit_Uhrzeit 0;
BA_ "GenSigSendType" SG_ 1603 KBI_Einheit_Verbrauch 3;
BA_ "GenSigSwitchedByIgnition" SG_ 1603 KBI_Einheit_Verbrauch 0;
BA_ "GenSigSendType" SG_ 1603 KBI_Einheit_Verbrauch_elektr 3;
BA_ "GenSigSwitchedByIgnition" SG_ 1603 KBI_Einheit_Verbrauch_elektr 0;
BA_ "GenSigSendType" SG_ 1603 KBI_Einheit_Verbrauch_Gas 3;
BA_ "GenSigSwitchedByIgnition" SG_ 1603 KBI_Einheit_Verbrauch_Gas 0;
BA_ "GenSigSendType" SG_ 1603 KBI_Einheit_Volumen 3;
BA_ "GenSigSwitchedByIgnition" SG_ 1603 KBI_Einheit_Volumen 0;
BA_ "GenSigSendType" SG_ 1603 KBI_MFA_v_Einheit_02 3;
BA_ "GenSigSwitchedByIgnition" SG_ 1603 KBI_MFA_v_Einheit_02 0;
BA_ "GenSigSendType" SG_ 2527679743 ELF_AbfahrtstimerAktiv 3;
BA_ "GenSigSwitchedByIgnition" SG_ 2527679743 ELF_AbfahrtstimerAktiv 0;
BA_ "GenSigSendType" SG_ 2527679743 ELF_AbfahrtstimerJahr 3;
BA_ "GenSigStartValue" SG_ 2527679743 ELF_AbfahrtstimerJahr 4095;
BA_ "GenSigSwitchedByIgnition" SG_ 2527679743 ELF_AbfahrtstimerJahr 0;
BA_ "GenSigSendType" SG_ 2527679743 ELF_AbfahrtstimerMinute 3;
BA_ "GenSigStartValue" SG_ 2527679743 ELF_AbfahrtstimerMinute 63;
BA_ "GenSigSwitchedByIgnition" SG_ 2527679743 ELF_AbfahrtstimerMinute 0;
BA_ "GenSigSendType" SG_ 2527679743 ELF_AbfahrtstimerMonat 3;
BA_ "GenSigStartValue" SG_ 2527679743 ELF_AbfahrtstimerMonat 15;
BA_ "GenSigSwitchedByIgnition" SG_ 2527679743 ELF_AbfahrtstimerMonat 0;
BA_ "GenSigSendType" SG_ 2527679743 ELF_AbfahrtstimerStunde 3;
BA_ "GenSigStartValue" SG_ 2527679743 ELF_AbfahrtstimerStunde 31;
BA_ "GenSigSwitchedByIgnition" SG_ 2527679743 ELF_AbfahrtstimerStunde 0;
BA_ "GenSigSendType" SG_ 2527679743 ELF_AbfahrtstimerTag 3;
BA_ "GenSigSwitchedByIgnition" SG_ 2527679743 ELF_AbfahrtstimerTag 0;
BA_ "GenSigSendType" SG_ 2527679743 ELF_KundenwunschKlimatisierung 3;
BA_ "GenSigStartValue" SG_ 2527679743 ELF_KundenwunschKlimatisierung 2;
BA_ "GenSigSwitchedByIgnition" SG_ 2527679743 ELF_KundenwunschKlimatisierung 0;
BA_ "GenSigSendType" SG_ 782 ELF_AnforderungWlanVerbindung 0;
BA_ "GenSigSwitchedByIgnition" SG_ 782 ELF_AnforderungWlanVerbindung 0;
BA_ "GenSigSendType" SG_ 782 ELF_EigenstromGefordert 0;
BA_ "GenSigSwitchedByIgnition" SG_ 782 ELF_EigenstromGefordert 0;
BA_ "GenSigSendType" SG_ 782 ELF_EnergiebedarfMaxSoc 0;
BA_ "GenSigSwitchedByIgnition" SG_ 782 ELF_EnergiebedarfMaxSoc 0;
BA_ "GenSigSendType" SG_ 782 ELF_EnergiebedarfMinSoc 0;
BA_ "GenSigSwitchedByIgnition" SG_ 782 ELF_EnergiebedarfMinSoc 0;
BA_ "GenSigSendType" SG_ 782 ELF_EnergiebedarfZielSoc 0;
BA_ "GenSigSwitchedByIgnition" SG_ 782 ELF_EnergiebedarfZielSoc 0;
BA_ "GenSigSendType" SG_ 782 ELF_ErwLadenAnforderung 0;
BA_ "GenSigSwitchedByIgnition" SG_ 782 ELF_ErwLadenAnforderung 0;
BA_ "GenSigSendType" SG_ 782 ELF_EvNeuverhandlung 0;
BA_ "GenSigSwitchedByIgnition" SG_ 782 ELF_EvNeuverhandlung 0;
BA_ "GenSigSendType" SG_ 782 ELF_LadeleistungMaxKons 0;
BA_ "GenSigSwitchedByIgnition" SG_ 782 ELF_LadeleistungMaxKons 0;
BA_ "GenSigSendType" SG_ 782 ELF_Ladeplandauer 0;
BA_ "GenSigSendType" SG_ 782 ELF_Ladestrategie 0;
BA_ "GenSigStartValue" SG_ 782 ELF_Ladestrategie 15;
BA_ "GenSigSendType" SG_ 782 ELF_PLTabDatenquelle 0;
BA_ "GenSigSendType" SG_ 782 ELF_PLTabellenGefordert 0;
BA_ "GenSigSwitchedByIgnition" SG_ 782 ELF_PLTabellenGefordert 0;
BA_ "GenSigSendType" SG_ 782 ELF_StatusAbfragePLTab 0;
BA_ "Fehlerwert" SG_ 782 ELF_StatusAbfragePLTab 3;
BA_ "GenSigSendType" SG_ 782 ELF_StatusLadeplanerstellung 0;
BA_ "GenSigSendType" SG_ 782 ELF_StatusLadestrategie 0;
BA_ "Fehlerwert" SG_ 782 ELF_StatusLadestrategie 15;
BA_ "GenSigSendType" SG_ 192 EM1_01_BZ 0;
BA_ "GenSigFuncType" SG_ 192 EM1_01_BZ 1;
BA_ "GenSigSwitchedByIgnition" SG_ 192 EM1_01_BZ 0;
BA_ "GenSigSendType" SG_ 192 EM1_01_CRC 0;
BA_ "GenSigFuncType" SG_ 192 EM1_01_CRC 2;
BA_ "GenSigSwitchedByIgnition" SG_ 192 EM1_01_CRC 0;
BA_ "GenSigSendType" SG_ 192 EM1_AR_aktiv 0;
BA_ "GenSigSwitchedByIgnition" SG_ 192 EM1_AR_aktiv 0;
BA_ "GenSigSendType" SG_ 192 EM1_ErwGrenzen_aktiv 0;
BA_ "GenSigSwitchedByIgnition" SG_ 192 EM1_ErwGrenzen_aktiv 0;
BA_ "GenSigSendType" SG_ 192 EM1_Fehler_ElAntriebAbschaltung 0;
BA_ "GenSigSwitchedByIgnition" SG_ 192 EM1_Fehler_ElAntriebAbschaltung 0;
BA_ "GenSigSendType" SG_ 192 EM1_Fehler_Notabschaltung 0;
BA_ "GenSigSwitchedByIgnition" SG_ 192 EM1_Fehler_Notabschaltung 0;
BA_ "Fehlerwert" SG_ 192 EM1_Fehler_Notabschaltung 1;
BA_ "GenSigSendType" SG_ 192 EM1_IstDrehzahl 0;
BA_ "GenSigStartValue" SG_ 192 EM1_IstDrehzahl 32766;
BA_ "GenSigSwitchedByIgnition" SG_ 192 EM1_IstDrehzahl 0;
BA_ "Fehlerwert" SG_ 192 EM1_IstDrehzahl 32767;
BA_ "GenSigSendType" SG_ 192 EM1_Istmodus 0;
BA_ "GenSigStartValue" SG_ 192 EM1_Istmodus 15;
BA_ "GenSigSwitchedByIgnition" SG_ 192 EM1_Istmodus 0;
BA_ "GenSigSendType" SG_ 192 EM1_IstMoment 0;
BA_ "GenSigStartValue" SG_ 192 EM1_IstMoment 4094;
BA_ "GenSigSwitchedByIgnition" SG_ 192 EM1_IstMoment 0;
BA_ "Fehlerwert" SG_ 192 EM1_IstMoment 4095;
BA_ "GenSigSendType" SG_ 192 EM1_IstSpannung 0;
BA_ "GenSigStartValue" SG_ 192 EM1_IstSpannung 4094;
BA_ "GenSigSwitchedByIgnition" SG_ 192 EM1_IstSpannung 0;
BA_ "Fehlerwert" SG_ 192 EM1_IstSpannung 4095;
BA_ "GenSigSendType" SG_ 192 EM1_Max_Moment 0;
BA_ "GenSigStartValue" SG_ 192 EM1_Max_Moment 2046;
BA_ "GenSigSwitchedByIgnition" SG_ 192 EM1_Max_Moment 0;
BA_ "Fehlerwert" SG_ 192 EM1_Max_Moment 2047;
BA_ "GenSigSendType" SG_ 192 EM1_Max_Moment_Gesamt 0;
BA_ "GenSigStartValue" SG_ 192 EM1_Max_Moment_Gesamt 2046;
BA_ "GenSigSwitchedByIgnition" SG_ 192 EM1_Max_Moment_Gesamt 0;
BA_ "Fehlerwert" SG_ 192 EM1_Max_Moment_Gesamt 2047;
BA_ "GenSigSendType" SG_ 192 EM1_Max_Moment_Lim 0;
BA_ "GenSigStartValue" SG_ 192 EM1_Max_Moment_Lim 2046;
BA_ "GenSigSwitchedByIgnition" SG_ 192 EM1_Max_Moment_Lim 0;
BA_ "Fehlerwert" SG_ 192 EM1_Max_Moment_Lim 2047;
BA_ "GenSigSendType" SG_ 192 EM1_Min_Moment 0;
BA_ "GenSigStartValue" SG_ 192 EM1_Min_Moment 2046;
BA_ "GenSigSwitchedByIgnition" SG_ 192 EM1_Min_Moment 0;
BA_ "Fehlerwert" SG_ 192 EM1_Min_Moment 2047;
BA_ "GenSigSendType" SG_ 192 EM1_Min_Moment_Gesamt 0;
BA_ "GenSigStartValue" SG_ 192 EM1_Min_Moment_Gesamt 2046;
BA_ "GenSigSwitchedByIgnition" SG_ 192 EM1_Min_Moment_Gesamt 0;
BA_ "Fehlerwert" SG_ 192 EM1_Min_Moment_Gesamt 2047;
BA_ "GenSigSendType" SG_ 192 EM1_Min_Moment_Lim 0;
BA_ "GenSigStartValue" SG_ 192 EM1_Min_Moment_Lim 2046;
BA_ "GenSigSwitchedByIgnition" SG_ 192 EM1_Min_Moment_Lim 0;
BA_ "Fehlerwert" SG_ 192 EM1_Min_Moment_Lim 2047;
BA_ "GenSigSendType" SG_ 192 EM1_Mom_DrzEingriff 0;
BA_ "GenSigStartValue" SG_ 192 EM1_Mom_DrzEingriff 2046;
BA_ "GenSigSwitchedByIgnition" SG_ 192 EM1_Mom_DrzEingriff 0;
BA_ "Fehlerwert" SG_ 192 EM1_Mom_DrzEingriff 2047;
BA_ "GenSigSendType" SG_ 192 EM1_Moment_AR_Eingriff 0;
BA_ "GenSigStartValue" SG_ 192 EM1_Moment_AR_Eingriff 4094;
BA_ "GenSigSwitchedByIgnition" SG_ 192 EM1_Moment_AR_Eingriff 0;
BA_ "Fehlerwert" SG_ 192 EM1_Moment_AR_Eingriff 4095;
BA_ "GenSigSendType" SG_ 192 EM1_Raddrehzahl_links 0;
BA_ "GenSigStartValue" SG_ 192 EM1_Raddrehzahl_links 8190;
BA_ "GenSigSwitchedByIgnition" SG_ 192 EM1_Raddrehzahl_links 0;
BA_ "Fehlerwert" SG_ 192 EM1_Raddrehzahl_links 8191;
BA_ "GenSigSendType" SG_ 192 EM1_Raddrehzahl_rechts 0;
BA_ "GenSigStartValue" SG_ 192 EM1_Raddrehzahl_rechts 8190;
BA_ "GenSigSwitchedByIgnition" SG_ 192 EM1_Raddrehzahl_rechts 0;
BA_ "Fehlerwert" SG_ 192 EM1_Raddrehzahl_rechts 8191;
BA_ "GenSigSendType" SG_ 192 EM1_Status_DrzEingriff 0;
BA_ "GenSigSwitchedByIgnition" SG_ 192 EM1_Status_DrzEingriff 0;
BA_ "Fehlerwert" SG_ 192 EM1_Status_DrzEingriff 3;
BA_ "GenSigSendType" SG_ 192 EM1_Strom_HV 0;
BA_ "GenSigStartValue" SG_ 192 EM1_Strom_HV 4094;
BA_ "GenSigSwitchedByIgnition" SG_ 192 EM1_Strom_HV 0;
BA_ "Fehlerwert" SG_ 192 EM1_Strom_HV 4095;
BA_REL_ "GenSigTimeoutTime" BU_SG_REL_ BMS_NV_12V SG_ 1714 KBI_Kilometerstand 5000;
BA_REL_ "GenSigTimeoutTime" BU_SG_REL_ BMS_NV_12V SG_ 1714 UH_Jahr 5000;
BA_REL_ "GenSigTimeoutTime" BU_SG_REL_ BMS_NV_12V SG_ 1714 UH_Monat 5000;
BA_REL_ "GenSigTimeoutTime" BU_SG_REL_ BMS_NV_12V SG_ 1714 UH_Tag 5000;
BA_REL_ "GenSigTimeoutTime" BU_SG_REL_ BMS_NV_12V SG_ 1714 UH_Stunde 5000;
BA_REL_ "GenSigTimeoutTime" BU_SG_REL_ BMS_NV_12V SG_ 1714 UH_Minute 5000;
BA_REL_ "GenSigTimeoutTime" BU_SG_REL_ BMS_NV_12V SG_ 1714 UH_Sekunde 5000;
BA_REL_ "GenSigTimeoutTime" BU_SG_REL_ Gateway_Max SG_ 397 BMS_MV_01_CRC 500;
BA_REL_ "GenSigTimeoutTime" BU_SG_REL_ Gateway_Max SG_ 397 BMS_MV_01_BZ 500;
BA_REL_ "GenSigTimeoutTime" BU_SG_REL_ Gateway_Max SG_ 397 BMS_MV_IstStrom 500;
BA_REL_ "GenSigTimeoutTime" BU_SG_REL_ Gateway_Max SG_ 397 BMS_MV_IstSpannung 500;
BA_REL_ "GenSigTimeoutTime" BU_SG_REL_ Gateway_Max SG_ 397 BMS_MV_IstSpannung_Zwkr 500;
BA_REL_ "GenSigTimeoutTime" BU_SG_REL_ Gateway_Max SG_ 397 BMS_MV_SOC_HiRes 500;
BA_REL_ "GenSigTimeoutTime" BU_SG_REL_ Gateway_Max SG_ 2589283412 BMS_MV_Speichertechnologie 5000;
BA_REL_ "GenSigTimeoutTime" BU_SG_REL_ Gateway_Max SG_ 2589283608 BMS_MV_Energieinhalt 5000;
BA_REL_ "GenSigTimeoutTime" BU_SG_REL_ Gateway_Max SG_ 2589283608 BMS_MV_MaxEnergieinhalt 5000;
BA_REL_ "GenSigTimeoutTime" BU_SG_REL_ Gateway_Max SG_ 2589283606 BMS_MV_SOC_Kaltstart 5000;
BA_REL_ "GenSigTimeoutTime" BU_SG_REL_ Gateway_Max SG_ 2589283606 BMS_MV_max_Grenz_SOC 5000;
BA_REL_ "GenSigTimeoutTime" BU_SG_REL_ Gateway_Max SG_ 1021 BMS_MV_SOHC_DiagStatus 1000;
BA_REL_ "GenSigTimeoutTime" BU_SG_REL_ Gateway_Max SG_ 2463978716 BMS_MV_12_CRC 1000;
BA_REL_ "GenSigTimeoutTime" BU_SG_REL_ Gateway_Max SG_ 2463978716 BMS_MV_12_BZ 1000;
BA_REL_ "GenSigTimeoutTime" BU_SG_REL_ Gateway_Max SG_ 2463978716 BMS_MV_IstModus 1000;
BA_REL_ "GenSigTimeoutTime" BU_SG_REL_ Gateway_Max SG_ 2463978716 BMS_MV_Leistungsreduzierung 1000;
BA_REL_ "GenSigTimeoutTime" BU_SG_REL_ Gateway_Max SG_ 2463978716 BMS_MV_Fehler_Leistungsred 1000;
BA_REL_ "GenSigTimeoutTime" BU_SG_REL_ Gateway_Max SG_ 2463978716 BMS_MV_Fehler_BattAbschaltung 1000;
BA_REL_ "GenSigTimeoutTime" BU_SG_REL_ Gateway_Max SG_ 2463978716 BMS_MV_Fehler_BattAbschaltungAnf 1000;
BA_REL_ "GenSigTimeoutTime" BU_SG_REL_ Gateway_Max SG_ 2463978716 BMS_MV_Fehler_Kaltstartleistung 1000;
BA_REL_ "GenSigTimeoutTime" BU_SG_REL_ Gateway_Max SG_ 2463978716 BMS_MV_Fehler_Notfallreserve 1000;
BA_REL_ "GenSigTimeoutTime" BU_SG_REL_ Gateway_Max SG_ 2463978716 BMS_MV_Fehler_Relay_offen 1000;
BA_REL_ "GenSigTimeoutTime" BU_SG_REL_ Gateway_Max SG_ 2463978716 BMS_MV_Fehler_Relay_verschweisst 1000;
BA_REL_ "GenSigTimeoutTime" BU_SG_REL_ Gateway_Max SG_ 2463978716 BMS_MV_Peak_EntladeLeistung 1000;
BA_REL_ "GenSigTimeoutTime" BU_SG_REL_ Gateway_Max SG_ 2463978716 BMS_MV_Peak_LadeLeistung 1000;
BA_REL_ "GenSigTimeoutTime" BU_SG_REL_ Gateway_Max SG_ 2463978717 BMS_MV_Strat_EntladeSpannung 1000;
BA_REL_ "GenSigTimeoutTime" BU_SG_REL_ Gateway_Max SG_ 2463978717 BMS_MV_Max_EntladeLeistung 1000;
BA_REL_ "GenSigTimeoutTime" BU_SG_REL_ Gateway_Max SG_ 2463978717 BMS_MV_Max_LadeLeistung 1000;
BA_REL_ "GenSigTimeoutTime" BU_SG_REL_ Gateway_Max SG_ 2463978718 BMS_MV_14_CRC 1000;
BA_REL_ "GenSigTimeoutTime" BU_SG_REL_ Gateway_Max SG_ 2463978718 BMS_MV_14_BZ 1000;
BA_REL_ "GenSigTimeoutTime" BU_SG_REL_ Gateway_Max SG_ 2463978718 BMS_MV_Strat_LadeSpannung 1000;
BA_REL_ "GenSigTimeoutTime" BU_SG_REL_ Gateway_Max SG_ 2463978718 BMS_MV_Max_LadeStrom_Lim 1000;
BA_REL_ "GenSigTimeoutTime" BU_SG_REL_ Gateway_Max SG_ 2463978718 BMS_MV_Min_EntladeSpannung_Lim 1000;
BA_REL_ "GenSigTimeoutTime" BU_SG_REL_ Gateway_Max SG_ 2463978718 BMS_MV_Max_LadeSpannung_Lim 1000;
BA_REL_ "GenSigTimeoutTime" BU_SG_REL_ Gateway_Max SG_ 2589283523 BMS_MV_Kundenwarnung 5000;
BA_REL_ "GenSigTimeoutTime" BU_SG_REL_ Gateway_Max SG_ 2589283523 BMS_MV_Dauer_RMS_Strom 5000;
BA_REL_ "GenSigTimeoutTime" BU_SG_REL_ Gateway_Max SG_ 2589283524 BMS_MV_TRD_Voltage 5000;
BA_REL_ "GenSigTimeoutTime" BU_SG_REL_ Gateway_Max SG_ 2589283524 BMS_MV_TRD_Sensfail 5000;
BA_REL_ "GenSigTimeoutTime" BU_SG_REL_ Gateway_Max SG_ 2589283524 BMS_MV_TRD_Temp 5000;
BA_REL_ "GenSigTimeoutTime" BU_SG_REL_ Gateway_Max SG_ 2589283524 BMS_MV_EntladeEnergie 5000;
BA_REL_ "GenSigTimeoutTime" BU_SG_REL_ Gateway_Max SG_ 2589283524 BMS_MV_LadeEnergie 5000;
BA_REL_ "GenSigTimeoutTime" BU_SG_REL_ Gateway_Max SG_ 2589283524 BMS_MV_Max_RMS_Strom 5000;
BA_REL_ "GenSigTimeoutTime" BU_SG_REL_ Gateway_Max SG_ 686 DCDC_01_CRC 500;
BA_REL_ "GenSigTimeoutTime" BU_SG_REL_ Gateway_Max SG_ 686 DCDC_01_BZ 500;
BA_REL_ "GenSigTimeoutTime" BU_SG_REL_ Gateway_Max SG_ 686 DC_IstSpannung_HV 500;
BA_REL_ "GenSigTimeoutTime" BU_SG_REL_ Gateway_Max SG_ 686 DC_IstStrom_NV 500;
BA_REL_ "GenSigTimeoutTime" BU_SG_REL_ Gateway_Max SG_ 686 DC_IstSpannung_NV 500;
BA_REL_ "GenSigTimeoutTime" BU_SG_REL_ Gateway_Max SG_ 1012 DCDC_02_CRC 500;
BA_REL_ "GenSigTimeoutTime" BU_SG_REL_ Gateway_Max SG_ 1012 DCDC_02_BZ 500;
BA_REL_ "GenSigTimeoutTime" BU_SG_REL_ Gateway_Max SG_ 1012 DC_ReserveStrom_NV 500;
BA_REL_ "GenSigTimeoutTime" BU_SG_REL_ Gateway_Max SG_ 1012 DC_Verbrauch_Ueberlauf 500;
BA_REL_ "GenSigTimeoutTime" BU_SG_REL_ Gateway_Max SG_ 1012 DC_Verbrauch 500;
BA_REL_ "GenSigTimeoutTime" BU_SG_REL_ Gateway_Max SG_ 1012 DC_HYB_Auslastungsgrad 500;
BA_REL_ "GenSigTimeoutTime" BU_SG_REL_ Gateway_Max SG_ 1485 DCDC_03_CRC 5000;
BA_REL_ "GenSigTimeoutTime" BU_SG_REL_ Gateway_Max SG_ 1485 DCDC_03_BZ 5000;
BA_REL_ "GenSigTimeoutTime" BU_SG_REL_ Gateway_Max SG_ 1485 DC_Temperatur_Alarm 5000;
BA_REL_ "GenSigTimeoutTime" BU_SG_REL_ Gateway_Max SG_ 1485 DC_Peakstrom_verfuegbar 5000;
BA_REL_ "GenSigTimeoutTime" BU_SG_REL_ Gateway_Max SG_ 247 DC_Fehler_extern 500;
BA_REL_ "GenSigTimeoutTime" BU_SG_REL_ Gateway_Max SG_ 247 DC_Fehler_intern 500;
BA_REL_ "GenSigTimeoutTime" BU_SG_REL_ Gateway_Max SG_ 247 DC_IstModus_02 500;
BA_REL_ "GenSigTimeoutTime" BU_SG_REL_ Gateway_Max SG_ 247 DC_IstStrom_HV 500;
BA_REL_ "GenSigTimeoutTime" BU_SG_REL_ Gateway_Max SG_ 247 DC_IstLeistung_HV 500;
BA_REL_ "GenSigTimeoutTime" BU_SG_REL_ Gateway_Max SG_ 1484 DCDC_MV_03_CRC 5000;
BA_REL_ "GenSigTimeoutTime" BU_SG_REL_ Gateway_Max SG_ 1484 DCDC_MV_03_BZ 5000;
BA_REL_ "GenSigTimeoutTime" BU_SG_REL_ Gateway_Max SG_ 1484 DCDC_MV_Peakstrom_verfuegbar 5000;
BA_REL_ "GenSigTimeoutTime" BU_SG_REL_ Gateway_Max SG_ 1484 DC_MV_Fehlerstatus 5000;
BA_REL_ "GenSigTimeoutTime" BU_SG_REL_ Gateway_Max SG_ 1484 DC_MV_IstModus_02 5000;
BA_REL_ "GenSigTimeoutTime" BU_SG_REL_ Klima SG_ 902 CHA_Fahrer_Umschaltung 5000;
BA_REL_ "GenSigTimeoutTime" BU_SG_REL_ Klima SG_ 902 CHA_Ziel_FahrPr_KL 5000;
BA_REL_ "GenSigTimeoutTime" BU_SG_REL_ Klima SG_ 1714 DGN_Verlernzaehler 5000;
BA_REL_ "GenSigTimeoutTime" BU_SG_REL_ Klima SG_ 1714 KBI_Kilometerstand 5000;
BA_REL_ "GenSigTimeoutTime" BU_SG_REL_ Klima SG_ 1714 UH_Jahr 5000;
BA_REL_ "GenSigTimeoutTime" BU_SG_REL_ Klima SG_ 1714 UH_Monat 5000;
BA_REL_ "GenSigTimeoutTime" BU_SG_REL_ Klima SG_ 1714 UH_Tag 5000;
BA_REL_ "GenSigTimeoutTime" BU_SG_REL_ Klima SG_ 1714 UH_Stunde 5000;
BA_REL_ "GenSigTimeoutTime" BU_SG_REL_ Klima SG_ 1714 UH_Minute 5000;
BA_REL_ "GenSigTimeoutTime" BU_SG_REL_ Klima SG_ 1714 UH_Sekunde 5000;
BA_REL_ "GenSigTimeoutTime" BU_SG_REL_ Klima SG_ 1714 Vehicle_Driving_Cycle 5000;
BA_REL_ "GenSigTimeoutTime" BU_SG_REL_ Klima SG_ 1714 Kombi_02_alt 5000;
BA_REL_ "GenSigTimeoutTime" BU_SG_REL_ Klima SG_ 1714 Uhrzeit_01_alt 5000;
BA_REL_ "GenSigTimeoutTime" BU_SG_REL_ Klima SG_ 851 DiETa_Klima 800;
BA_REL_ "GenSigTimeoutTime" BU_SG_REL_ Klima SG_ 851 DiETa_FSH_Taste 800;
BA_REL_ "GenSigTimeoutTime" BU_SG_REL_ Klima SG_ 851 DiETa_HSH_Taste 800;
BA_REL_ "GenSigTimeoutTime" BU_SG_REL_ Klima SG_ 851 DiETa_Defrost_Taste 800;
BA_REL_ "GenSigTimeoutTime" BU_SG_REL_ Klima SG_ 1520 DI_KL_58xd 2000;
BA_REL_ "GenSigTimeoutTime" BU_SG_REL_ Klima SG_ 1520 DI_KL_58xs 2000;
BA_REL_ "GenSigTimeoutTime" BU_SG_REL_ Klima SG_ 1603 KBI_Einheit_Temp 5000;
BA_REL_ "GenSigTimeoutTime" BU_SG_REL_ Klima SG_ 1603 KBI_Einheit_Uhrzeit 5000;
VAL_ 397 BMS_MV_IstStrom 4094 "Init" 4095 "Fehler" ;
VAL_ 397 BMS_MV_IstSpannung 254 "Init" 255 "Fehler" ;
VAL_ 397 BMS_MV_IstSpannung_Zwkr 254 "Init" 255 "Fehler" ;
VAL_ 397 BMS_MV_SOC_HiRes 2046 "Init" 2047 "Fehler" ;
VAL_ 419 BMS_MV_MaxDyn_EntladeStrom 2046 "Init" 2047 "Fehler" ;
VAL_ 419 BMS_MV_MaxDyn_LadeStrom 2046 "Init" 2047 "Fehler" ;
VAL_ 419 BMS_MV_Min_EntladeSpannung 254 "Init" 255 "Fehler" ;
VAL_ 419 BMS_MV_MinDynEntladeSpannung 254 "Init" ;
VAL_ 419 BMS_MV_MinDyn_LadeSpannung 254 "Init" ;
VAL_ 2589283412 BMS_MV_Temperierung_Anf 0 "hoher_Kuehlbedarf" 1 "mittlerer_Kuehlbedarf" 2 "niedriger_Kuehlbedarf" 3 "kein_Temperierungsbedarf_Init" 4 "niedriger_Heizbedarf" 5 "mittlerer_Heizbedarf" 6 "hoher_Heizbedarf" 7 "Umwaelzungsbedarf" ;
VAL_ 2589283412 BMS_MV_Speichertechnologie 0 "Technologie_0" 1 "Technologie_1" 2 "Technologie_2" 3 "Technologie_3" 4 "Technologie_4" 5 "Technologie_5" 6 "Technologie_6" 7 "Technologie_unbekannt" ;
VAL_ 2589283412 BMS_MV_Soll_PWM_Pumpe 15 "Init" ;
VAL_ 2589283412 BMS_MV_Temperatur 254 "Init" 255 "Fehler" ;
VAL_ 2589283412 BMS_MV_IstVorlaufTemperatur 254 "Init" 255 "Fehler" ;
VAL_ 2589283412 BMS_MV_SollVolumenstrom 62 "Init" 63 "Fehler" ;
VAL_ 2589283412 BMS_MV_SollVorlauftemperatur 254 "Init" 255 "Fehler" ;
VAL_ 2589283412 BMS_MV_IstRuecklaufTemperatur 254 "Init" 255 "Fehler" ;
VAL_ 2589283608 BMS_MV_Energieinhalt 2046 "Init" 2047 "Fehler" ;
VAL_ 2589283608 BMS_MV_MaxEnergieinhalt 2046 "Init" 2047 "Fehler" ;
VAL_ 2589283606 BMS_MV_SOC_Kaltstart 2046 "Init" 2047 "Fehler" ;
VAL_ 2589283606 BMS_MV_max_Grenz_SOC 31 "Init" ;
VAL_ 1021 BMS_MV_SOHC_DiagStatus 0 "kein_Diagnosebedarf" 1 "Diagnosebedarf_niedrig" 2 "Diagnosebedarf_mittel" 3 "Diagnosebedarf_Zwang" 4 "Diagnosebedarf_Werkstatt" 5 "Diagnose_laeuft" 6 "Diagnoseabbruch" 7 "Diagnosefehler" ;
VAL_ 1021 BMS_MV_Pred_Entladeperformance 126 "Init" 127 "Fehler" ;
VAL_ 1021 BMS_MV_Pred_Ladeperformance 126 "Init" 127 "Fehler" ;
VAL_ 2463978716 BMS_MV_IstModus 0 "stStdBy" 1 "stMV" 5 "Error_Batt" 7 "stInit" ;
VAL_ 2463978716 BMS_MV_Leistungsreduzierung 0 "inaktiv" 1 "aktiv" ;
VAL_ 2463978716 BMS_MV_Fehler_Leistungsred 0 "Init" 1 "Leistungseinschraenkung" ;
VAL_ 2463978716 BMS_MV_Fehler_BattAbschaltung 0 "Init" 1 "Err_ShutOff" ;
VAL_ 2463978716 BMS_MV_Fehler_BattAbschaltungAnf 0 "Init" 1 "Err_ShutOffRequest" ;
VAL_ 2463978716 BMS_MV_Fehler_Kaltstartleistung 0 "Init" 1 "Kaltstartleistung_zu_gering" ;
VAL_ 2463978716 BMS_MV_Fehler_Notfallreserve 0 "Energiereserve_verfuegbar" 1 "reserved" 2 "Energiereserve_nicht_verfuegbar" 3 "Init" ;
VAL_ 2463978716 BMS_MV_Fehler_Relay_offen 0 "Init" 1 "Err_ContactorOpen" ;
VAL_ 2463978716 BMS_MV_Fehler_Relay_verschweisst 0 "Init" 1 "Err_ContactorWelding" ;
VAL_ 2463978716 BMS_MV_Peak_EntladeLeistung 2046 "Init" 2047 "Fehler" ;
VAL_ 2463978716 BMS_MV_Peak_LadeLeistung 2046 "Init" 2047 "Fehler" ;
VAL_ 2463978716 BMS_MV_Peak_EntladeSpannung 254 "Init" 255 "Fehler" ;
VAL_ 2463978716 BMS_MV_Peak_LadeSpannung 254 "Init" 255 "Fehler" ;
VAL_ 2463978717 BMS_MV_Strat_EntladeSpannung 254 "Init" 255 "Fehler" ;
VAL_ 2463978717 BMS_MV_PerfInd_Entladen 1022 "Init" 1023 "Fehler" ;
VAL_ 2463978717 BMS_MV_PerfInd_Laden 1022 "Init" 1023 "Fehler" ;
VAL_ 2463978717 BMS_MV_Max_EntladeLeistung 2046 "Init" 2047 "Fehler" ;
VAL_ 2463978717 BMS_MV_Max_LadeLeistung 2046 "Init" 2047 "Fehler" ;
VAL_ 2463978718 BMS_MV_Strat_LadeSpannung 254 "Init" 255 "Fehler" ;
VAL_ 2463978718 BMS_MV_Max_EntladeStrom_Lim 2046 "Init" 2047 "Fehler" ;
VAL_ 2463978718 BMS_MV_Max_LadeStrom_Lim 2046 "Init" 2047 "Fehler" ;
VAL_ 2463978718 BMS_MV_Min_EntladeSpannung_Lim 254 "Init" 255 "Fehler" ;
VAL_ 2463978718 BMS_MV_Max_LadeSpannung_Lim 254 "Init" 255 "Fehler" ;
VAL_ 2589283523 OBDProtocol_BMS_48V 0 "OBDonUDS" 1 "OBDclassic" 16 "NoOBD" 254 "Init" 255 "Fehler" ;
VAL_ 2589283523 BMS_MV_OBD_Lampe_Anf 0 "Init" 1 "MIL_Request" ;
VAL_ 2589283523 BMS_48V_Indc_StChk 0 "Complete" 1 "NotComplete" ;
VAL_ 2589283523 BMS_48V_Indc_StFail 0 "passiv" 1 "aktiv" ;
VAL_ 2589283523 BMS_MV_Kundenwarnung 0 "keine_Warnung" 1 "Warnung_Temperatur_Level1" 2 "Warnung_Temperatur_Level2" ;
VAL_ 2589283523 BMS_MV_Dauer_EntladeLeistung 2046 "Init" 2047 "Fehler" ;
VAL_ 2589283523 BMS_MV_Dauer_LadeLeistung 2046 "Init" 2047 "Fehler" ;
VAL_ 2589283523 BMS_MV_Dauer_EntladeSpannung 254 "Init" 255 "Fehler" ;
VAL_ 2589283523 BMS_MV_Dauer_LadeSpannung 254 "Init" 255 "Fehler" ;
VAL_ 2589283523 BMS_MV_Dauer_RMS_Strom 254 "Init" 255 "Fehler" ;
VAL_ 2589283524 BMS_MV_TRD_Voltage 0 "keine_Warnung" 1 "Warnung_TRD_Voltage" ;
VAL_ 2589283524 BMS_MV_TRD_Sensfail 0 "Keine_Warnung" 1 "Warnung_TRD_Sensfail" ;
VAL_ 2589283524 BMS_MV_TRD_Temp 0 "keine_Warnung" 1 "Warnung_TRD_Temp" ;
VAL_ 2589283524 BMS_MV_EntladeEnergie 2046 "Init" 2047 "Fehler" ;
VAL_ 2589283524 BMS_MV_LadeEnergie 2046 "Init" 2047 "Fehler" ;
VAL_ 2589283524 BMS_MV_Max_RMS_Strom 254 "Init" 255 "Fehler" ;
VAL_ 2527679928 BMS_NV_OBD_Lampe_Anf 0 "keine_Anforderung" 1 "Anforderung" ;
VAL_ 2527679928 BMS_NV_Indc_StChk 0 "Completed" 1 "NotCompleted" ;
VAL_ 2527679928 BMS_NV_Indc_StFail 0 "passiv_Init" 1 "aktiv" ;
VAL_ 2527679928 OBDProtocol_BMS_NV 0 "OBDonUDS" 1 "OBDclassic" 16 "NoOBD" 254 "Init" 255 "Fehler" ;
VAL_ 902 CHA_Charisma_Taste2_LED 0 "LED_aus" 1 "LED_ein" 2 "LED_blinken" 3 "Fehler" ;
VAL_ 902 CHA_ReqPrgDispSetup 0 "init" 1 "layout_comfort" 2 "layout_eco" 3 "layout_sport" 4 "layout_offroad" 5 "layout_sportplus" 6 "program_6" 7 "program_7" 8 "program_8" 9 "program_9" 10 "program_10" 11 "program_11" 12 "program_12" 13 "program_13" 14 "program_14" 15 "program_15" ;
VAL_ 902 CHA_Current_Mode_FPA 0 "keine_Funktion" 1 "Programm_1" 2 "Programm_2" 3 "Programm_3" 4 "Programm_4" 5 "Programm_5" 6 "Programm_6" 7 "Programm_7" 8 "Programm_8" 9 "Programm_9" 10 "Programm_10" 11 "Programm_11" 12 "Programm_12" 13 "Programm_13" 14 "Programm_14" 15 "Programm_15" 16 "Programm_16" 17 "Programm_17" 18 "Programm_18" 19 "Programm_19" 20 "Programm_20" 21 "Programm_21" 22 "Programm_22" 23 "Programm_23" 24 "Programm_24" 25 "Programm_25" 26 "Programm_26" 27 "Programm_27" 28 "Programm_28" 29 "Programm_29" 30 "Programm_30" 31 "Programm_31" 32 "Programm_32" ;
VAL_ 902 CHA_Eco_Charisma_LED 0 "LED_aus_und_Blinken_aus" 1 "LED_ein_und_Blinken_aus" 2 "LED_ein_und_Blinken_ein_50_percent" 3 "reserviert" ;
VAL_ 902 CHA_Fahrer_Umschaltung 0 "keine_oder_automatische_Umschaltung" 1 "manuelle_Umschaltung" ;
VAL_ 902 CHA_EV_LED 0 "LED_aus" 1 "LED_an" ;
VAL_ 902 CHA_Ziel_FahrPr_AMB 0 "keine_Funktion" 1 "Programm_1" 2 "Programm_2" 3 "Programm_3" 4 "Programm_4" 5 "Programm_5" 6 "Programm_6" 7 "Programm_7" 8 "Programm_8" 9 "Programm_9" 10 "Programm_10" 11 "Programm_11" 12 "Programm_12" 13 "Programm_13" 14 "Programm_14" 15 "Programm_15" ;
VAL_ 902 CHA_Ziel_FahrPr_IVB 0 "keine_Funktion" 1 "Programm_1" 2 "Programm_2" 3 "Programm_3" 4 "Programm_4" 5 "Programm_5" 6 "Programm_6" 7 "Programm_7" 8 "Programm_8" 9 "Programm_9" 10 "Programm_10" 11 "Programm_11" 12 "Programm_12" 13 "Programm_13" 14 "Programm_14" 15 "Programm_15" ;
VAL_ 902 CHA_Kombi_Texte 0 "keine_Anzeige" 1 "Text_1" 2 "Text_2" 3 "Text_3" 4 "Text_4" 5 "Text_5" 6 "Text_6" 7 "Text_7" 8 "Text_8" 9 "Text_9" 10 "Text_10" 11 "Text_11" 12 "Text_12" 13 "Text_13" 14 "Text_14" 15 "Text_15" ;
VAL_ 902 CHA_Ziel_FahrPr_KL 0 "keine_Funktion" 1 "Programm_1" 2 "Programm_2" 3 "Programm_3" 4 "Programm_4" 5 "Programm_5" 6 "Programm_6" 7 "Programm_7" 8 "Programm_8" 9 "Programm_9" 10 "Programm_10" 11 "Programm_11" 12 "Programm_12" 13 "Programm_13" 14 "Programm_14" 15 "Programm_15" ;
VAL_ 902 CHA_Ziel_FahrPr_HSP 0 "keine_Funktion" 1 "Programm_1" 2 "Programm_2" 3 "Programm_3" 4 "Programm_4" 5 "Programm_5" 6 "Programm_6" 7 "Programm_7" 8 "Programm_8" 9 "Programm_9" 10 "Programm_10" 11 "Programm_11" 12 "Programm_12" 13 "Programm_13" 14 "Programm_14" 15 "Programm_15" ;
VAL_ 902 CHA_StCurProfDft 0 "Init" 1 "profile_is_not_configurable" 2 "profile_is_default" 3 "profile_is_not_default" ;
VAL_ 902 CHA_Ziel_FahrPr_RWB 0 "keine_Funktion" 1 "Programm_1" 2 "Programm_2" 3 "Programm_3" 4 "Programm_4" 5 "Programm_5" 6 "Programm_6" 7 "Programm_7" 8 "Programm_8" 9 "Programm_9" 10 "Programm_10" 11 "Programm_11" 12 "Programm_12" 13 "Programm_13" 14 "Programm_14" 15 "Programm_15" ;
VAL_ 902 CHA_Ziel_FahrPr_03_01 0 "keine_Funktion" 1 "Programm_1" 2 "Programm_2" 3 "Programm_3" 4 "Programm_4" 5 "Programm_5" 6 "Programm_6" 7 "Programm_7" 8 "Programm_8" 9 "Programm_9" 10 "Programm_10" 11 "Programm_11" 12 "Programm_12" 13 "Programm_13" 14 "Programm_14" 15 "Programm_15" ;
VAL_ 902 CHA_Ziel_FahrPr_03_02 0 "keine_Funktion" 1 "Programm_1" 2 "Programm_2" 3 "Programm_3" 4 "Programm_4" 5 "Programm_5" 6 "Programm_6" 7 "Programm_7" 8 "Programm_8" 9 "Programm_9" 10 "Programm_10" 11 "Programm_11" 12 "Programm_12" 13 "Programm_13" 14 "Programm_14" 15 "Programm_15" ;
VAL_ 902 CHA_Current_Mode 0 "keine_Funktion" 1 "Programm_1" 2 "Programm_2" 3 "Programm_3" 4 "Programm_4" 5 "Programm_5" 6 "Programm_6" 7 "Programm_7" 8 "Programm_8" 9 "Programm_9" 10 "Programm_10" 11 "Programm_11" 12 "Programm_12" 13 "Programm_13" 14 "Programm_14" 15 "Programm_15" ;
VAL_ 902 CHA_Charge_LED 0 "LED_aus" 1 "LED_ein" ;
VAL_ 902 CHA_Offroad_LED 0 "LED_aus" 1 "LED_ein" 2 "LED_blinken" 3 "Fehler" ;
VAL_ 902 CHA_Kombi_Texte_02 0 "Init" 1 "Text_1" 2 "Text_2" 3 "Text_3" 4 "Text_4" 5 "Text_5" 6 "Text_6" 7 "Text_7" 8 "Text_8" 9 "Text_9" 10 "Text_10" 11 "Text_11" 12 "Text_12" 13 "Text_13" 14 "Text_14" 15 "Text_15" ;
VAL_ 686 DC_IstSpannung_HV 4094 "Init" 4095 "Fehler" ;
VAL_ 686 DC_IstStrom_NV 1022 "Init" 1023 "Fehler" ;
VAL_ 686 DC_IstSpannung_NV 254 "Init" 255 "Fehler" ;
VAL_ 1012 DC_ReserveStrom_NV 1022 "Init" 1023 "Fehler" ;
VAL_ 1012 DC_Verbrauch_Ueberlauf 0 "kein_Ueberlauf" 1 "Ueberlauf" ;
VAL_ 1012 DC_Verlustleistung 62 "Init" 63 "Fehler" ;
VAL_ 1012 DC_HYB_Auslastungsgrad 254 "Init" 255 "Fehler" ;
VAL_ 1485 DC_Temperatur_Alarm 0 "kein_Fehler" 1 "Fehler" ;
VAL_ 1485 DCDC_NV_Indc_StChk 0 "Completed" 1 "NotCompleted" ;
VAL_ 1485 DC_Kl30c_Status 0 "Init" 1 "geschlossen" 2 "offen" 3 "Fehler" ;
VAL_ 1485 DC_Fehlerstatus 0 "Komponente_IO" 1 "Eingeschr_KompFkt_Entlad_defekt" 3 "Eingeschr_KompFkt_Interlock" 4 "Eingeschr_KompFkt_SD" 6 "Keine_Komponentenfunktion" 7 "Init" ;
VAL_ 1485 DC_Peakstrom_verfuegbar 0 "Peakstrom_nicht_verfuegbar" 1 "Peakstrom_verfuegbar" ;
VAL_ 1485 DC_Abregelung_Temperatur 0 "keine_Abregelung" 1 "Abregelung_Temp" ;
VAL_ 1485 DC_Derating 0 "keine_Abregelung" 1 "Abregelung_Ursache_NV" 2 "Abregelung_Ursache_HV" 3 "Abregelung_Ursache_Temp" 4 "Abregelung_Ursache_Intern" ;
VAL_ 1485 DC_OBD_Lampe_Anf 0 "kein_MIL_Request" 1 "MIL_Request" ;
VAL_ 1485 DCDC_NV_Indc_StFail 0 "passiv" 1 "aktiv" ;
VAL_ 1485 DC_Warnlampe_Anf 0 "keine_Anforderung_Warnlampe" 1 "Anforderung_Warnlampe" ;
VAL_ 1485 OBDProtocol_DCDC_NV 0 "OBDonUDS" 1 "OBDclassic" 16 "NoOBD" 254 "Init" 255 "Fehler" ;
VAL_ 1485 DC_SollVolumenstrom 62 "Init" 63 "Fehler" ;
VAL_ 1485 DC_Status_Spgfreiheit_HV 0 "Init" 1 "HV_Komponente_spannungsfrei" 2 "HV_Komp_nicht_spannungsfrei" 3 "Fehler" ;
VAL_ 1485 DC_Temperatur 254 "Init" 255 "Fehler" ;
VAL_ 247 DC_Vorladung_Status 0 "nicht_abgeschlossen" 1 "abgeschlossen" ;
VAL_ 247 DC_Fehler_extern 0 "kein_Fehler" 1 "Fehler" ;
VAL_ 247 DC_Fehler_intern 0 "kein_Fehler" 1 "interner_Fehler_erkannt" ;
VAL_ 247 DC_Status_Spgfreiheit 0 "Init" 1 "HV_Komponente_spannungsfrei" 2 "HV_Komp_nicht_spannungsfrei" 3 "Fehler_nicht_spannungsfrei" ;
VAL_ 247 DC_Status_EoHVL 0 "Init" 1 "Keine_offene_HV_Leitung_erkannt" 2 "offene_HV_Leitung_erkannt" 3 "Fehler" ;
VAL_ 247 DC_IstModus_02 0 "Standby" 1 "HV_On_Vorladen" 2 "Tiefsetzen" 3 "Hochsetzen" 4 "Pruefimpuls_12V" 5 "Fehler" 7 "Initialisierung" ;
VAL_ 247 DC_IstStrom_HV 1022 "Init" 1023 "Fehler" ;
VAL_ 247 DC_IstLeistung_HV 1022 "Init" 1023 "Fehler" ;
VAL_ 1484 DCDC_MV_Peakstrom_verfuegbar 0 "Peakstrom_nicht_verfuegbar" 1 "Peakstrom_verfuegbar" ;
VAL_ 1484 DC_MV_Tiefsetzen_Notbetrieb 0 "Init" 1 "aktiv" ;
VAL_ 1484 DC_MV_Fehlerstatus 0 "Komponente_IO" 3 "Vorwarnung_KompFkt" 5 "Eingeschr_KompFkt_Leistungsred" 6 "Keine_Komponentenfunktion" 7 "Init" ;
VAL_ 1484 DC_MV_12V_Bordnetzstuetzung 0 "Init" 1 "aktiv" ;
VAL_ 1484 DC_MV_Abregelung_Temperatur 0 "keine_Abregelung" 1 "Abregelung_Temp" ;
VAL_ 1484 DC_MV_IstModus_02 0 "Standby" 1 "MV_On" 2 "Tiefsetzen" 3 "Hochsetzen" 4 "Startunterstuetzung_48V" 5 "Fehler" 6 "Startunterstuetzung_12V" 7 "Init" 9 "MV_On_Notbetrieb" 10 "Tiefsetzen_Notbetrieb" 11 "Pruefpuls_12V" 13 "Reaktivierung_BMS" ;
VAL_ 1484 DC_MV_Derating 0 "keine_Abregelung" 1 "Abregelung_Ursache_NV" 2 "Abregelung_Ursache_MV" 3 "Abregelung_Ursache_Temp" 4 "Abregelung_Ursache_Intern" ;
VAL_ 1484 DC_MV_Temperatur 254 "Init" 255 "Fehler" ;
VAL_ 1714 DGN_Verlernzaehler 255 "ungültiger Zählerstand oder kein gültiger Fahrzyklus" ;
VAL_ 1714 KBI_Kilometerstand 1048574 "Init" 1048575 "Fehler" ;
VAL_ 1714 UH_Monat 0 "Init" 14 "Relatives_Datum" 15 "Fehler" ;
VAL_ 1714 UH_Tag 0 "Init" ;
VAL_ 1714 Vehicle_Driving_Cycle 0 "kein_Driving_Cycle_erkannt" 1 "Driving_Cycle_erkannt" ;
VAL_ 1714 Kombi_02_alt 0 "aktuell" 1 "veraltet" ;
VAL_ 1714 Uhrzeit_01_alt 0 "aktuell" 1 "veraltet" ;
VAL_ 851 DiETa_Status 0 "DiETa_betriebsbereit" 2 "Init" 3 "Fehler_oder_defekt" ;
VAL_ 851 DiETa_ResponseError 0 "normal" 1 "Fehler" ;
VAL_ 851 DiETa_Car 0 "Init_oder_nicht_verbaut" 1 "Taste_unbetaetigt" 2 "Taste_betaetigt" 3 "Fehler" ;
VAL_ 851 DiETa_Klima 0 "Init_oder_nicht_verbaut" 1 "Taste_unbetaetigt" 2 "Taste_betaetigt" 3 "Fehler" ;
VAL_ 851 DiETa_Mode 0 "Init_oder_nicht_verbaut" 1 "Taste_unbetaetigt" 2 "Taste_betaetigt" 3 "Fehler" ;
VAL_ 851 DiETa_Parken 0 "Init_oder_nicht_verbaut" 1 "Taste_unbetaetigt" 2 "Taste_betaetigt" 3 "Fehler" ;
VAL_ 851 DiETa_FSH_Taste 0 "Init_oder_nicht_verbaut" 1 "Taste_unbetaetigt" 2 "Taste_betaetigt" 3 "Fehler" ;
VAL_ 851 DiETa_HSH_Taste 0 "Init_oder_nicht_verbaut" 1 "Taste_unbetaetigt" 2 "Taste_betaetigt" 3 "Fehler" ;
VAL_ 851 DiETa_Warnblink_Taste 0 "Init_oder_nicht_verbaut" 1 "Taste_unbetaetigt" 2 "Taste_betaetigt" 3 "Fehler" ;
VAL_ 851 DiETa_FAS_Stufe 0 "Init_oder_nicht_verbaut" 1 "Taste_unbetaetigt" 2 "Taste_betaetigt" 3 "Fehler" ;
VAL_ 851 DiETa_PAO_ON_Status 0 "LED_Aus" 1 "LED_Ein" 2 "LED_Blinkt" 3 "LED_defekt" ;
VAL_ 851 DiETa_PAO_OFF_Status 0 "LED_Aus" 1 "LED_Ein" 2 "LED_Blinkt" 3 "LED_defekt" ;
VAL_ 851 DiETa_Defrost_Taste 0 "Init_oder_nicht_verbaut" 1 "Taste_unbetaetigt" 2 "Taste_betaetigt" 3 "Fehler" ;
VAL_ 851 DiETa_Mode2 0 "Init_oder_nicht_verbaut" 1 "Taste_unbetaetigt" 2 "Taste_betaetigt" 3 "Fehler" ;
VAL_ 851 DiETa_Lock_Unlock_Taste 0 "Init" 1 "Taste_unbetaetigt" 2 "Taste_betaetigt_unlock" 3 "Taste_betaetigt_lock" 4 "Reserviert" 5 "Reserviert" 6 "Reserviert" 7 "Fehler" ;
VAL_ 851 DiETa_Mode_roh 0 "Taste_unbetaetigt" 1 "Taste_betaetigt" ;
VAL_ 851 ESP_Off_Taster 0 "Taste_nicht_betaetigt" 1 "Taste_entprellt_betaetigt" 2 "Init_oder_nicht_verbaut" 3 "Fehler" ;
VAL_ 851 DiETa_Touch_Event 0 "nicht_betaetigt" 1 "Tippen" 2 "Wischen_Slide" 3 "Geste" 4 "Doppeltippen" 5 "Longpress_1" 6 "Longpress_2" 7 "Longpress_3" 8 "Press" 9 "Strongpress" 10 "reserviert" 11 "reserviert" 12 "reserviert" 13 "reserviert" 14 "Taktgeber_Inkrement" 15 "Fehler" ;
VAL_ 1520 DI_KL_58xd 254 "Init" 255 "Fehler" ;
VAL_ 1520 DI_KL_58xs 126 "Init" 127 "Fehler" ;
VAL_ 1520 DI_KL_58xt 126 "Init" 127 "Fehler" ;
VAL_ 1520 BCM1_Stellgroesse_Kl_58s 125 "Nicht_verbaut" 126 "Init" 127 "Fehler" ;
VAL_ 1603 KBI_Einheit_Datum 0 "Tag/Monat/Jahr" 1 "Monat/Tag/Jahr" 2 "Jahr/Monat/Tag" 3 "reserviert" ;
VAL_ 1603 KBI_Einheit_Druck 0 "Druckangabe in bar" 1 "Druckangabe in psi" 2 "Druckangabe in kPa" 3 "tbd." ;
VAL_ 1603 KBI_Einheit_Streckenanz 0 "Kilometer" 1 "Meilen" ;
VAL_ 1603 KBI_MFA_v_Einheit_02 0 "kmh" 1 "mph" ;
VAL_ 1603 KBI_Einheit_Temp 0 "Grad Celsius °C" 1 "Grad Fahrenheit °F" ;
VAL_ 1603 KBI_Einheit_Uhrzeit 0 "24h" 1 " 12h AM/PM" ;
VAL_ 1603 KBI_Einheit_Verbrauch 0 "mpg UK" 1 "mpg USA" 2 "Liter/100km" 3 "km/Liter" ;
VAL_ 1603 KBI_Einheit_Volumen 0 "Liter" 1 "Gallonen UK" 2 "Gallonen USA" 3 "reserviert" ;
VAL_ 1603 KBI_Einheit_Verbrauch_elektr 0 "kWh_pro_100km" 1 "km_pro_kWh" 2 "kWh_pro_100mls" 3 "mls_pro_kWh" 4 "MPGe" ;
VAL_ 1603 KBI_Einheit_Tacho 0 "km/h" 1 "mph" ;
VAL_ 1603 KBI_Einheit_Verbrauch_Gas 0 "kg_per_100km" 1 "km_per_kg" 2 "m3_per_100km" 3 "km_per_m3" 4 "miles_per_lbs" 5 "miles_per_yard3" 6 "miles_per_kg" 7 "miles_per_m3" 8 "miles_per_gallon_equivalent_US" ;
VAL_ 1603 KBI_Einheit_Masse 0 "kg" 1 "lbs" 2 "reserviert" ;
VAL_ 2527679743 ELF_AbfahrtstimerJahr 4095 "Init" ;
VAL_ 2527679743 ELF_AbfahrtstimerMonat 15 "Init" ;
VAL_ 2527679743 ELF_AbfahrtstimerTag 0 "Init" ;
VAL_ 2527679743 ELF_AbfahrtstimerStunde 31 "Init" ;
VAL_ 2527679743 ELF_AbfahrtstimerMinute 63 "Init" ;
VAL_ 2527679743 ELF_AbfahrtstimerAktiv 0 "Init" 1 "Timer_nicht_aktiv" 2 "Timer_aktiv" ;
VAL_ 2527679743 ELF_KundenwunschKlimatisierung 0 "Keine_Klimatierung" 1 "Aktivierte_Klimatisierung" 2 "Init" ;
VAL_ 782 ELF_Ladestrategie 0 "keine" 1 "Eigenstrom" 2 "Preisschwelle" 3 "Nur VoKo" 4 "Sofortladen" 5 "Nur BLZ" 6 "Timer ohne BLZ" 7 "Timer mit BLZ" 8 "Koord_Preise_SCR_Leistung_max" 9 "Koord_Preise_max_Leistung_EMS" 10 "Koord_Preise_SCR_Leistung_EMS" 11 "Koord_Preise_EMS_Leistung_EMS" 12 "Reserve" 13 "Reserve" 14 "Reserve" 15 "Init" ;
VAL_ 782 ELF_StatusLadestrategie 0 "Idle" 1 "Ermittlung Ladestrategie aktiv" 2 "LPE angefordert" 3 "LPE aktiv" 4 "LPU angefordert" 5 "LPU aktiv" 6 "ELF beendet" 7 "ELF abgebrochen" 8 "Reserve" 9 "Reserve" 10 "Reserve" 11 "Reserve" 12 "Reserve" 13 "Reserve" 14 "Reserve" 15 "Fehler" ;
VAL_ 782 ELF_PLTabDatenquelle 0 "keine PLTabellen vorhanden" 1 "Ladesaeule Connect" 2 "EMS direkt" 3 "Tarifdatendienst" 4 "Reserve" 5 "Reserve" ;
VAL_ 782 ELF_StatusAbfragePLTab 0 "Inaktiv" 1 "Abfrage_laeuft" 2 "Abfrage_abgeschlossen" 3 "Fehler" 4 "Reserve" 5 "Reserve" 6 "Reserve" 7 "Reserve" ;
VAL_ 782 ELF_StatusLadeplanerstellung 0 "Idle" 1 "ELPEV angefordert" 2 "ELPEV aktiv" 3 "LPE aktiv" 4 "LPE beendet" 5 "LPE abgebrochen" 6 "APLI angefordert" 7 "Initale Energieabfrage" 8 "Reserve" 9 "Reserve" 10 "Reserve" 11 "Reserve" 12 "Reserve" 13 "Reserve" 14 "Reserve" 15 "Reserve" ;
VAL_ 782 ELF_EnergiebedarfZielSoc 4095 "Keine_Angabe" ;
VAL_ 782 ELF_EnergiebedarfMaxSoc 4095 "Keine_Angabe" ;
VAL_ 782 ELF_EnergiebedarfMinSoc 4095 "Keine_Angabe" ;
VAL_ 782 ELF_PLTabellenGefordert 0 "PLTabellen von ELF nicht angefordert" 1 "PLTabellen von ELF angefordert und verarbeitbar" ;
VAL_ 782 ELF_EvNeuverhandlung 0 "keine_Anforderung" 1 "Anforderung_Neuverhandlung" ;
VAL_ 782 ELF_EigenstromGefordert 0 "keine Nutzung Eigenstrom gewünscht" 1 "Nutzung Eigenstrom gewünscht" ;
VAL_ 782 ELF_ErwLadenAnforderung 0 "ELF_Kundenwunsch_nicht_aktiv" 1 "ELF_Kundenwunsch_aktiv" ;
VAL_ 782 ELF_AnforderungWlanVerbindung 0 "Init" 1 "keine_WLAN_Anforderung" 2 "dauerhafte_WLAN_Anforderung" 5 "zyklisches_Wecken_5min" 10 "zyklisches_Wecken_10min" 15 "zyklisches_Wecken_15min" 20 "zyklisches_Wecken_20min" 25 "zyklisches_Wecken_25min" 30 "zyklisches_Wecken_30min" 45 "zyklisches_Wecken_45min" 60 "zyklisches_Wecken_60min" 90 "zyklisches_Wecken_90min" 120 "zyklisches_Wecken_120min" ;
VAL_ 192 EM1_Istmodus 0 "Standby" 1 "Momentenreg" 2 "Int_Drehzahlreg" 3 "Spannungsreg" 4 "Ext_Drehzahlreg" 5 "Inverter_Fehler" 6 "Kalibrierung" 7 "Sonderbremsbetrieb" 8 "Freilauf" 9 "Autonome_Synchronisation" 15 "Initialisierung" ;
VAL_ 192 EM1_IstMoment 4094 "Init" 4095 "Fehler" ;
VAL_ 192 EM1_Moment_AR_Eingriff 4094 "Init" 4095 "Fehler" ;
VAL_ 192 EM1_IstDrehzahl 32766 "Init" 32767 "Fehler" ;
VAL_ 192 EM1_AR_aktiv 0 "Init" 1 "Ruckeldaempfer_aktiv" ;
VAL_ 192 EM1_IstSpannung 4094 "Init" 4095 "Fehler" ;
VAL_ 192 EM1_Strom_HV 4094 "Init" 4095 "Fehler" ;
VAL_ 192 EM1_Max_Moment 2046 "Init" 2047 "Fehler" ;
VAL_ 192 EM1_ErwGrenzen_aktiv 0 "kein_extended_Range" 1 "extended_Range" ;
VAL_ 192 EM1_Min_Moment 2046 "Init" 2047 "Fehler" ;
VAL_ 192 EM1_Fehler_ElAntriebAbschaltung 0 "Init" 1 "Abschaltung" ;
VAL_ 192 EM1_Max_Moment_Lim 2046 "Init" 2047 "Fehler" ;
VAL_ 192 EM1_Fehler_Notabschaltung 0 "kein_Fehler" 1 "Fehler" ;
VAL_ 192 EM1_Min_Moment_Lim 2046 "Init" 2047 "Fehler" ;
VAL_ 192 EM1_Status_DrzEingriff 0 "kein_Eingriff" 1 "Eingriff_Max_Drehzahlregler" 2 "Eingriff_Min_Drehzahlregler" 3 "Fehler" ;
VAL_ 192 EM1_Mom_DrzEingriff 2046 "Init" 2047 "Fehler" ;
VAL_ 192 EM1_Raddrehzahl_links 8188 "reserviert" 8189 "reserviert" 8190 "Init" 8191 "Fehler" ;
VAL_ 192 EM1_Raddrehzahl_rechts 8188 "reserviert" 8189 "reserviert" 8190 "Init" 8191 "Fehler" ;
VAL_ 192 EM1_Max_Moment_Gesamt 2046 "Init" 2047 "Fehler" ;
VAL_ 192 EM1_Min_Moment_Gesamt 2046 "Init" 2047 "Fehler" ;
